BU_:  Airbag BAP_Tester ICAS1_Gateway ICAS1_KommunikationsServer LE1 LE2 Motor_BEV Schaltbetaetigung

BU_:  Airbag BAP_Tester ICAS1_Gateway ICAS1_KommunikationsServer LE1 LE2 Motor_BEV Schaltbetaetigung

BO_ 333 ACC_18: 32 ICAS1_Gateway
 SG_ ACC_18_CRC  : 0|8@1+ (1.000000,0.000000) [0.000000|255.000000] "" Motor_BEV
 SG_ ACC_18_BZ  : 8|4@1+ (1.000000,0.000000) [0.000000|15.000000] "" Motor_BEV
 SG_ ACC_limitierte_Anfahrdyn  : 12|1@0- (1.000000,0.000000) [0.000000|1.000000] "" Motor_BEV
 SG_ ACC_nachtr_Stopp_Anf  : 13|1@1+ (1.000000,0.000000) [0.000000|1.000000] "" Vector__XXX
 SG_ ACC_DynErhoehung  : 14|1@1+ (1.000000,0.000000) [0.000000|1.000000] "" Motor_BEV
 SG_ ACC_Freilaufstrategie_TSK  : 15|1@1+ (1.000000,0.000000) [0.000000|1.000000] "" Motor_BEV
 SG_ ACC_zul_Regelabw_unten  : 16|6@1+ (0.024000,0.000000) [0.000000|1.512000] "Unit_MeterPerSeconSquar" Motor_BEV
 SG_ ACC_StartStopp_Info  : 22|2@1+ (1.000000,0.000000) [0.000000|3.000000] "" Vector__XXX
 SG_ ACC_Sollbeschleunigung_02  : 24|11@1+ (0.005000,-7.220000) [-7.220000|3.005000] "Unit_MeterPerSeconSquar" Motor_BEV
 SG_ ACC_zul_Regelabw_oben  : 35|5@1+ (0.062500,0.000000) [0.000000|1.937500] "Unit_MeterPerSeconSquar" Motor_BEV
 SG_ ACC_neg_Sollbeschl_Grad_02  : 40|8@1+ (0.050000,0.000000) [0.000000|12.750000] "Unit_MeterPerCubicSecon" Motor_BEV
 SG_ ACC_pos_Sollbeschl_Grad_02  : 48|8@1+ (0.050000,0.000000) [0.000000|12.750000] "Unit_MeterPerCubicSecon" Motor_BEV
 SG_ ACC_Anfahren  : 56|1@1+ (1.000000,0.000000) [0.000000|1.000000] "" Motor_BEV
 SG_ ACC_Anhalten  : 57|1@1+ (1.000000,0.000000) [0.000000|1.000000] "" Motor_BEV
 SG_ ACC_Typ  : 58|2@1+ (1.000000,0.000000) [0.000000|3.000000] "" Motor_BEV
 SG_ ACC_Status_ACC  : 60|3@1+ (1.000000,0.000000) [0.000000|7.000000] "" Motor_BEV
 SG_ ACC_Minimale_Bremsung  : 63|1@1+ (1.000000,0.000000) [0.000000|1.000000] "" Motor_BEV
 SG_ ACC_Anhalteweg  : 64|11@1+ (0.010000,0.000000) [0.000000|20.450000] "Unit_Meter" Vector__XXX
 SG_ ACC_Boost  : 75|1@1+ (1.000000,0.000000) [0.000000|1.000000] "" Vector__XXX
 SG_ ACC_Freilauf_Anf  : 76|1@1+ (1.000000,0.000000) [0.000000|1.000000] "" Vector__XXX
 SG_ ACC_Anforderung_HMS  : 77|3@1+ (1.000000,0.000000) [0.000000|7.000000] "" Vector__XXX
 SG_ ACC_Folgebeschl  : 80|8@1+ (0.030000,-4.600000) [-4.600000|2.990000] "Unit_MeterPerSeconSquar" Motor_BEV
 SG_ ACC_Freilauf_Info  : 88|2@1+ (1.000000,0.000000) [0.000000|3.000000] "" Motor_BEV
 SG_ ACC_Tempolimitassistent_Ein  : 90|1@1+ (1.000000,0.000000) [0.000000|1.000000] "" Vector__XXX
 SG_ ACC_FoD_Status  : 91|2@1+ (1.000000,0.000000) [0.000000|3.000000] "" Motor_BEV
 SG_ vESC_Verz_Anf  : 232|4@1+ (0.500000,0.000000) [0.000000|3.500000] "Unit_MeterPerSeconSquar" Vector__XXX
 SG_ RDR_v_ueber_Grund  : 236|12@1+ (0.100000,0.000000) [0.000000|409.000000] "Unit_KiloMeterPerHour" Vector__XXX
 SG_ RDR_v_ueber_Grund_Genauigkeit  : 248|6@1+ (0.100000,0.000000) [0.000000|6.000000] "Unit_KiloMeterPerHour" Vector__XXX
 SG_ RDR_v_ueber_Grund_Fahrtrichtung  : 254|2@1+ (1.000000,0.000000) [0.000000|3.000000] "" Vector__XXX

BO_ 2527679682 ACC_ASM_01: 8 ICAS1_Gateway
 SG_ ACC_ASM_Ereignis  : 0|8@1+ (1.000000,0.000000) [1.000000|254.000000] "" Airbag
 SG_ ACC_ASM_Zeitstempel  : 8|8@1+ (0.080000,0.000000) [0.000000|20.320000] "Unit_Secon" Airbag
 SG_ ACC_ASM_Data_1  : 16|8@1+ (1.000000,0.000000) [0.000000|255.000000] "" Airbag
 SG_ ACC_ASM_Data_2  : 24|8@1+ (1.000000,0.000000) [0.000000|255.000000] "" Airbag
 SG_ ACC_ASM_Data_3  : 32|8@1+ (1.000000,0.000000) [0.000000|255.000000] "" Airbag
 SG_ ACC_ASM_Data_4  : 40|8@1+ (1.000000,0.000000) [0.000000|255.000000] "" Airbag
 SG_ ACC_ASM_Data_5  : 48|8@1+ (1.000000,0.000000) [0.000000|255.000000] "" Airbag
 SG_ ACC_ASM_Data_6  : 56|8@1+ (1.000000,0.000000) [0.000000|255.000000] "" Airbag

BO_ 64 Airbag_01: 8 Airbag
 SG_ Airbag_01_CRC  : 0|8@1+ (1.000000,0.000000) [0.000000|255.000000] "" ICAS1_Gateway LE1 LE2 Motor_BEV
 SG_ Airbag_01_BZ  : 8|4@1+ (1.000000,0.000000) [0.000000|15.000000] "" ICAS1_Gateway LE1 LE2 Motor_BEV
 SG_ AB_RGS_Anst  : 12|4@1+ (1.000000,0.000000) [0.000000|15.000000] "" ICAS1_Gateway ICAS1_KommunikationsServer
 SG_ AB_Front_Crash  : 16|1@1+ (1.000000,0.000000) [0.000000|1.000000] "" ICAS1_Gateway
 SG_ AB_Heck_Crash  : 17|1@1+ (1.000000,0.000000) [0.000000|1.000000] "" ICAS1_Gateway
 SG_ AB_SF_Crash  : 18|1@1+ (1.000000,0.000000) [0.000000|1.000000] "" ICAS1_Gateway
 SG_ AB_SB_Crash  : 19|1@1+ (1.000000,0.000000) [0.000000|1.000000] "" ICAS1_Gateway
 SG_ AB_Rollover_Crash  : 20|1@1+ (1.000000,0.000000) [0.000000|1.000000] "" ICAS1_Gateway
 SG_ AB_Crash_Int  : 21|3@1+ (1.000000,0.000000) [0.000000|7.000000] "" ICAS1_Gateway ICAS1_KommunikationsServer Motor_BEV
 SG_ AB_Lampe  : 24|1@1+ (1.000000,0.000000) [0.000000|1.000000] "" ICAS1_Gateway ICAS1_KommunikationsServer
 SG_ AB_Deaktiviert  : 25|1@1+ (1.000000,0.000000) [0.000000|1.000000] "" ICAS1_Gateway
 SG_ AB_VB_deaktiviert  : 26|1@1+ (1.000000,0.000000) [0.000000|1.000000] "" ICAS1_Gateway
 SG_ AB_Systemfehler  : 27|1@1+ (1.000000,0.000000) [0.000000|1.000000] "" ICAS1_Gateway ICAS1_KommunikationsServer
 SG_ AB_Diagnose  : 28|1@1+ (1.000000,0.000000) [0.000000|1.000000] "" ICAS1_Gateway
 SG_ AB_Stellgliedtest  : 29|1@1+ (1.000000,0.000000) [0.000000|1.000000] "" ICAS1_Gateway
 SG_ AB_Erh_Auf_VB  : 30|2@1+ (1.000000,0.000000) [0.000000|3.000000] "" ICAS1_Gateway
 SG_ AB_Gurtwarn_VF  : 32|1@1+ (1.000000,0.000000) [0.000000|1.000000] "" ICAS1_Gateway ICAS1_KommunikationsServer
 SG_ AB_Gurtwarn_VB  : 33|1@1+ (1.000000,0.000000) [0.000000|1.000000] "" ICAS1_Gateway ICAS1_KommunikationsServer
 SG_ AB_Anzeige_Fussg  : 34|2@1+ (1.000000,0.000000) [0.000000|3.000000] "" ICAS1_Gateway
 SG_ AB_Texte_AKS  : 36|2@1+ (1.000000,0.000000) [0.000000|3.000000] "" ICAS1_Gateway
 SG_ AB_PAO_Leuchte_Anf  : 38|1@1+ (1.000000,0.000000) [0.000000|1.000000] "" ICAS1_Gateway
 SG_ AB_MKB_gueltig  : 39|1@1+ (1.000000,0.000000) [0.000000|1.000000] "" ICAS1_Gateway
 SG_ AB_MKB_Anforderung  : 40|1@1+ (1.000000,0.000000) [0.000000|1.000000] "" ICAS1_Gateway
 SG_ AB_Versorgungsspannung  : 41|1@1+ (1.000000,0.000000) [0.000000|1.000000] "" ICAS1_Gateway
 SG_ AB_Deaktivierung_HV  : 42|3@1+ (1.000000,0.000000) [0.000000|7.000000] "" ICAS1_Gateway ICAS1_KommunikationsServer LE1 LE2 Motor_BEV
 SG_ AB_EDR_Trigger  : 45|2@1+ (1.000000,0.000000) [0.000000|3.000000] "" ICAS1_Gateway
 SG_ AB_Belegung_VF  : 47|2@1+ (1.000000,0.000000) [0.000000|3.000000] "" ICAS1_Gateway
 SG_ AB_Gurtschloss_FA_ext  : 49|3@1+ (1.000000,0.000000) [0.000000|7.000000] "" ICAS1_Gateway
 SG_ AB_Belegung_VF_ext  : 52|3@1+ (1.000000,0.000000) [0.000000|7.000000] "" ICAS1_Gateway
 SG_ ASM_Masterzeit  : 56|8@1+ (0.080000,0.000000) [0.000000|20.320000] "Unit_Secon" ICAS1_Gateway

BO_ 1312 Airbag_02: 8 Airbag
 SG_ Airbag_02_CRC  : 0|8@1+ (1.000000,0.000000) [0.000000|255.000000] "" ICAS1_Gateway Motor_BEV
 SG_ Airbag_02_BZ  : 8|4@1+ (1.000000,0.000000) [0.000000|15.000000] "" ICAS1_Gateway Motor_BEV
 SG_ LoGeWa_Event_Kombiwarnung  : 12|4@1+ (1.000000,0.000000) [0.000000|15.000000] "" ICAS1_Gateway
 SG_ AB_Anforderung_eCall  : 16|1@1+ (1.000000,0.000000) [0.000000|1.000000] "" ICAS1_Gateway
 SG_ AB_Anprall_Seite_Beifahrer  : 17|1@1+ (1.000000,0.000000) [0.000000|1.000000] "" ICAS1_Gateway ICAS1_KommunikationsServer
 SG_ AB_Anprall_Rollover  : 18|1@1+ (1.000000,0.000000) [0.000000|1.000000] "" ICAS1_Gateway ICAS1_KommunikationsServer
 SG_ AB_Anprall_FGS  : 19|1@1+ (1.000000,0.000000) [0.000000|1.000000] "" ICAS1_Gateway ICAS1_KommunikationsServer
 SG_ AB_Anprall_Front_Beifahrer  : 20|1@1+ (1.000000,0.000000) [0.000000|1.000000] "" ICAS1_Gateway ICAS1_KommunikationsServer
 SG_ AB_Anprall_Front_Fahrer  : 21|1@1+ (1.000000,0.000000) [0.000000|1.000000] "" ICAS1_Gateway ICAS1_KommunikationsServer
 SG_ AB_Anprall_Heck_Beifahrer  : 22|1@1+ (1.000000,0.000000) [0.000000|1.000000] "" ICAS1_Gateway ICAS1_KommunikationsServer
 SG_ AB_Anprall_Heck_Fahrer  : 23|1@1+ (1.000000,0.000000) [0.000000|1.000000] "" ICAS1_Gateway ICAS1_KommunikationsServer
 SG_ AB_Wickelklappung_Reihe2_MI  : 24|2@1+ (1.000000,0.000000) [0.000000|3.000000] "" ICAS1_Gateway
 SG_ AB_Belegung_VB  : 26|2@1+ (1.000000,0.000000) [0.000000|3.000000] "" ICAS1_Gateway
 SG_ AB_Abschaltanf_SIH_BF  : 28|1@1+ (1.000000,0.000000) [0.000000|1.000000] "" ICAS1_Gateway
 SG_ AB_Anprall_Seite_Fahrer  : 29|1@1+ (1.000000,0.000000) [0.000000|1.000000] "" ICAS1_Gateway ICAS1_KommunikationsServer
 SG_ SC_PAO_Schriftzug_Anf  : 30|2@1+ (1.000000,0.000000) [0.000000|3.000000] "" ICAS1_Gateway
 SG_ SC_PAO_ON_Anf  : 32|2@1+ (1.000000,0.000000) [0.000000|3.000000] "" ICAS1_Gateway
 SG_ SC_PAO_OFF_Anf  : 34|2@1+ (1.000000,0.000000) [0.000000|3.000000] "" ICAS1_Gateway
 SG_ AB_Crashschwere  : 36|3@1+ (1.000000,0.000000) [0.000000|7.000000] "" ICAS1_Gateway ICAS1_KommunikationsServer
 SG_ AB_Anforderung_USM  : 39|1@1+ (1.000000,0.000000) [0.000000|1.000000] "" ICAS1_Gateway
 SG_ AB_Gurtschloss_FA  : 40|2@1+ (1.000000,0.000000) [0.000000|3.000000] "" ICAS1_Gateway ICAS1_KommunikationsServer Motor_BEV
 SG_ AB_Gurtschloss_BF  : 42|2@1+ (1.000000,0.000000) [0.000000|3.000000] "" ICAS1_Gateway ICAS1_KommunikationsServer
 SG_ AB_Gurtschloss_Reihe2_FA  : 44|2@1+ (1.000000,0.000000) [0.000000|3.000000] "" ICAS1_Gateway ICAS1_KommunikationsServer
 SG_ AB_Gurtschloss_Reihe2_MI  : 46|2@1+ (1.000000,0.000000) [0.000000|3.000000] "" ICAS1_Gateway ICAS1_KommunikationsServer
 SG_ AB_Gurtschloss_Reihe2_BF  : 48|2@1+ (1.000000,0.000000) [0.000000|3.000000] "" ICAS1_Gateway ICAS1_KommunikationsServer
 SG_ AB_Gurtschloss_Reihe3_FA  : 50|2@1+ (1.000000,0.000000) [0.000000|3.000000] "" ICAS1_Gateway ICAS1_KommunikationsServer
 SG_ AB_Gurtschloss_Reihe3_MI  : 52|2@1+ (1.000000,0.000000) [0.000000|3.000000] "" ICAS1_Gateway ICAS1_KommunikationsServer
 SG_ AB_Gurtschloss_Reihe3_BF  : 54|2@1+ (1.000000,0.000000) [0.000000|3.000000] "" ICAS1_Gateway ICAS1_KommunikationsServer
 SG_ AB_Sitzpos_Sens_FA  : 56|2@1+ (1.000000,0.000000) [0.000000|3.000000] "" ICAS1_Gateway
 SG_ AB_Sitzpos_Sens_BF  : 58|2@1+ (1.000000,0.000000) [0.000000|3.000000] "" ICAS1_Gateway
 SG_ AB_Wickelklappung_Reihe2_BF  : 60|2@1+ (1.000000,0.000000) [0.000000|3.000000] "" ICAS1_Gateway
 SG_ AB_Wickelklappung_Reihe2_FA  : 62|2@1+ (1.000000,0.000000) [0.000000|3.000000] "" ICAS1_Gateway

BO_ 65 Airbag_03: 8 Airbag
 SG_ Airbag_03_CRC  : 0|8@1+ (1.000000,0.000000) [0.000000|255.000000] "" ICAS1_Gateway
 SG_ Airbag_03_BZ  : 8|4@1+ (1.000000,0.000000) [0.000000|15.000000] "" ICAS1_Gateway
 SG_ AB_MKB_Safing  : 63|1@1+ (1.000000,0.000000) [0.000000|1.000000] "" ICAS1_Gateway

BO_ 1349 Airbag_04: 8 Airbag
 SG_ AB_Gurtwarn_Reihe4_FA  : 14|2@1+ (1.000000,0.000000) [0.000000|3.000000] "" ICAS1_Gateway ICAS1_KommunikationsServer
 SG_ AB_Gurtwarn_Reihe4_BF  : 16|2@1+ (1.000000,0.000000) [0.000000|3.000000] "" ICAS1_Gateway ICAS1_KommunikationsServer
 SG_ AB_Gurtwarn_Reihe4_MI  : 18|2@1+ (1.000000,0.000000) [0.000000|3.000000] "" ICAS1_Gateway ICAS1_KommunikationsServer
 SG_ AB_Gurtwarn_Reihe2_FA  : 20|2@1+ (1.000000,0.000000) [0.000000|3.000000] "" ICAS1_Gateway ICAS1_KommunikationsServer
 SG_ AB_Gurtwarn_Reihe2_BF  : 22|2@1+ (1.000000,0.000000) [0.000000|3.000000] "" ICAS1_Gateway ICAS1_KommunikationsServer
 SG_ AbstWarn_MV_FAS_Fkt_Status  : 24|2@1+ (1.000000,0.000000) [0.000000|3.000000] "" ICAS1_Gateway
 SG_ WarnBrems_Charisma_Status  : 26|2@1+ (1.000000,0.000000) [0.000000|3.000000] "" ICAS1_Gateway
 SG_ WarnBrems_Charisma_FahrPr  : 28|4@1+ (1.000000,0.000000) [0.000000|15.000000] "" ICAS1_Gateway
 SG_ AB_Gurtwarn_Reihe2_MI  : 32|2@1+ (1.000000,0.000000) [0.000000|3.000000] "" ICAS1_Gateway ICAS1_KommunikationsServer
 SG_ AB_Gurtwarn_Reihe3_FA  : 34|2@1+ (1.000000,0.000000) [0.000000|3.000000] "" ICAS1_Gateway ICAS1_KommunikationsServer
 SG_ AB_Gurtwarn_Reihe3_MI  : 36|2@1+ (1.000000,0.000000) [0.000000|3.000000] "" ICAS1_Gateway ICAS1_KommunikationsServer
 SG_ AB_Gurtwarn_Reihe3_BF  : 38|2@1+ (1.000000,0.000000) [0.000000|3.000000] "" ICAS1_Gateway ICAS1_KommunikationsServer
 SG_ LGI_FAS_Fkt_Status  : 40|2@1+ (1.000000,0.000000) [0.000000|3.000000] "" ICAS1_Gateway
 SG_ PreCrash_FAS_Fkt_Status  : 42|3@1+ (1.000000,0.000000) [0.000000|7.000000] "" ICAS1_Gateway
 SG_ AB_SBR_hinten_verbau  : 48|2@1+ (1.000000,0.000000) [0.000000|3.000000] "" ICAS1_Gateway ICAS1_KommunikationsServer
 SG_ AWV_Einstellung_System_ASG  : 51|1@1+ (1.000000,0.000000) [0.000000|1.000000] "" ICAS1_Gateway
 SG_ AWV_Einstellung_Warnung_ASG  : 52|3@1+ (1.000000,0.000000) [0.000000|7.000000] "" ICAS1_Gateway
 SG_ SC_PreSense_Modus_Warnung_NV  : 55|3@1+ (1.000000,0.000000) [0.000000|7.000000] "" ICAS1_Gateway
 SG_ SC_PreSense_Modus_Warnung_MV  : 58|3@1+ (1.000000,0.000000) [0.000000|7.000000] "" ICAS1_Gateway
 SG_ SC_PreSense_Modus_System_MV  : 61|1@1+ (1.000000,0.000000) [0.000000|1.000000] "" ICAS1_Gateway
 SG_ SC_PreSense_Modus_System_NV  : 62|1@1+ (1.000000,0.000000) [0.000000|1.000000] "" ICAS1_Gateway
 SG_ SC_PreSense_Modus_System_KAS  : 63|1@1+ (1.000000,0.000000) [0.000000|1.000000] "" ICAS1_Gateway

BO_ 2527679722 Airbag_06: 8 Airbag
 SG_ AB_Gurtschloss_Reihe4_FA  : 12|2@1+ (1.000000,0.000000) [0.000000|3.000000] "" ICAS1_Gateway ICAS1_KommunikationsServer
 SG_ AB_Gurtschloss_Reihe4_BF  : 14|2@1+ (1.000000,0.000000) [0.000000|3.000000] "" ICAS1_Gateway ICAS1_KommunikationsServer
 SG_ AB_Gurtschloss_Reihe4_MI  : 16|2@1+ (1.000000,0.000000) [0.000000|3.000000] "" ICAS1_Gateway ICAS1_KommunikationsServer

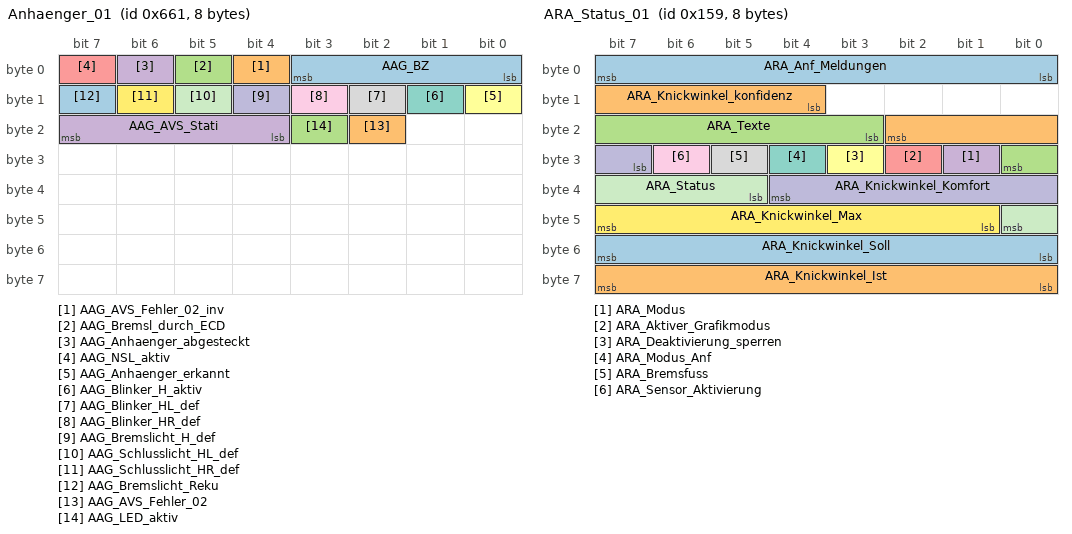
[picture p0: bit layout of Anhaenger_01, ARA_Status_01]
BO_ 1633 Anhaenger_01: 8 ICAS1_Gateway
 SG_ AAG_BZ  : 0|4@1+ (1.000000,0.000000) [0.000000|15.000000] "" Vector__XXX
 SG_ AAG_AVS_Fehler_02_inv  : 4|1@1+ (1.000000,0.000000) [0.000000|1.000000] "" Vector__XXX
 SG_ AAG_Bremsl_durch_ECD  : 5|1@1+ (1.000000,0.000000) [0.000000|1.000000] "" Motor_BEV
 SG_ AAG_Anhaenger_abgesteckt  : 6|1@1+ (1.000000,0.000000) [0.000000|1.000000] "" Motor_BEV
 SG_ AAG_NSL_aktiv  : 7|1@1+ (1.000000,0.000000) [0.000000|1.000000] "" Vector__XXX
 SG_ AAG_Anhaenger_erkannt  : 8|1@1+ (1.000000,0.000000) [0.000000|1.000000] "" Motor_BEV
 SG_ AAG_Blinker_H_aktiv  : 9|1@1+ (1.000000,0.000000) [0.000000|1.000000] "" Vector__XXX
 SG_ AAG_Blinker_HL_def  : 10|1@1+ (1.000000,0.000000) [0.000000|1.000000] "" Vector__XXX
 SG_ AAG_Blinker_HR_def  : 11|1@1+ (1.000000,0.000000) [0.000000|1.000000] "" Vector__XXX
 SG_ AAG_Bremslicht_H_def  : 12|1@1+ (1.000000,0.000000) [0.000000|1.000000] "" Motor_BEV
 SG_ AAG_Schlusslicht_HL_def  : 13|1@1+ (1.000000,0.000000) [0.000000|1.000000] "" Vector__XXX
 SG_ AAG_Schlusslicht_HR_def  : 14|1@1+ (1.000000,0.000000) [0.000000|1.000000] "" Vector__XXX
 SG_ AAG_Bremslicht_Reku  : 15|1@1+ (1.000000,0.000000) [0.000000|1.000000] "" Vector__XXX
 SG_ AAG_AVS_Fehler_02  : 18|1@1+ (1.000000,0.000000) [0.000000|1.000000] "" Vector__XXX
 SG_ AAG_LED_aktiv  : 19|1@1+ (1.000000,0.000000) [0.000000|1.000000] "" Vector__XXX
 SG_ AAG_AVS_Stati  : 20|4@1+ (1.000000,0.000000) [0.000000|15.000000] "" Vector__XXX

BO_ 345 ARA_Status_01: 8 ICAS1_Gateway
 SG_ ARA_Anf_Meldungen  : 0|8@1+ (1.000000,0.000000) [0.000000|255.000000] "" Vector__XXX
 SG_ ARA_Knickwinkel_konfidenz  : 12|7@1+ (1.000000,0.000000) [0.000000|120.000000] "Unit_DegreOfArc" Vector__XXX
 SG_ ARA_Texte  : 19|6@1+ (1.000000,0.000000) [0.000000|63.000000] "" Vector__XXX
 SG_ ARA_Modus  : 25|1@1+ (1.000000,0.000000) [0.000000|1.000000] "" Vector__XXX
 SG_ ARA_Aktiver_Grafikmodus  : 26|1@1+ (1.000000,0.000000) [0.000000|1.000000] "" Vector__XXX
 SG_ ARA_Deaktivierung_sperren  : 27|1@1+ (1.000000,0.000000) [0.000000|1.000000] "" Vector__XXX
 SG_ ARA_Modus_Anf  : 28|1@1+ (1.000000,0.000000) [0.000000|1.000000] "" Vector__XXX
 SG_ ARA_Bremsfuss  : 29|1@1+ (1.000000,0.000000) [0.000000|1.000000] "" Vector__XXX
 SG_ ARA_Sensor_Aktivierung  : 30|1@1+ (1.000000,0.000000) [0.000000|1.000000] "" Vector__XXX
 SG_ ARA_Knickwinkel_Komfort  : 31|6@1+ (1.000000,0.000000) [0.000000|60.000000] "Unit_DegreOfArc" Vector__XXX
 SG_ ARA_Status  : 37|4@1+ (1.000000,0.000000) [0.000000|15.000000] "" Motor_BEV
 SG_ ARA_Knickwinkel_Max  : 41|7@1+ (1.000000,0.000000) [0.000000|120.000000] "Unit_DegreOfArc" Vector__XXX
 SG_ ARA_Knickwinkel_Soll  : 48|8@1+ (1.000000,-125.000000) [-125.000000|126.000000] "Unit_DegreOfArc" Vector__XXX
 SG_ ARA_Knickwinkel_Ist  : 56|8@1+ (1.000000,-125.000000) [-125.000000|126.000000] "Unit_DegreOfArc" Vector__XXX

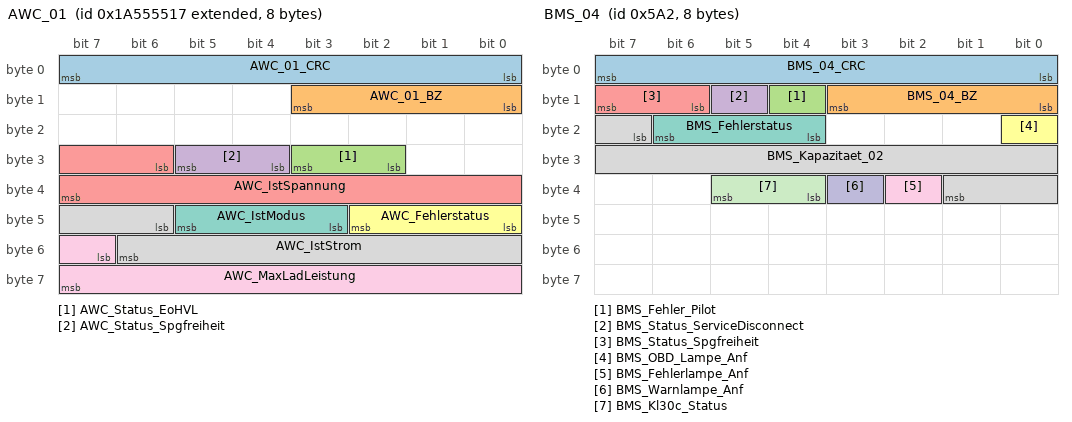
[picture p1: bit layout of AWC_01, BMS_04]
BO_ 2589283607 AWC_01: 8 ICAS1_Gateway
 SG_ AWC_01_CRC  : 0|8@1+ (1.000000,0.000000) [0.000000|255.000000] "" Vector__XXX
 SG_ AWC_01_BZ  : 8|4@1+ (1.000000,0.000000) [0.000000|15.000000] "" Vector__XXX
 SG_ AWC_Status_EoHVL  : 26|2@1+ (1.000000,0.000000) [0.000000|3.000000] "" Motor_BEV
 SG_ AWC_Status_Spgfreiheit  : 28|2@1+ (1.000000,0.000000) [0.000000|3.000000] "" Vector__XXX
 SG_ AWC_IstSpannung  : 30|10@1+ (1.000000,0.000000) [0.000000|1021.000000] "Unit_Volt" Vector__XXX
 SG_ AWC_Fehlerstatus  : 40|3@1+ (1.000000,0.000000) [0.000000|7.000000] "" Vector__XXX
 SG_ AWC_IstModus  : 43|3@1+ (1.000000,0.000000) [0.000000|7.000000] "" Vector__XXX
 SG_ AWC_IstStrom  : 46|9@1+ (0.100000,0.000000) [0.000000|50.900000] "Unit_Amper" Vector__XXX
 SG_ AWC_MaxLadLeistung  : 55|9@1+ (25.000000,0.000000) [0.000000|12725.000000] "Unit_Watt" Vector__XXX

BO_ 219 AWV_03: 48 ICAS1_Gateway
 SG_ AWV_03_CRC  : 0|8@1+ (1.000000,0.000000) [0.000000|255.000000] "" Airbag
 SG_ AWV_03_BZ  : 8|4@1+ (1.000000,0.000000) [0.000000|15.000000] "" Airbag
 SG_ PCF_Freigabe  : 12|1@1+ (1.000000,0.000000) [0.000000|1.000000] "" Airbag
 SG_ SDF_PSF_Objektstatus  : 13|3@1+ (1.000000,0.000000) [0.000000|7.000000] "" Airbag
 SG_ SDF_PSF_CU_Status  : 16|1@1+ (1.000000,0.000000) [0.000000|1.000000] "" Airbag
 SG_ SDF_PSF_CW  : 17|7@1+ (1.000000,0.000000) [0.000000|100.000000] "" Airbag
 SG_ SDF_PSF_Fahrer_aktiv  : 24|1@1+ (1.000000,0.000000) [0.000000|1.000000] "" Airbag
 SG_ SDF_PSF_Guete  : 25|2@1+ (1.000000,0.000000) [0.000000|3.000000] "" Airbag
 SG_ SDF_PSF_Kollisionsueberdeckung  : 27|5@1+ (0.100000,0.000000) [0.100000|2.800000] "Unit_Meter" Airbag
 SG_ SDF_PSF_Time_To_Collision  : 32|8@1+ (0.010000,0.000000) [0.000000|2.500000] "Unit_Secon" Vector__XXX
 SG_ SDF_PSF_v_rel  : 40|8@1+ (0.400000,0.000000) [0.400000|101.200000] "Unit_MeterPerSecon" Airbag
 SG_ AWV_Eingriff_Sendeart  : 64|1@1+ (1.000000,0.000000) [0.000000|1.000000] "" Airbag
 SG_ AWV_Verz_Freigabe  : 65|1@1+ (1.000000,0.000000) [0.000000|1.000000] "" Airbag
 SG_ AWV_Verz_Anf  : 66|10@1+ (0.024000,-20.016000) [-20.016000|4.512000] "Unit_MeterPerSeconSquar" Airbag
 SG_ AWV_Anf_Prefill  : 76|1@1+ (1.000000,0.000000) [0.000000|1.000000] "" Airbag
 SG_ AWV_Ruckprofil  : 77|3@1+ (1.000000,0.000000) [0.000000|7.000000] "" Vector__XXX
 SG_ AWV_Time_to_collision  : 80|8@1+ (0.010000,0.000000) [0.000000|2.500000] "Unit_Secon" Airbag
 SG_ AWV_HBA_Param  : 88|2@1+ (1.000000,0.000000) [0.000000|3.000000] "" Vector__XXX
 SG_ AWV_Verz_Anf_ASIL  : 90|3@1+ (1.000000,0.000000) [0.000000|7.000000] "" Vector__XXX
 SG_ AWV_Time_to_brake  : 93|7@1+ (10.000000,0.000000) [0.000000|1240.000000] "Unit_MilliSecon" Vector__XXX
 SG_ AWV_Zielobjekttyp  : 100|4@1+ (1.000000,0.000000) [0.000000|15.000000] "" Airbag
 SG_ AWV_QFK_KruemmSoll  : 104|15@1+ (0.000007,0.000000) [0.000000|0.219539] "Unit_MeterInver" Vector__XXX
 SG_ AWV_QFK_KruemmSoll_VZ  : 119|1@1+ (1.000000,0.000000) [0.000000|1.000000] "" Vector__XXX
 SG_ AWV_QFK_Spuerb  : 120|8@1+ (0.400000,0.000000) [0.000000|100.000000] "Unit_PerCent" Vector__XXX
 SG_ AWV_QFK_AnfStat  : 128|4@1+ (1.000000,0.000000) [0.000000|15.000000] "" Airbag
 SG_ AWV_QFK_Signal1  : 132|10@1+ (1.000000,0.000000) [0.000000|1023.000000] "" Vector__XXX
 SG_ AWV_QFK_Art1  : 142|3@1+ (1.000000,0.000000) [0.000000|7.000000] "" Vector__XXX
 SG_ AWV_QFK_Art2  : 145|3@1+ (1.000000,0.000000) [0.000000|7.000000] "" Vector__XXX
 SG_ AWV_QFK_Signal2  : 148|10@1+ (1.000000,0.000000) [0.000000|1023.000000] "" Vector__XXX

BO_ 2536767264 BAP_Debug_Cmd: 8 BAP_Tester
 SG_ BAP_Debug_Cmd  : 0|16@1+ (1.000000,0.000000) [0.000000|65535.000000] "" Motor_BEV

BO_ 2536767280 BAP_Debug_Data: 8 Motor_BEV
 SG_ BAP_Debug_Data  : 0|64@1+ (1.000000,0.000000) [0.000000|18446744073709551616.000000] "" BAP_Tester

BO_ 2536717313 BAP_EfficiencyAssist_ASG_02: 8 ICAS1_Gateway
 SG_ BAP_EfficAssist_ASG_02_Header  : 0|64@1+ (1.000000,0.000000) [0.000000|18446744073709551616.000000] "" Motor_BEV

BO_ 2536717314 BAP_EfficiencyAssist_ASG_03: 8 ICAS1_Gateway
 SG_ BAP_EfficAssist_ASG_03_Header  : 0|8@1+ (1.000000,0.000000) [0.000000|255.000000] "" Motor_BEV

BO_ 2536717328 BAP_EfficiencyAssist_FSG_01: 8 Motor_BEV
 SG_ BAP_EfficAssist_FSG_01_Header  : 0|8@1+ (1.000000,0.000000) [0.000000|255.000000] "" ICAS1_Gateway

BO_ 2536709120 BAP_Hybrid_ASG_01: 8 ICAS1_Gateway
 SG_ BAP_Hybrid_ASG_01_Header  : 0|8@1+ (1.000000,0.000000) [0.000000|255.000000] "" Motor_BEV

BO_ 2536709136 BAP_Hybrid_FSG_01: 8 Motor_BEV
 SG_ BAP_Hybrid_FSG_01_Header  : 0|8@1+ (1.000000,0.000000) [0.000000|255.000000] "" ICAS1_Gateway

BO_ 869 BEM_05: 8 ICAS1_Gateway
 SG_ BEM_UBDM  : 0|8@1+ (0.050000,5.000000) [5.050000|17.700000] "Unit_Volt" Vector__XXX
 SG_ NVEM_Ladefreigabe  : 8|2@1+ (1.000000,0.000000) [0.000000|3.000000] "" Vector__XXX
 SG_ NVEM_FMAus_Info  : 10|2@1+ (1.000000,0.000000) [0.000000|3.000000] "" Vector__XXX
 SG_ NVEM_PTC_Sollstufe  : 12|2@1+ (1.000000,0.000000) [0.000000|3.000000] "" Vector__XXX
 SG_ NVEM_P_Generator_Status  : 15|1@1+ (1.000000,0.000000) [0.000000|1.000000] "" Vector__XXX
 SG_ BEM_P_Generator  : 16|8@1+ (50.000000,0.000000) [0.000000|12700.000000] "Unit_Watt" Vector__XXX
 SG_ BEM_n_LLA  : 24|2@1+ (1.000000,0.000000) [0.000000|3.000000] "" Vector__XXX
 SG_ BEM_01_Abschaltstufen  : 26|3@1+ (1.000000,0.000000) [0.000000|7.000000] "" Vector__XXX
 SG_ BEM_Anf_KL  : 29|1@1+ (1.000000,0.000000) [0.000000|1.000000] "" Vector__XXX
 SG_ BEM_StartStopp_Info  : 30|2@1+ (1.000000,0.000000) [0.000000|3.000000] "" Vector__XXX
 SG_ BEM_DFM  : 32|5@1+ (3.225000,0.025000) [0.025000|100.000000] "" Vector__XXX
 SG_ BEM_EMLIN_ungueltig  : 37|1@1+ (1.000000,0.000000) [0.000000|1.000000] "" Vector__XXX
 SG_ BEM_Batt_Ab  : 38|1@1+ (1.000000,0.000000) [0.000000|1.000000] "" Motor_BEV
 SG_ NVEM_FMAus_I_Verbrauch  : 39|5@1+ (5.000000,0.000000) [0.000000|145.000000] "Unit_Amper" Vector__XXX
 SG_ NVEM_Freilauf_Info  : 44|2@1+ (1.000000,0.000000) [0.000000|3.000000] "" Vector__XXX
 SG_ BEM_NV_NachladAnf  : 46|2@1+ (1.000000,0.000000) [0.000000|3.000000] "" Vector__XXX
 SG_ BEM_Segel_Info  : 48|2@1+ (1.000000,0.000000) [0.000000|3.000000] "" Vector__XXX
 SG_ BEM_HYB_DC_uSollLV  : 50|6@1+ (0.100000,10.600000) [10.600000|16.000000] "Unit_Volt" Vector__XXX
 SG_ BEM_HYB_DC_uMinLV  : 56|8@1+ (0.100000,0.000000) [0.000000|25.300000] "Unit_Volt" Vector__XXX

BO_ 1442 BMS_04: 8 ICAS1_Gateway
 SG_ BMS_04_CRC  : 0|8@1+ (1.000000,0.000000) [0.000000|255.000000] "" Vector__XXX
 SG_ BMS_04_BZ  : 8|4@1+ (1.000000,0.000000) [0.000000|15.000000] "" Vector__XXX
 SG_ BMS_Fehler_Pilot  : 12|1@1+ (1.000000,0.000000) [0.000000|1.000000] "" Vector__XXX
 SG_ BMS_Status_ServiceDisconnect  : 13|1@1+ (1.000000,0.000000) [0.000000|1.000000] "" Vector__XXX
 SG_ BMS_Status_Spgfreiheit  : 14|2@1+ (1.000000,0.000000) [0.000000|3.000000] "" Motor_BEV
 SG_ BMS_OBD_Lampe_Anf  : 16|1@1+ (1.000000,0.000000) [0.000000|1.000000] "" Motor_BEV
 SG_ BMS_Fehlerstatus  : 20|3@1+ (1.000000,0.000000) [0.000000|7.000000] "" Vector__XXX
 SG_ BMS_Kapazitaet_02  : 23|11@1+ (0.200000,0.000000) [0.000000|409.200000] "Unit_AmperHour" Vector__XXX
 SG_ BMS_Fehlerlampe_Anf  : 34|1@1+ (1.000000,0.000000) [0.000000|1.000000] "" Motor_BEV
 SG_ BMS_Warnlampe_Anf  : 35|1@1+ (1.000000,0.000000) [0.000000|1.000000] "" Motor_BEV
 SG_ BMS_Kl30c_Status  : 36|2@1+ (1.000000,0.000000) [0.000000|3.000000] "" Motor_BEV

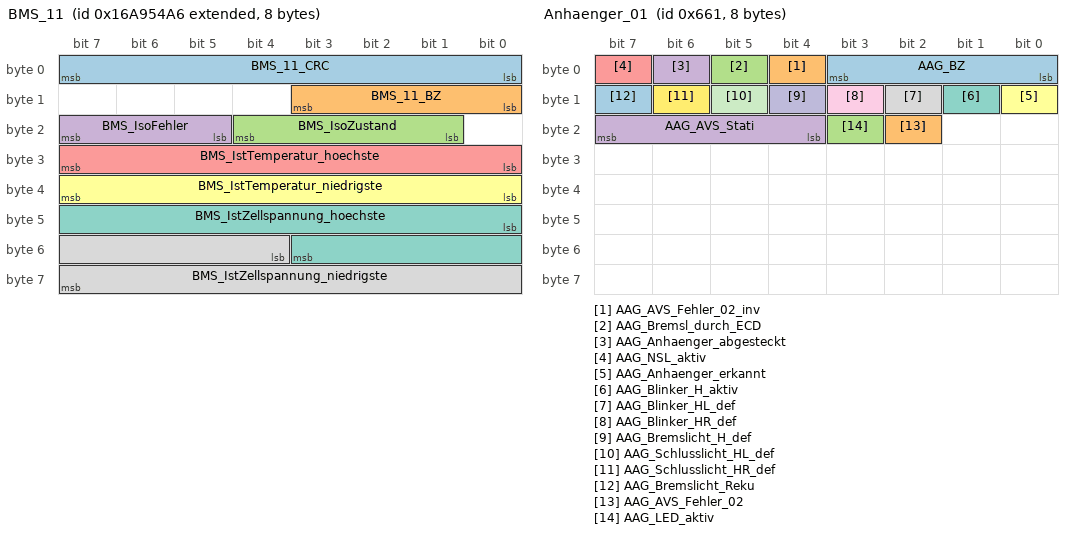
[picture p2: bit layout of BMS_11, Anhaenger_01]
BO_ 2527679654 BMS_11: 8 ICAS1_Gateway
 SG_ BMS_11_CRC  : 0|8@1+ (1.000000,0.000000) [0.000000|255.000000] "" Motor_BEV
 SG_ BMS_11_BZ  : 8|4@1+ (1.000000,0.000000) [0.000000|15.000000] "" Motor_BEV
 SG_ BMS_IsoZustand  : 17|4@1+ (1.000000,0.000000) [0.000000|15.000000] "" Motor_BEV
 SG_ BMS_IsoFehler  : 21|3@1+ (1.000000,0.000000) [0.000000|7.000000] "" Motor_BEV
 SG_ BMS_IstTemperatur_hoechste  : 24|8@1+ (0.500000,-40.000000) [-40.000000|86.000000] "Unit_DegreCelsi" Vector__XXX
 SG_ BMS_IstTemperatur_niedrigste  : 32|8@1+ (0.500000,-40.000000) [-40.000000|86.000000] "Unit_DegreCelsi" Vector__XXX
 SG_ BMS_IstZellspannung_hoechste  : 40|12@1+ (1.000000,1000.000000) [1000.000000|5091.000000] "Unit_MilliVolt" Vector__XXX
 SG_ BMS_IstZellspannung_niedrigste  : 52|12@1+ (1.000000,1000.000000) [1000.000000|5091.000000] "Unit_MilliVolt" Vector__XXX

BU_:  Airbag BAP_Tester ICAS1_Gateway ICAS1_KommunikationsServer LE1 LE2 Motor_BEV Schaltbetaetigung

BO_ 333 ACC_18: 32 ICAS1_Gateway
 SG_ ACC_18_CRC  : 0|8@1+ (1.000000,0.000000) [0.000000|255.000000] "" Motor_BEV
 SG_ ACC_18_BZ  : 8|4@1+ (1.000000,0.000000) [0.000000|15.000000] "" Motor_BEV
 SG_ ACC_limitierte_Anfahrdyn  : 12|1@0- (1.000000,0.000000) [0.000000|1.000000] "" Motor_BEV
 SG_ ACC_nachtr_Stopp_Anf  : 13|1@1+ (1.000000,0.000000) [0.000000|1.000000] "" Vector__XXX
 SG_ ACC_DynErhoehung  : 14|1@1+ (1.000000,0.000000) [0.000000|1.000000] "" Motor_BEV
 SG_ ACC_Freilaufstrategie_TSK  : 15|1@1+ (1.000000,0.000000) [0.000000|1.000000] "" Motor_BEV
 SG_ ACC_zul_Regelabw_unten  : 16|6@1+ (0.024000,0.000000) [0.000000|1.512000] "Unit_MeterPerSeconSquar" Motor_BEV
 SG_ ACC_StartStopp_Info  : 22|2@1+ (1.000000,0.000000) [0.000000|3.000000] "" Vector__XXX
 SG_ ACC_Sollbeschleunigung_02  : 24|11@1+ (0.005000,-7.220000) [-7.220000|3.005000] "Unit_MeterPerSeconSquar" Motor_BEV
 SG_ ACC_zul_Regelabw_oben  : 35|5@1+ (0.062500,0.000000) [0.000000|1.937500] "Unit_MeterPerSeconSquar" Motor_BEV
 SG_ ACC_neg_Sollbeschl_Grad_02  : 40|8@1+ (0.050000,0.000000) [0.000000|12.750000] "Unit_MeterPerCubicSecon" Motor_BEV
 SG_ ACC_pos_Sollbeschl_Grad_02  : 48|8@1+ (0.050000,0.000000) [0.000000|12.750000] "Unit_MeterPerCubicSecon" Motor_BEV
 SG_ ACC_Anfahren  : 56|1@1+ (1.000000,0.000000) [0.000000|1.000000] "" Motor_BEV
 SG_ ACC_Anhalten  : 57|1@1+ (1.000000,0.000000) [0.000000|1.000000] "" Motor_BEV
 SG_ ACC_Typ  : 58|2@1+ (1.000000,0.000000) [0.000000|3.000000] "" Motor_BEV
 SG_ ACC_Status_ACC  : 60|3@1+ (1.000000,0.000000) [0.000000|7.000000] "" Motor_BEV
 SG_ ACC_Minimale_Bremsung  : 63|1@1+ (1.000000,0.000000) [0.000000|1.000000] "" Motor_BEV
 SG_ ACC_Anhalteweg  : 64|11@1+ (0.010000,0.000000) [0.000000|20.450000] "Unit_Meter" Vector__XXX
 SG_ ACC_Boost  : 75|1@1+ (1.000000,0.000000) [0.000000|1.000000] "" Vector__XXX
 SG_ ACC_Freilauf_Anf  : 76|1@1+ (1.000000,0.000000) [0.000000|1.000000] "" Vector__XXX
 SG_ ACC_Anforderung_HMS  : 77|3@1+ (1.000000,0.000000) [0.000000|7.000000] "" Vector__XXX
 SG_ ACC_Folgebeschl  : 80|8@1+ (0.030000,-4.600000) [-4.600000|2.990000] "Unit_MeterPerSeconSquar" Motor_BEV
 SG_ ACC_Freilauf_Info  : 88|2@1+ (1.000000,0.000000) [0.000000|3.000000] "" Motor_BEV
 SG_ ACC_Tempolimitassistent_Ein  : 90|1@1+ (1.000000,0.000000) [0.000000|1.000000] "" Vector__XXX
 SG_ ACC_FoD_Status  : 91|2@1+ (1.000000,0.000000) [0.000000|3.000000] "" Motor_BEV
 SG_ vESC_Verz_Anf  : 232|4@1+ (0.500000,0.000000) [0.000000|3.500000] "Unit_MeterPerSeconSquar" Vector__XXX
 SG_ RDR_v_ueber_Grund  : 236|12@1+ (0.100000,0.000000) [0.000000|409.000000] "Unit_KiloMeterPerHour" Vector__XXX
 SG_ RDR_v_ueber_Grund_Genauigkeit  : 248|6@1+ (0.100000,0.000000) [0.000000|6.000000] "Unit_KiloMeterPerHour" Vector__XXX
 SG_ RDR_v_ueber_Grund_Fahrtrichtung  : 254|2@1+ (1.000000,0.000000) [0.000000|3.000000] "" Vector__XXX

BO_ 2527679682 ACC_ASM_01: 8 ICAS1_Gateway
 SG_ ACC_ASM_Ereignis  : 0|8@1+ (1.000000,0.000000) [1.000000|254.000000] "" Airbag
 SG_ ACC_ASM_Zeitstempel  : 8|8@1+ (0.080000,0.000000) [0.000000|20.320000] "Unit_Secon" Airbag
 SG_ ACC_ASM_Data_1  : 16|8@1+ (1.000000,0.000000) [0.000000|255.000000] "" Airbag
 SG_ ACC_ASM_Data_2  : 24|8@1+ (1.000000,0.000000) [0.000000|255.000000] "" Airbag
 SG_ ACC_ASM_Data_3  : 32|8@1+ (1.000000,0.000000) [0.000000|255.000000] "" Airbag
 SG_ ACC_ASM_Data_4  : 40|8@1+ (1.000000,0.000000) [0.000000|255.000000] "" Airbag
 SG_ ACC_ASM_Data_5  : 48|8@1+ (1.000000,0.000000) [0.000000|255.000000] "" Airbag
 SG_ ACC_ASM_Data_6  : 56|8@1+ (1.000000,0.000000) [0.000000|255.000000] "" Airbag

BO_ 64 Airbag_01: 8 Airbag
 SG_ Airbag_01_CRC  : 0|8@1+ (1.000000,0.000000) [0.000000|255.000000] "" ICAS1_Gateway LE1 LE2 Motor_BEV
 SG_ Airbag_01_BZ  : 8|4@1+ (1.000000,0.000000) [0.000000|15.000000] "" ICAS1_Gateway LE1 LE2 Motor_BEV
 SG_ AB_RGS_Anst  : 12|4@1+ (1.000000,0.000000) [0.000000|15.000000] "" ICAS1_Gateway ICAS1_KommunikationsServer
 SG_ AB_Front_Crash  : 16|1@1+ (1.000000,0.000000) [0.000000|1.000000] "" ICAS1_Gateway
 SG_ AB_Heck_Crash  : 17|1@1+ (1.000000,0.000000) [0.000000|1.000000] "" ICAS1_Gateway
 SG_ AB_SF_Crash  : 18|1@1+ (1.000000,0.000000) [0.000000|1.000000] "" ICAS1_Gateway
 SG_ AB_SB_Crash  : 19|1@1+ (1.000000,0.000000) [0.000000|1.000000] "" ICAS1_Gateway
 SG_ AB_Rollover_Crash  : 20|1@1+ (1.000000,0.000000) [0.000000|1.000000] "" ICAS1_Gateway
 SG_ AB_Crash_Int  : 21|3@1+ (1.000000,0.000000) [0.000000|7.000000] "" ICAS1_Gateway ICAS1_KommunikationsServer Motor_BEV
 SG_ AB_Lampe  : 24|1@1+ (1.000000,0.000000) [0.000000|1.000000] "" ICAS1_Gateway ICAS1_KommunikationsServer
 SG_ AB_Deaktiviert  : 25|1@1+ (1.000000,0.000000) [0.000000|1.000000] "" ICAS1_Gateway
 SG_ AB_VB_deaktiviert  : 26|1@1+ (1.000000,0.000000) [0.000000|1.000000] "" ICAS1_Gateway
 SG_ AB_Systemfehler  : 27|1@1+ (1.000000,0.000000) [0.000000|1.000000] "" ICAS1_Gateway ICAS1_KommunikationsServer
 SG_ AB_Diagnose  : 28|1@1+ (1.000000,0.000000) [0.000000|1.000000] "" ICAS1_Gateway
 SG_ AB_Stellgliedtest  : 29|1@1+ (1.000000,0.000000) [0.000000|1.000000] "" ICAS1_Gateway
 SG_ AB_Erh_Auf_VB  : 30|2@1+ (1.000000,0.000000) [0.000000|3.000000] "" ICAS1_Gateway
 SG_ AB_Gurtwarn_VF  : 32|1@1+ (1.000000,0.000000) [0.000000|1.000000] "" ICAS1_Gateway ICAS1_KommunikationsServer
 SG_ AB_Gurtwarn_VB  : 33|1@1+ (1.000000,0.000000) [0.000000|1.000000] "" ICAS1_Gateway ICAS1_KommunikationsServer
 SG_ AB_Anzeige_Fussg  : 34|2@1+ (1.000000,0.000000) [0.000000|3.000000] "" ICAS1_Gateway
 SG_ AB_Texte_AKS  : 36|2@1+ (1.000000,0.000000) [0.000000|3.000000] "" ICAS1_Gateway
 SG_ AB_PAO_Leuchte_Anf  : 38|1@1+ (1.000000,0.000000) [0.000000|1.000000] "" ICAS1_Gateway
 SG_ AB_MKB_gueltig  : 39|1@1+ (1.000000,0.000000) [0.000000|1.000000] "" ICAS1_Gateway
 SG_ AB_MKB_Anforderung  : 40|1@1+ (1.000000,0.000000) [0.000000|1.000000] "" ICAS1_Gateway
 SG_ AB_Versorgungsspannung  : 41|1@1+ (1.000000,0.000000) [0.000000|1.000000] "" ICAS1_Gateway
 SG_ AB_Deaktivierung_HV  : 42|3@1+ (1.000000,0.000000) [0.000000|7.000000] "" ICAS1_Gateway ICAS1_KommunikationsServer LE1 LE2 Motor_BEV
 SG_ AB_EDR_Trigger  : 45|2@1+ (1.000000,0.000000) [0.000000|3.000000] "" ICAS1_Gateway
 SG_ AB_Belegung_VF  : 47|2@1+ (1.000000,0.000000) [0.000000|3.000000] "" ICAS1_Gateway
 SG_ AB_Gurtschloss_FA_ext  : 49|3@1+ (1.000000,0.000000) [0.000000|7.000000] "" ICAS1_Gateway
 SG_ AB_Belegung_VF_ext  : 52|3@1+ (1.000000,0.000000) [0.000000|7.000000] "" ICAS1_Gateway
 SG_ ASM_Masterzeit  : 56|8@1+ (0.080000,0.000000) [0.000000|20.320000] "Unit_Secon" ICAS1_Gateway

BO_ 1312 Airbag_02: 8 Airbag
 SG_ Airbag_02_CRC  : 0|8@1+ (1.000000,0.000000) [0.000000|255.000000] "" ICAS1_Gateway Motor_BEV
 SG_ Airbag_02_BZ  : 8|4@1+ (1.000000,0.000000) [0.000000|15.000000] "" ICAS1_Gateway Motor_BEV
 SG_ LoGeWa_Event_Kombiwarnung  : 12|4@1+ (1.000000,0.000000) [0.000000|15.000000] "" ICAS1_Gateway
 SG_ AB_Anforderung_eCall  : 16|1@1+ (1.000000,0.000000) [0.000000|1.000000] "" ICAS1_Gateway
 SG_ AB_Anprall_Seite_Beifahrer  : 17|1@1+ (1.000000,0.000000) [0.000000|1.000000] "" ICAS1_Gateway ICAS1_KommunikationsServer
 SG_ AB_Anprall_Rollover  : 18|1@1+ (1.000000,0.000000) [0.000000|1.000000] "" ICAS1_Gateway ICAS1_KommunikationsServer
 SG_ AB_Anprall_FGS  : 19|1@1+ (1.000000,0.000000) [0.000000|1.000000] "" ICAS1_Gateway ICAS1_KommunikationsServer
 SG_ AB_Anprall_Front_Beifahrer  : 20|1@1+ (1.000000,0.000000) [0.000000|1.000000] "" ICAS1_Gateway ICAS1_KommunikationsServer
 SG_ AB_Anprall_Front_Fahrer  : 21|1@1+ (1.000000,0.000000) [0.000000|1.000000] "" ICAS1_Gateway ICAS1_KommunikationsServer
 SG_ AB_Anprall_Heck_Beifahrer  : 22|1@1+ (1.000000,0.000000) [0.000000|1.000000] "" ICAS1_Gateway ICAS1_KommunikationsServer
 SG_ AB_Anprall_Heck_Fahrer  : 23|1@1+ (1.000000,0.000000) [0.000000|1.000000] "" ICAS1_Gateway ICAS1_KommunikationsServer
 SG_ AB_Wickelklappung_Reihe2_MI  : 24|2@1+ (1.000000,0.000000) [0.000000|3.000000] "" ICAS1_Gateway
 SG_ AB_Belegung_VB  : 26|2@1+ (1.000000,0.000000) [0.000000|3.000000] "" ICAS1_Gateway
 SG_ AB_Abschaltanf_SIH_BF  : 28|1@1+ (1.000000,0.000000) [0.000000|1.000000] "" ICAS1_Gateway
 SG_ AB_Anprall_Seite_Fahrer  : 29|1@1+ (1.000000,0.000000) [0.000000|1.000000] "" ICAS1_Gateway ICAS1_KommunikationsServer
 SG_ SC_PAO_Schriftzug_Anf  : 30|2@1+ (1.000000,0.000000) [0.000000|3.000000] "" ICAS1_Gateway
 SG_ SC_PAO_ON_Anf  : 32|2@1+ (1.000000,0.000000) [0.000000|3.000000] "" ICAS1_Gateway
 SG_ SC_PAO_OFF_Anf  : 34|2@1+ (1.000000,0.000000) [0.000000|3.000000] "" ICAS1_Gateway
 SG_ AB_Crashschwere  : 36|3@1+ (1.000000,0.000000) [0.000000|7.000000] "" ICAS1_Gateway ICAS1_KommunikationsServer
 SG_ AB_Anforderung_USM  : 39|1@1+ (1.000000,0.000000) [0.000000|1.000000] "" ICAS1_Gateway
 SG_ AB_Gurtschloss_FA  : 40|2@1+ (1.000000,0.000000) [0.000000|3.000000] "" ICAS1_Gateway ICAS1_KommunikationsServer Motor_BEV
 SG_ AB_Gurtschloss_BF  : 42|2@1+ (1.000000,0.000000) [0.000000|3.000000] "" ICAS1_Gateway ICAS1_KommunikationsServer
 SG_ AB_Gurtschloss_Reihe2_FA  : 44|2@1+ (1.000000,0.000000) [0.000000|3.000000] "" ICAS1_Gateway ICAS1_KommunikationsServer
 SG_ AB_Gurtschloss_Reihe2_MI  : 46|2@1+ (1.000000,0.000000) [0.000000|3.000000] "" ICAS1_Gateway ICAS1_KommunikationsServer
 SG_ AB_Gurtschloss_Reihe2_BF  : 48|2@1+ (1.000000,0.000000) [0.000000|3.000000] "" ICAS1_Gateway ICAS1_KommunikationsServer
 SG_ AB_Gurtschloss_Reihe3_FA  : 50|2@1+ (1.000000,0.000000) [0.000000|3.000000] "" ICAS1_Gateway ICAS1_KommunikationsServer
 SG_ AB_Gurtschloss_Reihe3_MI  : 52|2@1+ (1.000000,0.000000) [0.000000|3.000000] "" ICAS1_Gateway ICAS1_KommunikationsServer
 SG_ AB_Gurtschloss_Reihe3_BF  : 54|2@1+ (1.000000,0.000000) [0.000000|3.000000] "" ICAS1_Gateway ICAS1_KommunikationsServer
 SG_ AB_Sitzpos_Sens_FA  : 56|2@1+ (1.000000,0.000000) [0.000000|3.000000] "" ICAS1_Gateway
 SG_ AB_Sitzpos_Sens_BF  : 58|2@1+ (1.000000,0.000000) [0.000000|3.000000] "" ICAS1_Gateway
 SG_ AB_Wickelklappung_Reihe2_BF  : 60|2@1+ (1.000000,0.000000) [0.000000|3.000000] "" ICAS1_Gateway
 SG_ AB_Wickelklappung_Reihe2_FA  : 62|2@1+ (1.000000,0.000000) [0.000000|3.000000] "" ICAS1_Gateway

BO_ 65 Airbag_03: 8 Airbag
 SG_ Airbag_03_CRC  : 0|8@1+ (1.000000,0.000000) [0.000000|255.000000] "" ICAS1_Gateway
 SG_ Airbag_03_BZ  : 8|4@1+ (1.000000,0.000000) [0.000000|15.000000] "" ICAS1_Gateway
 SG_ AB_MKB_Safing  : 63|1@1+ (1.000000,0.000000) [0.000000|1.000000] "" ICAS1_Gateway

BO_ 1349 Airbag_04: 8 Airbag
 SG_ AB_Gurtwarn_Reihe4_FA  : 14|2@1+ (1.000000,0.000000) [0.000000|3.000000] "" ICAS1_Gateway ICAS1_KommunikationsServer
 SG_ AB_Gurtwarn_Reihe4_BF  : 16|2@1+ (1.000000,0.000000) [0.000000|3.000000] "" ICAS1_Gateway ICAS1_KommunikationsServer
 SG_ AB_Gurtwarn_Reihe4_MI  : 18|2@1+ (1.000000,0.000000) [0.000000|3.000000] "" ICAS1_Gateway ICAS1_KommunikationsServer
 SG_ AB_Gurtwarn_Reihe2_FA  : 20|2@1+ (1.000000,0.000000) [0.000000|3.000000] "" ICAS1_Gateway ICAS1_KommunikationsServer
 SG_ AB_Gurtwarn_Reihe2_BF  : 22|2@1+ (1.000000,0.000000) [0.000000|3.000000] "" ICAS1_Gateway ICAS1_KommunikationsServer
 SG_ AbstWarn_MV_FAS_Fkt_Status  : 24|2@1+ (1.000000,0.000000) [0.000000|3.000000] "" ICAS1_Gateway
 SG_ WarnBrems_Charisma_Status  : 26|2@1+ (1.000000,0.000000) [0.000000|3.000000] "" ICAS1_Gateway
 SG_ WarnBrems_Charisma_FahrPr  : 28|4@1+ (1.000000,0.000000) [0.000000|15.000000] "" ICAS1_Gateway
 SG_ AB_Gurtwarn_Reihe2_MI  : 32|2@1+ (1.000000,0.000000) [0.000000|3.000000] "" ICAS1_Gateway ICAS1_KommunikationsServer
 SG_ AB_Gurtwarn_Reihe3_FA  : 34|2@1+ (1.000000,0.000000) [0.000000|3.000000] "" ICAS1_Gateway ICAS1_KommunikationsServer
 SG_ AB_Gurtwarn_Reihe3_MI  : 36|2@1+ (1.000000,0.000000) [0.000000|3.000000] "" ICAS1_Gateway ICAS1_KommunikationsServer
 SG_ AB_Gurtwarn_Reihe3_BF  : 38|2@1+ (1.000000,0.000000) [0.000000|3.000000] "" ICAS1_Gateway ICAS1_KommunikationsServer
 SG_ LGI_FAS_Fkt_Status  : 40|2@1+ (1.000000,0.000000) [0.000000|3.000000] "" ICAS1_Gateway
 SG_ PreCrash_FAS_Fkt_Status  : 42|3@1+ (1.000000,0.000000) [0.000000|7.000000] "" ICAS1_Gateway
 SG_ AB_SBR_hinten_verbau  : 48|2@1+ (1.000000,0.000000) [0.000000|3.000000] "" ICAS1_Gateway ICAS1_KommunikationsServer
 SG_ AWV_Einstellung_System_ASG  : 51|1@1+ (1.000000,0.000000) [0.000000|1.000000] "" ICAS1_Gateway
 SG_ AWV_Einstellung_Warnung_ASG  : 52|3@1+ (1.000000,0.000000) [0.000000|7.000000] "" ICAS1_Gateway
 SG_ SC_PreSense_Modus_Warnung_NV  : 55|3@1+ (1.000000,0.000000) [0.000000|7.000000] "" ICAS1_Gateway
 SG_ SC_PreSense_Modus_Warnung_MV  : 58|3@1+ (1.000000,0.000000) [0.000000|7.000000] "" ICAS1_Gateway
 SG_ SC_PreSense_Modus_System_MV  : 61|1@1+ (1.000000,0.000000) [0.000000|1.000000] "" ICAS1_Gateway
 SG_ SC_PreSense_Modus_System_NV  : 62|1@1+ (1.000000,0.000000) [0.000000|1.000000] "" ICAS1_Gateway
 SG_ SC_PreSense_Modus_System_KAS  : 63|1@1+ (1.000000,0.000000) [0.000000|1.000000] "" ICAS1_Gateway

BO_ 2527679722 Airbag_06: 8 Airbag
 SG_ AB_Gurtschloss_Reihe4_FA  : 12|2@1+ (1.000000,0.000000) [0.000000|3.000000] "" ICAS1_Gateway ICAS1_KommunikationsServer
 SG_ AB_Gurtschloss_Reihe4_BF  : 14|2@1+ (1.000000,0.000000) [0.000000|3.000000] "" ICAS1_Gateway ICAS1_KommunikationsServer
 SG_ AB_Gurtschloss_Reihe4_MI  : 16|2@1+ (1.000000,0.000000) [0.000000|3.000000] "" ICAS1_Gateway ICAS1_KommunikationsServer

BO_ 1633 Anhaenger_01: 8 ICAS1_Gateway
 SG_ AAG_BZ  : 0|4@1+ (1.000000,0.000000) [0.000000|15.000000] "" Vector__XXX
 SG_ AAG_AVS_Fehler_02_inv  : 4|1@1+ (1.000000,0.000000) [0.000000|1.000000] "" Vector__XXX
 SG_ AAG_Bremsl_durch_ECD  : 5|1@1+ (1.000000,0.000000) [0.000000|1.000000] "" Motor_BEV
 SG_ AAG_Anhaenger_abgesteckt  : 6|1@1+ (1.000000,0.000000) [0.000000|1.000000] "" Motor_BEV
 SG_ AAG_NSL_aktiv  : 7|1@1+ (1.000000,0.000000) [0.000000|1.000000] "" Vector__XXX
 SG_ AAG_Anhaenger_erkannt  : 8|1@1+ (1.000000,0.000000) [0.000000|1.000000] "" Motor_BEV
 SG_ AAG_Blinker_H_aktiv  : 9|1@1+ (1.000000,0.000000) [0.000000|1.000000] "" Vector__XXX
 SG_ AAG_Blinker_HL_def  : 10|1@1+ (1.000000,0.000000) [0.000000|1.000000] "" Vector__XXX
 SG_ AAG_Blinker_HR_def  : 11|1@1+ (1.000000,0.000000) [0.000000|1.000000] "" Vector__XXX
 SG_ AAG_Bremslicht_H_def  : 12|1@1+ (1.000000,0.000000) [0.000000|1.000000] "" Motor_BEV
 SG_ AAG_Schlusslicht_HL_def  : 13|1@1+ (1.000000,0.000000) [0.000000|1.000000] "" Vector__XXX
 SG_ AAG_Schlusslicht_HR_def  : 14|1@1+ (1.000000,0.000000) [0.000000|1.000000] "" Vector__XXX
 SG_ AAG_Bremslicht_Reku  : 15|1@1+ (1.000000,0.000000) [0.000000|1.000000] "" Vector__XXX
 SG_ AAG_AVS_Fehler_02  : 18|1@1+ (1.000000,0.000000) [0.000000|1.000000] "" Vector__XXX
 SG_ AAG_LED_aktiv  : 19|1@1+ (1.000000,0.000000) [0.000000|1.000000] "" Vector__XXX
 SG_ AAG_AVS_Stati  : 20|4@1+ (1.000000,0.000000) [0.000000|15.000000] "" Vector__XXX

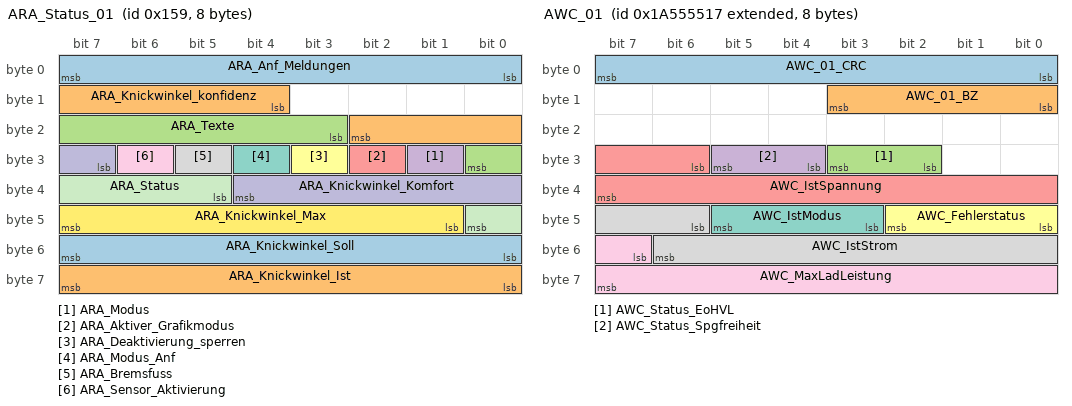
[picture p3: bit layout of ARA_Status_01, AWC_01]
BO_ 345 ARA_Status_01: 8 ICAS1_Gateway
 SG_ ARA_Anf_Meldungen  : 0|8@1+ (1.000000,0.000000) [0.000000|255.000000] "" Vector__XXX
 SG_ ARA_Knickwinkel_konfidenz  : 12|7@1+ (1.000000,0.000000) [0.000000|120.000000] "Unit_DegreOfArc" Vector__XXX
 SG_ ARA_Texte  : 19|6@1+ (1.000000,0.000000) [0.000000|63.000000] "" Vector__XXX
 SG_ ARA_Modus  : 25|1@1+ (1.000000,0.000000) [0.000000|1.000000] "" Vector__XXX
 SG_ ARA_Aktiver_Grafikmodus  : 26|1@1+ (1.000000,0.000000) [0.000000|1.000000] "" Vector__XXX
 SG_ ARA_Deaktivierung_sperren  : 27|1@1+ (1.000000,0.000000) [0.000000|1.000000] "" Vector__XXX
 SG_ ARA_Modus_Anf  : 28|1@1+ (1.000000,0.000000) [0.000000|1.000000] "" Vector__XXX
 SG_ ARA_Bremsfuss  : 29|1@1+ (1.000000,0.000000) [0.000000|1.000000] "" Vector__XXX
 SG_ ARA_Sensor_Aktivierung  : 30|1@1+ (1.000000,0.000000) [0.000000|1.000000] "" Vector__XXX
 SG_ ARA_Knickwinkel_Komfort  : 31|6@1+ (1.000000,0.000000) [0.000000|60.000000] "Unit_DegreOfArc" Vector__XXX
 SG_ ARA_Status  : 37|4@1+ (1.000000,0.000000) [0.000000|15.000000] "" Motor_BEV
 SG_ ARA_Knickwinkel_Max  : 41|7@1+ (1.000000,0.000000) [0.000000|120.000000] "Unit_DegreOfArc" Vector__XXX
 SG_ ARA_Knickwinkel_Soll  : 48|8@1+ (1.000000,-125.000000) [-125.000000|126.000000] "Unit_DegreOfArc" Vector__XXX
 SG_ ARA_Knickwinkel_Ist  : 56|8@1+ (1.000000,-125.000000) [-125.000000|126.000000] "Unit_DegreOfArc" Vector__XXX

BO_ 2589283607 AWC_01: 8 ICAS1_Gateway
 SG_ AWC_01_CRC  : 0|8@1+ (1.000000,0.000000) [0.000000|255.000000] "" Vector__XXX
 SG_ AWC_01_BZ  : 8|4@1+ (1.000000,0.000000) [0.000000|15.000000] "" Vector__XXX
 SG_ AWC_Status_EoHVL  : 26|2@1+ (1.000000,0.000000) [0.000000|3.000000] "" Motor_BEV
 SG_ AWC_Status_Spgfreiheit  : 28|2@1+ (1.000000,0.000000) [0.000000|3.000000] "" Vector__XXX
 SG_ AWC_IstSpannung  : 30|10@1+ (1.000000,0.000000) [0.000000|1021.000000] "Unit_Volt" Vector__XXX
 SG_ AWC_Fehlerstatus  : 40|3@1+ (1.000000,0.000000) [0.000000|7.000000] "" Vector__XXX
 SG_ AWC_IstModus  : 43|3@1+ (1.000000,0.000000) [0.000000|7.000000] "" Vector__XXX
 SG_ AWC_IstStrom  : 46|9@1+ (0.100000,0.000000) [0.000000|50.900000] "Unit_Amper" Vector__XXX
 SG_ AWC_MaxLadLeistung  : 55|9@1+ (25.000000,0.000000) [0.000000|12725.000000] "Unit_Watt" Vector__XXX

BO_ 219 AWV_03: 48 ICAS1_Gateway
 SG_ AWV_03_CRC  : 0|8@1+ (1.000000,0.000000) [0.000000|255.000000] "" Airbag
 SG_ AWV_03_BZ  : 8|4@1+ (1.000000,0.000000) [0.000000|15.000000] "" Airbag
 SG_ PCF_Freigabe  : 12|1@1+ (1.000000,0.000000) [0.000000|1.000000] "" Airbag
 SG_ SDF_PSF_Objektstatus  : 13|3@1+ (1.000000,0.000000) [0.000000|7.000000] "" Airbag
 SG_ SDF_PSF_CU_Status  : 16|1@1+ (1.000000,0.000000) [0.000000|1.000000] "" Airbag
 SG_ SDF_PSF_CW  : 17|7@1+ (1.000000,0.000000) [0.000000|100.000000] "" Airbag
 SG_ SDF_PSF_Fahrer_aktiv  : 24|1@1+ (1.000000,0.000000) [0.000000|1.000000] "" Airbag
 SG_ SDF_PSF_Guete  : 25|2@1+ (1.000000,0.000000) [0.000000|3.000000] "" Airbag
 SG_ SDF_PSF_Kollisionsueberdeckung  : 27|5@1+ (0.100000,0.000000) [0.100000|2.800000] "Unit_Meter" Airbag
 SG_ SDF_PSF_Time_To_Collision  : 32|8@1+ (0.010000,0.000000) [0.000000|2.500000] "Unit_Secon" Vector__XXX
 SG_ SDF_PSF_v_rel  : 40|8@1+ (0.400000,0.000000) [0.400000|101.200000] "Unit_MeterPerSecon" Airbag
 SG_ AWV_Eingriff_Sendeart  : 64|1@1+ (1.000000,0.000000) [0.000000|1.000000] "" Airbag
 SG_ AWV_Verz_Freigabe  : 65|1@1+ (1.000000,0.000000) [0.000000|1.000000] "" Airbag
 SG_ AWV_Verz_Anf  : 66|10@1+ (0.024000,-20.016000) [-20.016000|4.512000] "Unit_MeterPerSeconSquar" Airbag
 SG_ AWV_Anf_Prefill  : 76|1@1+ (1.000000,0.000000) [0.000000|1.000000] "" Airbag
 SG_ AWV_Ruckprofil  : 77|3@1+ (1.000000,0.000000) [0.000000|7.000000] "" Vector__XXX
 SG_ AWV_Time_to_collision  : 80|8@1+ (0.010000,0.000000) [0.000000|2.500000] "Unit_Secon" Airbag
 SG_ AWV_HBA_Param  : 88|2@1+ (1.000000,0.000000) [0.000000|3.000000] "" Vector__XXX
 SG_ AWV_Verz_Anf_ASIL  : 90|3@1+ (1.000000,0.000000) [0.000000|7.000000] "" Vector__XXX
 SG_ AWV_Time_to_brake  : 93|7@1+ (10.000000,0.000000) [0.000000|1240.000000] "Unit_MilliSecon" Vector__XXX
 SG_ AWV_Zielobjekttyp  : 100|4@1+ (1.000000,0.000000) [0.000000|15.000000] "" Airbag
 SG_ AWV_QFK_KruemmSoll  : 104|15@1+ (0.000007,0.000000) [0.000000|0.219539] "Unit_MeterInver" Vector__XXX
 SG_ AWV_QFK_KruemmSoll_VZ  : 119|1@1+ (1.000000,0.000000) [0.000000|1.000000] "" Vector__XXX
 SG_ AWV_QFK_Spuerb  : 120|8@1+ (0.400000,0.000000) [0.000000|100.000000] "Unit_PerCent" Vector__XXX
 SG_ AWV_QFK_AnfStat  : 128|4@1+ (1.000000,0.000000) [0.000000|15.000000] "" Airbag
 SG_ AWV_QFK_Signal1  : 132|10@1+ (1.000000,0.000000) [0.000000|1023.000000] "" Vector__XXX
 SG_ AWV_QFK_Art1  : 142|3@1+ (1.000000,0.000000) [0.000000|7.000000] "" Vector__XXX
 SG_ AWV_QFK_Art2  : 145|3@1+ (1.000000,0.000000) [0.000000|7.000000] "" Vector__XXX
 SG_ AWV_QFK_Signal2  : 148|10@1+ (1.000000,0.000000) [0.000000|1023.000000] "" Vector__XXX

BO_ 2536767264 BAP_Debug_Cmd: 8 BAP_Tester
 SG_ BAP_Debug_Cmd  : 0|16@1+ (1.000000,0.000000) [0.000000|65535.000000] "" Motor_BEV

BO_ 2536767280 BAP_Debug_Data: 8 Motor_BEV
 SG_ BAP_Debug_Data  : 0|64@1+ (1.000000,0.000000) [0.000000|18446744073709551616.000000] "" BAP_Tester

BO_ 2536717313 BAP_EfficiencyAssist_ASG_02: 8 ICAS1_Gateway
 SG_ BAP_EfficAssist_ASG_02_Header  : 0|64@1+ (1.000000,0.000000) [0.000000|18446744073709551616.000000] "" Motor_BEV

BO_ 2536717314 BAP_EfficiencyAssist_ASG_03: 8 ICAS1_Gateway
 SG_ BAP_EfficAssist_ASG_03_Header  : 0|8@1+ (1.000000,0.000000) [0.000000|255.000000] "" Motor_BEV

BO_ 2536717328 BAP_EfficiencyAssist_FSG_01: 8 Motor_BEV
 SG_ BAP_EfficAssist_FSG_01_Header  : 0|8@1+ (1.000000,0.000000) [0.000000|255.000000] "" ICAS1_Gateway

BO_ 2536709120 BAP_Hybrid_ASG_01: 8 ICAS1_Gateway
 SG_ BAP_Hybrid_ASG_01_Header  : 0|8@1+ (1.000000,0.000000) [0.000000|255.000000] "" Motor_BEV

BO_ 2536709136 BAP_Hybrid_FSG_01: 8 Motor_BEV
 SG_ BAP_Hybrid_FSG_01_Header  : 0|8@1+ (1.000000,0.000000) [0.000000|255.000000] "" ICAS1_Gateway

BO_ 869 BEM_05: 8 ICAS1_Gateway
 SG_ BEM_UBDM  : 0|8@1+ (0.050000,5.000000) [5.050000|17.700000] "Unit_Volt" Vector__XXX
 SG_ NVEM_Ladefreigabe  : 8|2@1+ (1.000000,0.000000) [0.000000|3.000000] "" Vector__XXX
 SG_ NVEM_FMAus_Info  : 10|2@1+ (1.000000,0.000000) [0.000000|3.000000] "" Vector__XXX
 SG_ NVEM_PTC_Sollstufe  : 12|2@1+ (1.000000,0.000000) [0.000000|3.000000] "" Vector__XXX
 SG_ NVEM_P_Generator_Status  : 15|1@1+ (1.000000,0.000000) [0.000000|1.000000] "" Vector__XXX
 SG_ BEM_P_Generator  : 16|8@1+ (50.000000,0.000000) [0.000000|12700.000000] "Unit_Watt" Vector__XXX
 SG_ BEM_n_LLA  : 24|2@1+ (1.000000,0.000000) [0.000000|3.000000] "" Vector__XXX
 SG_ BEM_01_Abschaltstufen  : 26|3@1+ (1.000000,0.000000) [0.000000|7.000000] "" Vector__XXX
 SG_ BEM_Anf_KL  : 29|1@1+ (1.000000,0.000000) [0.000000|1.000000] "" Vector__XXX
 SG_ BEM_StartStopp_Info  : 30|2@1+ (1.000000,0.000000) [0.000000|3.000000] "" Vector__XXX
 SG_ BEM_DFM  : 32|5@1+ (3.225000,0.025000) [0.025000|100.000000] "" Vector__XXX
 SG_ BEM_EMLIN_ungueltig  : 37|1@1+ (1.000000,0.000000) [0.000000|1.000000] "" Vector__XXX
 SG_ BEM_Batt_Ab  : 38|1@1+ (1.000000,0.000000) [0.000000|1.000000] "" Motor_BEV
 SG_ NVEM_FMAus_I_Verbrauch  : 39|5@1+ (5.000000,0.000000) [0.000000|145.000000] "Unit_Amper" Vector__XXX
 SG_ NVEM_Freilauf_Info  : 44|2@1+ (1.000000,0.000000) [0.000000|3.000000] "" Vector__XXX
 SG_ BEM_NV_NachladAnf  : 46|2@1+ (1.000000,0.000000) [0.000000|3.000000] "" Vector__XXX
 SG_ BEM_Segel_Info  : 48|2@1+ (1.000000,0.000000) [0.000000|3.000000] "" Vector__XXX
 SG_ BEM_HYB_DC_uSollLV  : 50|6@1+ (0.100000,10.600000) [10.600000|16.000000] "Unit_Volt" Vector__XXX
 SG_ BEM_HYB_DC_uMinLV  : 56|8@1+ (0.100000,0.000000) [0.000000|25.300000] "Unit_Volt" Vector__XXX

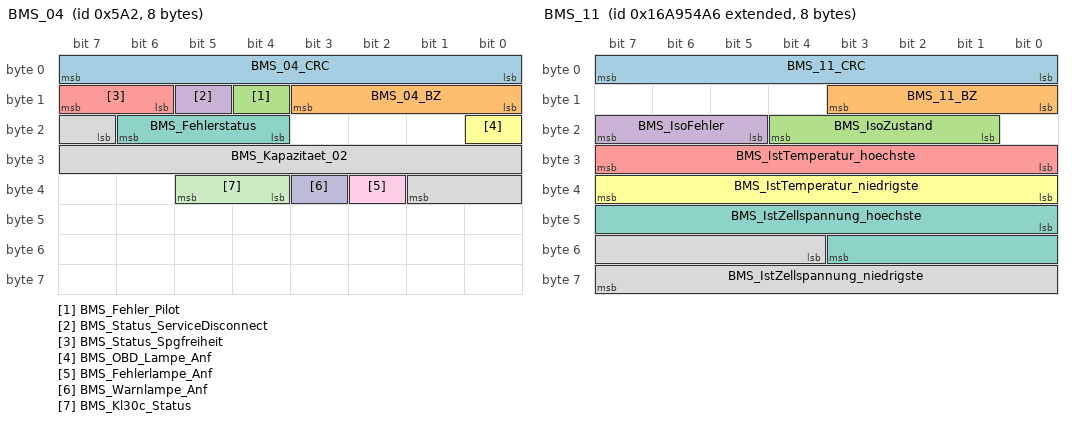
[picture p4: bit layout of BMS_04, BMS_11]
BO_ 1442 BMS_04: 8 ICAS1_Gateway
 SG_ BMS_04_CRC  : 0|8@1+ (1.000000,0.000000) [0.000000|255.000000] "" Vector__XXX
 SG_ BMS_04_BZ  : 8|4@1+ (1.000000,0.000000) [0.000000|15.000000] "" Vector__XXX
 SG_ BMS_Fehler_Pilot  : 12|1@1+ (1.000000,0.000000) [0.000000|1.000000] "" Vector__XXX
 SG_ BMS_Status_ServiceDisconnect  : 13|1@1+ (1.000000,0.000000) [0.000000|1.000000] "" Vector__XXX
 SG_ BMS_Status_Spgfreiheit  : 14|2@1+ (1.000000,0.000000) [0.000000|3.000000] "" Motor_BEV
 SG_ BMS_OBD_Lampe_Anf  : 16|1@1+ (1.000000,0.000000) [0.000000|1.000000] "" Motor_BEV
 SG_ BMS_Fehlerstatus  : 20|3@1+ (1.000000,0.000000) [0.000000|7.000000] "" Vector__XXX
 SG_ BMS_Kapazitaet_02  : 23|11@1+ (0.200000,0.000000) [0.000000|409.200000] "Unit_AmperHour" Vector__XXX
 SG_ BMS_Fehlerlampe_Anf  : 34|1@1+ (1.000000,0.000000) [0.000000|1.000000] "" Motor_BEV
 SG_ BMS_Warnlampe_Anf  : 35|1@1+ (1.000000,0.000000) [0.000000|1.000000] "" Motor_BEV
 SG_ BMS_Kl30c_Status  : 36|2@1+ (1.000000,0.000000) [0.000000|3.000000] "" Motor_BEV

BO_ 2527679654 BMS_11: 8 ICAS1_Gateway
 SG_ BMS_11_CRC  : 0|8@1+ (1.000000,0.000000) [0.000000|255.000000] "" Motor_BEV
 SG_ BMS_11_BZ  : 8|4@1+ (1.000000,0.000000) [0.000000|15.000000] "" Motor_BEV
 SG_ BMS_IsoZustand  : 17|4@1+ (1.000000,0.000000) [0.000000|15.000000] "" Motor_BEV
 SG_ BMS_IsoFehler  : 21|3@1+ (1.000000,0.000000) [0.000000|7.000000] "" Motor_BEV
 SG_ BMS_IstTemperatur_hoechste  : 24|8@1+ (0.500000,-40.000000) [-40.000000|86.000000] "Unit_DegreCelsi" Vector__XXX
 SG_ BMS_IstTemperatur_niedrigste  : 32|8@1+ (0.500000,-40.000000) [-40.000000|86.000000] "Unit_DegreCelsi" Vector__XXX
 SG_ BMS_IstZellspannung_hoechste  : 40|12@1+ (1.000000,1000.000000) [1000.000000|5091.000000] "Unit_MilliVolt" Vector__XXX
 SG_ BMS_IstZellspannung_niedrigste  : 52|12@1+ (1.000000,1000.000000) [1000.000000|5091.000000] "Unit_MilliVolt" Vector__XXX

BU_:  Airbag BAP_Tester ICAS1_Gateway ICAS1_KommunikationsServer LE1 LE2 Motor_BEV Schaltbetaetigung

BO_ 333 ACC_18: 32 ICAS1_Gateway
 SG_ ACC_18_CRC  : 0|8@1+ (1.000000,0.000000) [0.000000|255.000000] "" Motor_BEV
 SG_ ACC_18_BZ  : 8|4@1+ (1.000000,0.000000) [0.000000|15.000000] "" Motor_BEV
 SG_ ACC_limitierte_Anfahrdyn  : 12|1@0- (1.000000,0.000000) [0.000000|1.000000] "" Motor_BEV
 SG_ ACC_nachtr_Stopp_Anf  : 13|1@1+ (1.000000,0.000000) [0.000000|1.000000] "" Vector__XXX
 SG_ ACC_DynErhoehung  : 14|1@1+ (1.000000,0.000000) [0.000000|1.000000] "" Motor_BEV
 SG_ ACC_Freilaufstrategie_TSK  : 15|1@1+ (1.000000,0.000000) [0.000000|1.000000] "" Motor_BEV
 SG_ ACC_zul_Regelabw_unten  : 16|6@1+ (0.024000,0.000000) [0.000000|1.512000] "Unit_MeterPerSeconSquar" Motor_BEV
 SG_ ACC_StartStopp_Info  : 22|2@1+ (1.000000,0.000000) [0.000000|3.000000] "" Vector__XXX
 SG_ ACC_Sollbeschleunigung_02  : 24|11@1+ (0.005000,-7.220000) [-7.220000|3.005000] "Unit_MeterPerSeconSquar" Motor_BEV
 SG_ ACC_zul_Regelabw_oben  : 35|5@1+ (0.062500,0.000000) [0.000000|1.937500] "Unit_MeterPerSeconSquar" Motor_BEV
 SG_ ACC_neg_Sollbeschl_Grad_02  : 40|8@1+ (0.050000,0.000000) [0.000000|12.750000] "Unit_MeterPerCubicSecon" Motor_BEV
 SG_ ACC_pos_Sollbeschl_Grad_02  : 48|8@1+ (0.050000,0.000000) [0.000000|12.750000] "Unit_MeterPerCubicSecon" Motor_BEV
 SG_ ACC_Anfahren  : 56|1@1+ (1.000000,0.000000) [0.000000|1.000000] "" Motor_BEV
 SG_ ACC_Anhalten  : 57|1@1+ (1.000000,0.000000) [0.000000|1.000000] "" Motor_BEV
 SG_ ACC_Typ  : 58|2@1+ (1.000000,0.000000) [0.000000|3.000000] "" Motor_BEV
 SG_ ACC_Status_ACC  : 60|3@1+ (1.000000,0.000000) [0.000000|7.000000] "" Motor_BEV
 SG_ ACC_Minimale_Bremsung  : 63|1@1+ (1.000000,0.000000) [0.000000|1.000000] "" Motor_BEV
 SG_ ACC_Anhalteweg  : 64|11@1+ (0.010000,0.000000) [0.000000|20.450000] "Unit_Meter" Vector__XXX
 SG_ ACC_Boost  : 75|1@1+ (1.000000,0.000000) [0.000000|1.000000] "" Vector__XXX
 SG_ ACC_Freilauf_Anf  : 76|1@1+ (1.000000,0.000000) [0.000000|1.000000] "" Vector__XXX
 SG_ ACC_Anforderung_HMS  : 77|3@1+ (1.000000,0.000000) [0.000000|7.000000] "" Vector__XXX
 SG_ ACC_Folgebeschl  : 80|8@1+ (0.030000,-4.600000) [-4.600000|2.990000] "Unit_MeterPerSeconSquar" Motor_BEV
 SG_ ACC_Freilauf_Info  : 88|2@1+ (1.000000,0.000000) [0.000000|3.000000] "" Motor_BEV
 SG_ ACC_Tempolimitassistent_Ein  : 90|1@1+ (1.000000,0.000000) [0.000000|1.000000] "" Vector__XXX
 SG_ ACC_FoD_Status  : 91|2@1+ (1.000000,0.000000) [0.000000|3.000000] "" Motor_BEV
 SG_ vESC_Verz_Anf  : 232|4@1+ (0.500000,0.000000) [0.000000|3.500000] "Unit_MeterPerSeconSquar" Vector__XXX
 SG_ RDR_v_ueber_Grund  : 236|12@1+ (0.100000,0.000000) [0.000000|409.000000] "Unit_KiloMeterPerHour" Vector__XXX
 SG_ RDR_v_ueber_Grund_Genauigkeit  : 248|6@1+ (0.100000,0.000000) [0.000000|6.000000] "Unit_KiloMeterPerHour" Vector__XXX
 SG_ RDR_v_ueber_Grund_Fahrtrichtung  : 254|2@1+ (1.000000,0.000000) [0.000000|3.000000] "" Vector__XXX

BO_ 2527679682 ACC_ASM_01: 8 ICAS1_Gateway
 SG_ ACC_ASM_Ereignis  : 0|8@1+ (1.000000,0.000000) [1.000000|254.000000] "" Airbag
 SG_ ACC_ASM_Zeitstempel  : 8|8@1+ (0.080000,0.000000) [0.000000|20.320000] "Unit_Secon" Airbag
 SG_ ACC_ASM_Data_1  : 16|8@1+ (1.000000,0.000000) [0.000000|255.000000] "" Airbag
 SG_ ACC_ASM_Data_2  : 24|8@1+ (1.000000,0.000000) [0.000000|255.000000] "" Airbag
 SG_ ACC_ASM_Data_3  : 32|8@1+ (1.000000,0.000000) [0.000000|255.000000] "" Airbag
 SG_ ACC_ASM_Data_4  : 40|8@1+ (1.000000,0.000000) [0.000000|255.000000] "" Airbag
 SG_ ACC_ASM_Data_5  : 48|8@1+ (1.000000,0.000000) [0.000000|255.000000] "" Airbag
 SG_ ACC_ASM_Data_6  : 56|8@1+ (1.000000,0.000000) [0.000000|255.000000] "" Airbag

BO_ 64 Airbag_01: 8 Airbag
 SG_ Airbag_01_CRC  : 0|8@1+ (1.000000,0.000000) [0.000000|255.000000] "" ICAS1_Gateway LE1 LE2 Motor_BEV
 SG_ Airbag_01_BZ  : 8|4@1+ (1.000000,0.000000) [0.000000|15.000000] "" ICAS1_Gateway LE1 LE2 Motor_BEV
 SG_ AB_RGS_Anst  : 12|4@1+ (1.000000,0.000000) [0.000000|15.000000] "" ICAS1_Gateway ICAS1_KommunikationsServer
 SG_ AB_Front_Crash  : 16|1@1+ (1.000000,0.000000) [0.000000|1.000000] "" ICAS1_Gateway
 SG_ AB_Heck_Crash  : 17|1@1+ (1.000000,0.000000) [0.000000|1.000000] "" ICAS1_Gateway
 SG_ AB_SF_Crash  : 18|1@1+ (1.000000,0.000000) [0.000000|1.000000] "" ICAS1_Gateway
 SG_ AB_SB_Crash  : 19|1@1+ (1.000000,0.000000) [0.000000|1.000000] "" ICAS1_Gateway
 SG_ AB_Rollover_Crash  : 20|1@1+ (1.000000,0.000000) [0.000000|1.000000] "" ICAS1_Gateway
 SG_ AB_Crash_Int  : 21|3@1+ (1.000000,0.000000) [0.000000|7.000000] "" ICAS1_Gateway ICAS1_KommunikationsServer Motor_BEV
 SG_ AB_Lampe  : 24|1@1+ (1.000000,0.000000) [0.000000|1.000000] "" ICAS1_Gateway ICAS1_KommunikationsServer
 SG_ AB_Deaktiviert  : 25|1@1+ (1.000000,0.000000) [0.000000|1.000000] "" ICAS1_Gateway
 SG_ AB_VB_deaktiviert  : 26|1@1+ (1.000000,0.000000) [0.000000|1.000000] "" ICAS1_Gateway
 SG_ AB_Systemfehler  : 27|1@1+ (1.000000,0.000000) [0.000000|1.000000] "" ICAS1_Gateway ICAS1_KommunikationsServer
 SG_ AB_Diagnose  : 28|1@1+ (1.000000,0.000000) [0.000000|1.000000] "" ICAS1_Gateway
 SG_ AB_Stellgliedtest  : 29|1@1+ (1.000000,0.000000) [0.000000|1.000000] "" ICAS1_Gateway
 SG_ AB_Erh_Auf_VB  : 30|2@1+ (1.000000,0.000000) [0.000000|3.000000] "" ICAS1_Gateway
 SG_ AB_Gurtwarn_VF  : 32|1@1+ (1.000000,0.000000) [0.000000|1.000000] "" ICAS1_Gateway ICAS1_KommunikationsServer
 SG_ AB_Gurtwarn_VB  : 33|1@1+ (1.000000,0.000000) [0.000000|1.000000] "" ICAS1_Gateway ICAS1_KommunikationsServer
 SG_ AB_Anzeige_Fussg  : 34|2@1+ (1.000000,0.000000) [0.000000|3.000000] "" ICAS1_Gateway
 SG_ AB_Texte_AKS  : 36|2@1+ (1.000000,0.000000) [0.000000|3.000000] "" ICAS1_Gateway
 SG_ AB_PAO_Leuchte_Anf  : 38|1@1+ (1.000000,0.000000) [0.000000|1.000000] "" ICAS1_Gateway
 SG_ AB_MKB_gueltig  : 39|1@1+ (1.000000,0.000000) [0.000000|1.000000] "" ICAS1_Gateway
 SG_ AB_MKB_Anforderung  : 40|1@1+ (1.000000,0.000000) [0.000000|1.000000] "" ICAS1_Gateway
 SG_ AB_Versorgungsspannung  : 41|1@1+ (1.000000,0.000000) [0.000000|1.000000] "" ICAS1_Gateway
 SG_ AB_Deaktivierung_HV  : 42|3@1+ (1.000000,0.000000) [0.000000|7.000000] "" ICAS1_Gateway ICAS1_KommunikationsServer LE1 LE2 Motor_BEV
 SG_ AB_EDR_Trigger  : 45|2@1+ (1.000000,0.000000) [0.000000|3.000000] "" ICAS1_Gateway
 SG_ AB_Belegung_VF  : 47|2@1+ (1.000000,0.000000) [0.000000|3.000000] "" ICAS1_Gateway
 SG_ AB_Gurtschloss_FA_ext  : 49|3@1+ (1.000000,0.000000) [0.000000|7.000000] "" ICAS1_Gateway
 SG_ AB_Belegung_VF_ext  : 52|3@1+ (1.000000,0.000000) [0.000000|7.000000] "" ICAS1_Gateway
 SG_ ASM_Masterzeit  : 56|8@1+ (0.080000,0.000000) [0.000000|20.320000] "Unit_Secon" ICAS1_Gateway

BO_ 1312 Airbag_02: 8 Airbag
 SG_ Airbag_02_CRC  : 0|8@1+ (1.000000,0.000000) [0.000000|255.000000] "" ICAS1_Gateway Motor_BEV
 SG_ Airbag_02_BZ  : 8|4@1+ (1.000000,0.000000) [0.000000|15.000000] "" ICAS1_Gateway Motor_BEV
 SG_ LoGeWa_Event_Kombiwarnung  : 12|4@1+ (1.000000,0.000000) [0.000000|15.000000] "" ICAS1_Gateway
 SG_ AB_Anforderung_eCall  : 16|1@1+ (1.000000,0.000000) [0.000000|1.000000] "" ICAS1_Gateway
 SG_ AB_Anprall_Seite_Beifahrer  : 17|1@1+ (1.000000,0.000000) [0.000000|1.000000] "" ICAS1_Gateway ICAS1_KommunikationsServer
 SG_ AB_Anprall_Rollover  : 18|1@1+ (1.000000,0.000000) [0.000000|1.000000] "" ICAS1_Gateway ICAS1_KommunikationsServer
 SG_ AB_Anprall_FGS  : 19|1@1+ (1.000000,0.000000) [0.000000|1.000000] "" ICAS1_Gateway ICAS1_KommunikationsServer
 SG_ AB_Anprall_Front_Beifahrer  : 20|1@1+ (1.000000,0.000000) [0.000000|1.000000] "" ICAS1_Gateway ICAS1_KommunikationsServer
 SG_ AB_Anprall_Front_Fahrer  : 21|1@1+ (1.000000,0.000000) [0.000000|1.000000] "" ICAS1_Gateway ICAS1_KommunikationsServer
 SG_ AB_Anprall_Heck_Beifahrer  : 22|1@1+ (1.000000,0.000000) [0.000000|1.000000] "" ICAS1_Gateway ICAS1_KommunikationsServer
 SG_ AB_Anprall_Heck_Fahrer  : 23|1@1+ (1.000000,0.000000) [0.000000|1.000000] "" ICAS1_Gateway ICAS1_KommunikationsServer
 SG_ AB_Wickelklappung_Reihe2_MI  : 24|2@1+ (1.000000,0.000000) [0.000000|3.000000] "" ICAS1_Gateway
 SG_ AB_Belegung_VB  : 26|2@1+ (1.000000,0.000000) [0.000000|3.000000] "" ICAS1_Gateway
 SG_ AB_Abschaltanf_SIH_BF  : 28|1@1+ (1.000000,0.000000) [0.000000|1.000000] "" ICAS1_Gateway
 SG_ AB_Anprall_Seite_Fahrer  : 29|1@1+ (1.000000,0.000000) [0.000000|1.000000] "" ICAS1_Gateway ICAS1_KommunikationsServer
 SG_ SC_PAO_Schriftzug_Anf  : 30|2@1+ (1.000000,0.000000) [0.000000|3.000000] "" ICAS1_Gateway
 SG_ SC_PAO_ON_Anf  : 32|2@1+ (1.000000,0.000000) [0.000000|3.000000] "" ICAS1_Gateway
 SG_ SC_PAO_OFF_Anf  : 34|2@1+ (1.000000,0.000000) [0.000000|3.000000] "" ICAS1_Gateway
 SG_ AB_Crashschwere  : 36|3@1+ (1.000000,0.000000) [0.000000|7.000000] "" ICAS1_Gateway ICAS1_KommunikationsServer
 SG_ AB_Anforderung_USM  : 39|1@1+ (1.000000,0.000000) [0.000000|1.000000] "" ICAS1_Gateway
 SG_ AB_Gurtschloss_FA  : 40|2@1+ (1.000000,0.000000) [0.000000|3.000000] "" ICAS1_Gateway ICAS1_KommunikationsServer Motor_BEV
 SG_ AB_Gurtschloss_BF  : 42|2@1+ (1.000000,0.000000) [0.000000|3.000000] "" ICAS1_Gateway ICAS1_KommunikationsServer
 SG_ AB_Gurtschloss_Reihe2_FA  : 44|2@1+ (1.000000,0.000000) [0.000000|3.000000] "" ICAS1_Gateway ICAS1_KommunikationsServer
 SG_ AB_Gurtschloss_Reihe2_MI  : 46|2@1+ (1.000000,0.000000) [0.000000|3.000000] "" ICAS1_Gateway ICAS1_KommunikationsServer
 SG_ AB_Gurtschloss_Reihe2_BF  : 48|2@1+ (1.000000,0.000000) [0.000000|3.000000] "" ICAS1_Gateway ICAS1_KommunikationsServer
 SG_ AB_Gurtschloss_Reihe3_FA  : 50|2@1+ (1.000000,0.000000) [0.000000|3.000000] "" ICAS1_Gateway ICAS1_KommunikationsServer
 SG_ AB_Gurtschloss_Reihe3_MI  : 52|2@1+ (1.000000,0.000000) [0.000000|3.000000] "" ICAS1_Gateway ICAS1_KommunikationsServer
 SG_ AB_Gurtschloss_Reihe3_BF  : 54|2@1+ (1.000000,0.000000) [0.000000|3.000000] "" ICAS1_Gateway ICAS1_KommunikationsServer
 SG_ AB_Sitzpos_Sens_FA  : 56|2@1+ (1.000000,0.000000) [0.000000|3.000000] "" ICAS1_Gateway
 SG_ AB_Sitzpos_Sens_BF  : 58|2@1+ (1.000000,0.000000) [0.000000|3.000000] "" ICAS1_Gateway
 SG_ AB_Wickelklappung_Reihe2_BF  : 60|2@1+ (1.000000,0.000000) [0.000000|3.000000] "" ICAS1_Gateway
 SG_ AB_Wickelklappung_Reihe2_FA  : 62|2@1+ (1.000000,0.000000) [0.000000|3.000000] "" ICAS1_Gateway

BO_ 65 Airbag_03: 8 Airbag
 SG_ Airbag_03_CRC  : 0|8@1+ (1.000000,0.000000) [0.000000|255.000000] "" ICAS1_Gateway
 SG_ Airbag_03_BZ  : 8|4@1+ (1.000000,0.000000) [0.000000|15.000000] "" ICAS1_Gateway
 SG_ AB_MKB_Safing  : 63|1@1+ (1.000000,0.000000) [0.000000|1.000000] "" ICAS1_Gateway

BO_ 1349 Airbag_04: 8 Airbag
 SG_ AB_Gurtwarn_Reihe4_FA  : 14|2@1+ (1.000000,0.000000) [0.000000|3.000000] "" ICAS1_Gateway ICAS1_KommunikationsServer
 SG_ AB_Gurtwarn_Reihe4_BF  : 16|2@1+ (1.000000,0.000000) [0.000000|3.000000] "" ICAS1_Gateway ICAS1_KommunikationsServer
 SG_ AB_Gurtwarn_Reihe4_MI  : 18|2@1+ (1.000000,0.000000) [0.000000|3.000000] "" ICAS1_Gateway ICAS1_KommunikationsServer
 SG_ AB_Gurtwarn_Reihe2_FA  : 20|2@1+ (1.000000,0.000000) [0.000000|3.000000] "" ICAS1_Gateway ICAS1_KommunikationsServer
 SG_ AB_Gurtwarn_Reihe2_BF  : 22|2@1+ (1.000000,0.000000) [0.000000|3.000000] "" ICAS1_Gateway ICAS1_KommunikationsServer
 SG_ AbstWarn_MV_FAS_Fkt_Status  : 24|2@1+ (1.000000,0.000000) [0.000000|3.000000] "" ICAS1_Gateway
 SG_ WarnBrems_Charisma_Status  : 26|2@1+ (1.000000,0.000000) [0.000000|3.000000] "" ICAS1_Gateway
 SG_ WarnBrems_Charisma_FahrPr  : 28|4@1+ (1.000000,0.000000) [0.000000|15.000000] "" ICAS1_Gateway
 SG_ AB_Gurtwarn_Reihe2_MI  : 32|2@1+ (1.000000,0.000000) [0.000000|3.000000] "" ICAS1_Gateway ICAS1_KommunikationsServer
 SG_ AB_Gurtwarn_Reihe3_FA  : 34|2@1+ (1.000000,0.000000) [0.000000|3.000000] "" ICAS1_Gateway ICAS1_KommunikationsServer
 SG_ AB_Gurtwarn_Reihe3_MI  : 36|2@1+ (1.000000,0.000000) [0.000000|3.000000] "" ICAS1_Gateway ICAS1_KommunikationsServer
 SG_ AB_Gurtwarn_Reihe3_BF  : 38|2@1+ (1.000000,0.000000) [0.000000|3.000000] "" ICAS1_Gateway ICAS1_KommunikationsServer
 SG_ LGI_FAS_Fkt_Status  : 40|2@1+ (1.000000,0.000000) [0.000000|3.000000] "" ICAS1_Gateway
 SG_ PreCrash_FAS_Fkt_Status  : 42|3@1+ (1.000000,0.000000) [0.000000|7.000000] "" ICAS1_Gateway
 SG_ AB_SBR_hinten_verbau  : 48|2@1+ (1.000000,0.000000) [0.000000|3.000000] "" ICAS1_Gateway ICAS1_KommunikationsServer
 SG_ AWV_Einstellung_System_ASG  : 51|1@1+ (1.000000,0.000000) [0.000000|1.000000] "" ICAS1_Gateway
 SG_ AWV_Einstellung_Warnung_ASG  : 52|3@1+ (1.000000,0.000000) [0.000000|7.000000] "" ICAS1_Gateway
 SG_ SC_PreSense_Modus_Warnung_NV  : 55|3@1+ (1.000000,0.000000) [0.000000|7.000000] "" ICAS1_Gateway
 SG_ SC_PreSense_Modus_Warnung_MV  : 58|3@1+ (1.000000,0.000000) [0.000000|7.000000] "" ICAS1_Gateway
 SG_ SC_PreSense_Modus_System_MV  : 61|1@1+ (1.000000,0.000000) [0.000000|1.000000] "" ICAS1_Gateway
 SG_ SC_PreSense_Modus_System_NV  : 62|1@1+ (1.000000,0.000000) [0.000000|1.000000] "" ICAS1_Gateway
 SG_ SC_PreSense_Modus_System_KAS  : 63|1@1+ (1.000000,0.000000) [0.000000|1.000000] "" ICAS1_Gateway

BO_ 2527679722 Airbag_06: 8 Airbag
 SG_ AB_Gurtschloss_Reihe4_FA  : 12|2@1+ (1.000000,0.000000) [0.000000|3.000000] "" ICAS1_Gateway ICAS1_KommunikationsServer
 SG_ AB_Gurtschloss_Reihe4_BF  : 14|2@1+ (1.000000,0.000000) [0.000000|3.000000] "" ICAS1_Gateway ICAS1_KommunikationsServer
 SG_ AB_Gurtschloss_Reihe4_MI  : 16|2@1+ (1.000000,0.000000) [0.000000|3.000000] "" ICAS1_Gateway ICAS1_KommunikationsServer

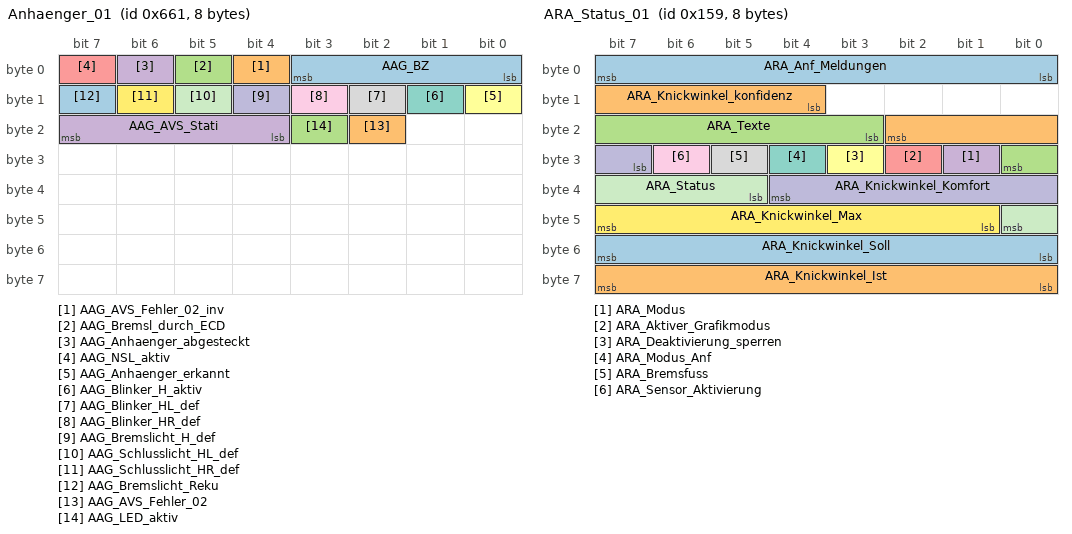
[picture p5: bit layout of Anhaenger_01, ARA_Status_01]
BO_ 1633 Anhaenger_01: 8 ICAS1_Gateway
 SG_ AAG_BZ  : 0|4@1+ (1.000000,0.000000) [0.000000|15.000000] "" Vector__XXX
 SG_ AAG_AVS_Fehler_02_inv  : 4|1@1+ (1.000000,0.000000) [0.000000|1.000000] "" Vector__XXX
 SG_ AAG_Bremsl_durch_ECD  : 5|1@1+ (1.000000,0.000000) [0.000000|1.000000] "" Motor_BEV
 SG_ AAG_Anhaenger_abgesteckt  : 6|1@1+ (1.000000,0.000000) [0.000000|1.000000] "" Motor_BEV
 SG_ AAG_NSL_aktiv  : 7|1@1+ (1.000000,0.000000) [0.000000|1.000000] "" Vector__XXX
 SG_ AAG_Anhaenger_erkannt  : 8|1@1+ (1.000000,0.000000) [0.000000|1.000000] "" Motor_BEV
 SG_ AAG_Blinker_H_aktiv  : 9|1@1+ (1.000000,0.000000) [0.000000|1.000000] "" Vector__XXX
 SG_ AAG_Blinker_HL_def  : 10|1@1+ (1.000000,0.000000) [0.000000|1.000000] "" Vector__XXX
 SG_ AAG_Blinker_HR_def  : 11|1@1+ (1.000000,0.000000) [0.000000|1.000000] "" Vector__XXX
 SG_ AAG_Bremslicht_H_def  : 12|1@1+ (1.000000,0.000000) [0.000000|1.000000] "" Motor_BEV
 SG_ AAG_Schlusslicht_HL_def  : 13|1@1+ (1.000000,0.000000) [0.000000|1.000000] "" Vector__XXX
 SG_ AAG_Schlusslicht_HR_def  : 14|1@1+ (1.000000,0.000000) [0.000000|1.000000] "" Vector__XXX
 SG_ AAG_Bremslicht_Reku  : 15|1@1+ (1.000000,0.000000) [0.000000|1.000000] "" Vector__XXX
 SG_ AAG_AVS_Fehler_02  : 18|1@1+ (1.000000,0.000000) [0.000000|1.000000] "" Vector__XXX
 SG_ AAG_LED_aktiv  : 19|1@1+ (1.000000,0.000000) [0.000000|1.000000] "" Vector__XXX
 SG_ AAG_AVS_Stati  : 20|4@1+ (1.000000,0.000000) [0.000000|15.000000] "" Vector__XXX

BO_ 345 ARA_Status_01: 8 ICAS1_Gateway
 SG_ ARA_Anf_Meldungen  : 0|8@1+ (1.000000,0.000000) [0.000000|255.000000] "" Vector__XXX
 SG_ ARA_Knickwinkel_konfidenz  : 12|7@1+ (1.000000,0.000000) [0.000000|120.000000] "Unit_DegreOfArc" Vector__XXX
 SG_ ARA_Texte  : 19|6@1+ (1.000000,0.000000) [0.000000|63.000000] "" Vector__XXX
 SG_ ARA_Modus  : 25|1@1+ (1.000000,0.000000) [0.000000|1.000000] "" Vector__XXX
 SG_ ARA_Aktiver_Grafikmodus  : 26|1@1+ (1.000000,0.000000) [0.000000|1.000000] "" Vector__XXX
 SG_ ARA_Deaktivierung_sperren  : 27|1@1+ (1.000000,0.000000) [0.000000|1.000000] "" Vector__XXX
 SG_ ARA_Modus_Anf  : 28|1@1+ (1.000000,0.000000) [0.000000|1.000000] "" Vector__XXX
 SG_ ARA_Bremsfuss  : 29|1@1+ (1.000000,0.000000) [0.000000|1.000000] "" Vector__XXX
 SG_ ARA_Sensor_Aktivierung  : 30|1@1+ (1.000000,0.000000) [0.000000|1.000000] "" Vector__XXX
 SG_ ARA_Knickwinkel_Komfort  : 31|6@1+ (1.000000,0.000000) [0.000000|60.000000] "Unit_DegreOfArc" Vector__XXX
 SG_ ARA_Status  : 37|4@1+ (1.000000,0.000000) [0.000000|15.000000] "" Motor_BEV
 SG_ ARA_Knickwinkel_Max  : 41|7@1+ (1.000000,0.000000) [0.000000|120.000000] "Unit_DegreOfArc" Vector__XXX
 SG_ ARA_Knickwinkel_Soll  : 48|8@1+ (1.000000,-125.000000) [-125.000000|126.000000] "Unit_DegreOfArc" Vector__XXX
 SG_ ARA_Knickwinkel_Ist  : 56|8@1+ (1.000000,-125.000000) [-125.000000|126.000000] "Unit_DegreOfArc" Vector__XXX

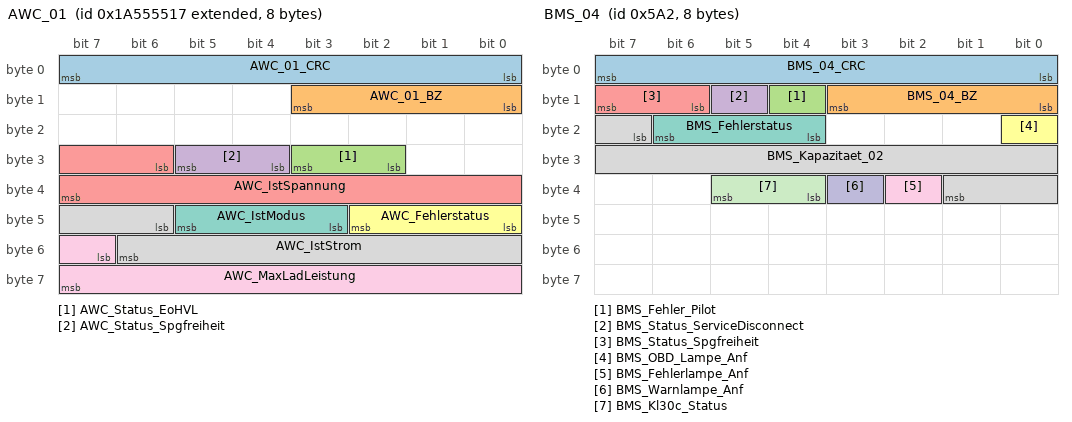
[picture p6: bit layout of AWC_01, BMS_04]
BO_ 2589283607 AWC_01: 8 ICAS1_Gateway
 SG_ AWC_01_CRC  : 0|8@1+ (1.000000,0.000000) [0.000000|255.000000] "" Vector__XXX
 SG_ AWC_01_BZ  : 8|4@1+ (1.000000,0.000000) [0.000000|15.000000] "" Vector__XXX
 SG_ AWC_Status_EoHVL  : 26|2@1+ (1.000000,0.000000) [0.000000|3.000000] "" Motor_BEV
 SG_ AWC_Status_Spgfreiheit  : 28|2@1+ (1.000000,0.000000) [0.000000|3.000000] "" Vector__XXX
 SG_ AWC_IstSpannung  : 30|10@1+ (1.000000,0.000000) [0.000000|1021.000000] "Unit_Volt" Vector__XXX
 SG_ AWC_Fehlerstatus  : 40|3@1+ (1.000000,0.000000) [0.000000|7.000000] "" Vector__XXX
 SG_ AWC_IstModus  : 43|3@1+ (1.000000,0.000000) [0.000000|7.000000] "" Vector__XXX
 SG_ AWC_IstStrom  : 46|9@1+ (0.100000,0.000000) [0.000000|50.900000] "Unit_Amper" Vector__XXX
 SG_ AWC_MaxLadLeistung  : 55|9@1+ (25.000000,0.000000) [0.000000|12725.000000] "Unit_Watt" Vector__XXX

BO_ 219 AWV_03: 48 ICAS1_Gateway
 SG_ AWV_03_CRC  : 0|8@1+ (1.000000,0.000000) [0.000000|255.000000] "" Airbag
 SG_ AWV_03_BZ  : 8|4@1+ (1.000000,0.000000) [0.000000|15.000000] "" Airbag
 SG_ PCF_Freigabe  : 12|1@1+ (1.000000,0.000000) [0.000000|1.000000] "" Airbag
 SG_ SDF_PSF_Objektstatus  : 13|3@1+ (1.000000,0.000000) [0.000000|7.000000] "" Airbag
 SG_ SDF_PSF_CU_Status  : 16|1@1+ (1.000000,0.000000) [0.000000|1.000000] "" Airbag
 SG_ SDF_PSF_CW  : 17|7@1+ (1.000000,0.000000) [0.000000|100.000000] "" Airbag
 SG_ SDF_PSF_Fahrer_aktiv  : 24|1@1+ (1.000000,0.000000) [0.000000|1.000000] "" Airbag
 SG_ SDF_PSF_Guete  : 25|2@1+ (1.000000,0.000000) [0.000000|3.000000] "" Airbag
 SG_ SDF_PSF_Kollisionsueberdeckung  : 27|5@1+ (0.100000,0.000000) [0.100000|2.800000] "Unit_Meter" Airbag
 SG_ SDF_PSF_Time_To_Collision  : 32|8@1+ (0.010000,0.000000) [0.000000|2.500000] "Unit_Secon" Vector__XXX
 SG_ SDF_PSF_v_rel  : 40|8@1+ (0.400000,0.000000) [0.400000|101.200000] "Unit_MeterPerSecon" Airbag
 SG_ AWV_Eingriff_Sendeart  : 64|1@1+ (1.000000,0.000000) [0.000000|1.000000] "" Airbag
 SG_ AWV_Verz_Freigabe  : 65|1@1+ (1.000000,0.000000) [0.000000|1.000000] "" Airbag
 SG_ AWV_Verz_Anf  : 66|10@1+ (0.024000,-20.016000) [-20.016000|4.512000] "Unit_MeterPerSeconSquar" Airbag
 SG_ AWV_Anf_Prefill  : 76|1@1+ (1.000000,0.000000) [0.000000|1.000000] "" Airbag
 SG_ AWV_Ruckprofil  : 77|3@1+ (1.000000,0.000000) [0.000000|7.000000] "" Vector__XXX
 SG_ AWV_Time_to_collision  : 80|8@1+ (0.010000,0.000000) [0.000000|2.500000] "Unit_Secon" Airbag
 SG_ AWV_HBA_Param  : 88|2@1+ (1.000000,0.000000) [0.000000|3.000000] "" Vector__XXX
 SG_ AWV_Verz_Anf_ASIL  : 90|3@1+ (1.000000,0.000000) [0.000000|7.000000] "" Vector__XXX
 SG_ AWV_Time_to_brake  : 93|7@1+ (10.000000,0.000000) [0.000000|1240.000000] "Unit_MilliSecon" Vector__XXX
 SG_ AWV_Zielobjekttyp  : 100|4@1+ (1.000000,0.000000) [0.000000|15.000000] "" Airbag
 SG_ AWV_QFK_KruemmSoll  : 104|15@1+ (0.000007,0.000000) [0.000000|0.219539] "Unit_MeterInver" Vector__XXX
 SG_ AWV_QFK_KruemmSoll_VZ  : 119|1@1+ (1.000000,0.000000) [0.000000|1.000000] "" Vector__XXX
 SG_ AWV_QFK_Spuerb  : 120|8@1+ (0.400000,0.000000) [0.000000|100.000000] "Unit_PerCent" Vector__XXX
 SG_ AWV_QFK_AnfStat  : 128|4@1+ (1.000000,0.000000) [0.000000|15.000000] "" Airbag
 SG_ AWV_QFK_Signal1  : 132|10@1+ (1.000000,0.000000) [0.000000|1023.000000] "" Vector__XXX
 SG_ AWV_QFK_Art1  : 142|3@1+ (1.000000,0.000000) [0.000000|7.000000] "" Vector__XXX
 SG_ AWV_QFK_Art2  : 145|3@1+ (1.000000,0.000000) [0.000000|7.000000] "" Vector__XXX
 SG_ AWV_QFK_Signal2  : 148|10@1+ (1.000000,0.000000) [0.000000|1023.000000] "" Vector__XXX

BO_ 2536767264 BAP_Debug_Cmd: 8 BAP_Tester
 SG_ BAP_Debug_Cmd  : 0|16@1+ (1.000000,0.000000) [0.000000|65535.000000] "" Motor_BEV

BO_ 2536767280 BAP_Debug_Data: 8 Motor_BEV
 SG_ BAP_Debug_Data  : 0|64@1+ (1.000000,0.000000) [0.000000|18446744073709551616.000000] "" BAP_Tester

BO_ 2536717313 BAP_EfficiencyAssist_ASG_02: 8 ICAS1_Gateway
 SG_ BAP_EfficAssist_ASG_02_Header  : 0|64@1+ (1.000000,0.000000) [0.000000|18446744073709551616.000000] "" Motor_BEV

BO_ 2536717314 BAP_EfficiencyAssist_ASG_03: 8 ICAS1_Gateway
 SG_ BAP_EfficAssist_ASG_03_Header  : 0|8@1+ (1.000000,0.000000) [0.000000|255.000000] "" Motor_BEV

BO_ 2536717328 BAP_EfficiencyAssist_FSG_01: 8 Motor_BEV
 SG_ BAP_EfficAssist_FSG_01_Header  : 0|8@1+ (1.000000,0.000000) [0.000000|255.000000] "" ICAS1_Gateway

BO_ 2536709120 BAP_Hybrid_ASG_01: 8 ICAS1_Gateway
 SG_ BAP_Hybrid_ASG_01_Header  : 0|8@1+ (1.000000,0.000000) [0.000000|255.000000] "" Motor_BEV

BO_ 2536709136 BAP_Hybrid_FSG_01: 8 Motor_BEV
 SG_ BAP_Hybrid_FSG_01_Header  : 0|8@1+ (1.000000,0.000000) [0.000000|255.000000] "" ICAS1_Gateway

BO_ 869 BEM_05: 8 ICAS1_Gateway
 SG_ BEM_UBDM  : 0|8@1+ (0.050000,5.000000) [5.050000|17.700000] "Unit_Volt" Vector__XXX
 SG_ NVEM_Ladefreigabe  : 8|2@1+ (1.000000,0.000000) [0.000000|3.000000] "" Vector__XXX
 SG_ NVEM_FMAus_Info  : 10|2@1+ (1.000000,0.000000) [0.000000|3.000000] "" Vector__XXX
 SG_ NVEM_PTC_Sollstufe  : 12|2@1+ (1.000000,0.000000) [0.000000|3.000000] "" Vector__XXX
 SG_ NVEM_P_Generator_Status  : 15|1@1+ (1.000000,0.000000) [0.000000|1.000000] "" Vector__XXX
 SG_ BEM_P_Generator  : 16|8@1+ (50.000000,0.000000) [0.000000|12700.000000] "Unit_Watt" Vector__XXX
 SG_ BEM_n_LLA  : 24|2@1+ (1.000000,0.000000) [0.000000|3.000000] "" Vector__XXX
 SG_ BEM_01_Abschaltstufen  : 26|3@1+ (1.000000,0.000000) [0.000000|7.000000] "" Vector__XXX
 SG_ BEM_Anf_KL  : 29|1@1+ (1.000000,0.000000) [0.000000|1.000000] "" Vector__XXX
 SG_ BEM_StartStopp_Info  : 30|2@1+ (1.000000,0.000000) [0.000000|3.000000] "" Vector__XXX
 SG_ BEM_DFM  : 32|5@1+ (3.225000,0.025000) [0.025000|100.000000] "" Vector__XXX
 SG_ BEM_EMLIN_ungueltig  : 37|1@1+ (1.000000,0.000000) [0.000000|1.000000] "" Vector__XXX
 SG_ BEM_Batt_Ab  : 38|1@1+ (1.000000,0.000000) [0.000000|1.000000] "" Motor_BEV
 SG_ NVEM_FMAus_I_Verbrauch  : 39|5@1+ (5.000000,0.000000) [0.000000|145.000000] "Unit_Amper" Vector__XXX
 SG_ NVEM_Freilauf_Info  : 44|2@1+ (1.000000,0.000000) [0.000000|3.000000] "" Vector__XXX
 SG_ BEM_NV_NachladAnf  : 46|2@1+ (1.000000,0.000000) [0.000000|3.000000] "" Vector__XXX
 SG_ BEM_Segel_Info  : 48|2@1+ (1.000000,0.000000) [0.000000|3.000000] "" Vector__XXX
 SG_ BEM_HYB_DC_uSollLV  : 50|6@1+ (0.100000,10.600000) [10.600000|16.000000] "Unit_Volt" Vector__XXX
 SG_ BEM_HYB_DC_uMinLV  : 56|8@1+ (0.100000,0.000000) [0.000000|25.300000] "Unit_Volt" Vector__XXX

BO_ 1442 BMS_04: 8 ICAS1_Gateway
 SG_ BMS_04_CRC  : 0|8@1+ (1.000000,0.000000) [0.000000|255.000000] "" Vector__XXX
 SG_ BMS_04_BZ  : 8|4@1+ (1.000000,0.000000) [0.000000|15.000000] "" Vector__XXX
 SG_ BMS_Fehler_Pilot  : 12|1@1+ (1.000000,0.000000) [0.000000|1.000000] "" Vector__XXX
 SG_ BMS_Status_ServiceDisconnect  : 13|1@1+ (1.000000,0.000000) [0.000000|1.000000] "" Vector__XXX
 SG_ BMS_Status_Spgfreiheit  : 14|2@1+ (1.000000,0.000000) [0.000000|3.000000] "" Motor_BEV
 SG_ BMS_OBD_Lampe_Anf  : 16|1@1+ (1.000000,0.000000) [0.000000|1.000000] "" Motor_BEV
 SG_ BMS_Fehlerstatus  : 20|3@1+ (1.000000,0.000000) [0.000000|7.000000] "" Vector__XXX
 SG_ BMS_Kapazitaet_02  : 23|11@1+ (0.200000,0.000000) [0.000000|409.200000] "Unit_AmperHour" Vector__XXX
 SG_ BMS_Fehlerlampe_Anf  : 34|1@1+ (1.000000,0.000000) [0.000000|1.000000] "" Motor_BEV
 SG_ BMS_Warnlampe_Anf  : 35|1@1+ (1.000000,0.000000) [0.000000|1.000000] "" Motor_BEV
 SG_ BMS_Kl30c_Status  : 36|2@1+ (1.000000,0.000000) [0.000000|3.000000] "" Motor_BEV

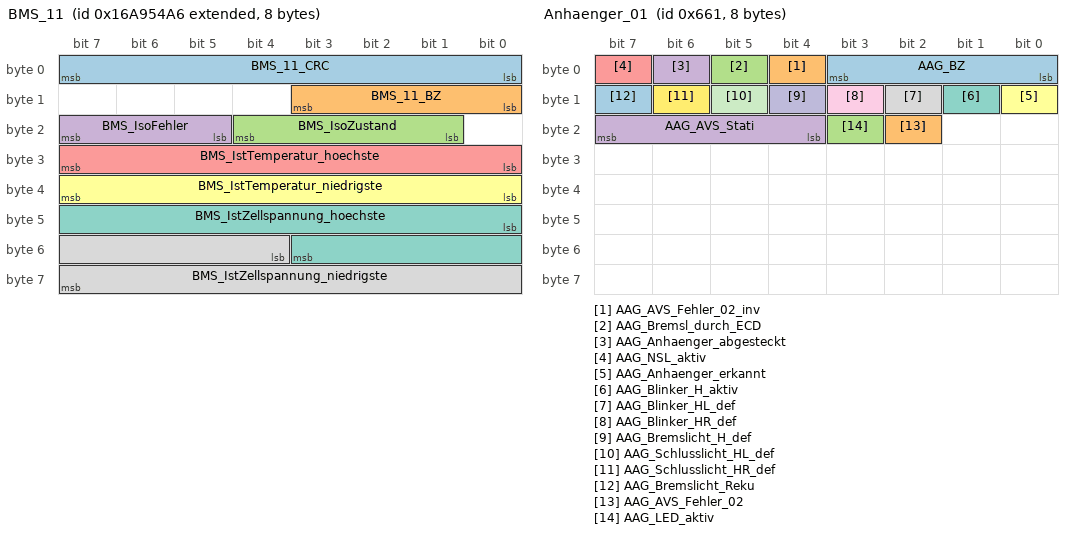
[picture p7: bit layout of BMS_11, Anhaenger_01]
BO_ 2527679654 BMS_11: 8 ICAS1_Gateway
 SG_ BMS_11_CRC  : 0|8@1+ (1.000000,0.000000) [0.000000|255.000000] "" Motor_BEV
 SG_ BMS_11_BZ  : 8|4@1+ (1.000000,0.000000) [0.000000|15.000000] "" Motor_BEV
 SG_ BMS_IsoZustand  : 17|4@1+ (1.000000,0.000000) [0.000000|15.000000] "" Motor_BEV
 SG_ BMS_IsoFehler  : 21|3@1+ (1.000000,0.000000) [0.000000|7.000000] "" Motor_BEV
 SG_ BMS_IstTemperatur_hoechste  : 24|8@1+ (0.500000,-40.000000) [-40.000000|86.000000] "Unit_DegreCelsi" Vector__XXX
 SG_ BMS_IstTemperatur_niedrigste  : 32|8@1+ (0.500000,-40.000000) [-40.000000|86.000000] "Unit_DegreCelsi" Vector__XXX
 SG_ BMS_IstZellspannung_hoechste  : 40|12@1+ (1.000000,1000.000000) [1000.000000|5091.000000] "Unit_MilliVolt" Vector__XXX
 SG_ BMS_IstZellspannung_niedrigste  : 52|12@1+ (1.000000,1000.000000) [1000.000000|5091.000000] "Unit_MilliVolt" Vector__XXX

BU_:  Airbag BAP_Tester ICAS1_Gateway ICAS1_KommunikationsServer LE1 LE2 Motor_BEV Schaltbetaetigung

BO_ 333 ACC_18: 32 ICAS1_Gateway
 SG_ ACC_18_CRC  : 0|8@1+ (1.000000,0.000000) [0.000000|255.000000] "" Motor_BEV
 SG_ ACC_18_BZ  : 8|4@1+ (1.000000,0.000000) [0.000000|15.000000] "" Motor_BEV
 SG_ ACC_limitierte_Anfahrdyn  : 12|1@0- (1.000000,0.000000) [0.000000|1.000000] "" Motor_BEV
 SG_ ACC_nachtr_Stopp_Anf  : 13|1@1+ (1.000000,0.000000) [0.000000|1.000000] "" Vector__XXX
 SG_ ACC_DynErhoehung  : 14|1@1+ (1.000000,0.000000) [0.000000|1.000000] "" Motor_BEV
 SG_ ACC_Freilaufstrategie_TSK  : 15|1@1+ (1.000000,0.000000) [0.000000|1.000000] "" Motor_BEV
 SG_ ACC_zul_Regelabw_unten  : 16|6@1+ (0.024000,0.000000) [0.000000|1.512000] "Unit_MeterPerSeconSquar" Motor_BEV
 SG_ ACC_StartStopp_Info  : 22|2@1+ (1.000000,0.000000) [0.000000|3.000000] "" Vector__XXX
 SG_ ACC_Sollbeschleunigung_02  : 24|11@1+ (0.005000,-7.220000) [-7.220000|3.005000] "Unit_MeterPerSeconSquar" Motor_BEV
 SG_ ACC_zul_Regelabw_oben  : 35|5@1+ (0.062500,0.000000) [0.000000|1.937500] "Unit_MeterPerSeconSquar" Motor_BEV
 SG_ ACC_neg_Sollbeschl_Grad_02  : 40|8@1+ (0.050000,0.000000) [0.000000|12.750000] "Unit_MeterPerCubicSecon" Motor_BEV
 SG_ ACC_pos_Sollbeschl_Grad_02  : 48|8@1+ (0.050000,0.000000) [0.000000|12.750000] "Unit_MeterPerCubicSecon" Motor_BEV
 SG_ ACC_Anfahren  : 56|1@1+ (1.000000,0.000000) [0.000000|1.000000] "" Motor_BEV
 SG_ ACC_Anhalten  : 57|1@1+ (1.000000,0.000000) [0.000000|1.000000] "" Motor_BEV
 SG_ ACC_Typ  : 58|2@1+ (1.000000,0.000000) [0.000000|3.000000] "" Motor_BEV
 SG_ ACC_Status_ACC  : 60|3@1+ (1.000000,0.000000) [0.000000|7.000000] "" Motor_BEV
 SG_ ACC_Minimale_Bremsung  : 63|1@1+ (1.000000,0.000000) [0.000000|1.000000] "" Motor_BEV
 SG_ ACC_Anhalteweg  : 64|11@1+ (0.010000,0.000000) [0.000000|20.450000] "Unit_Meter" Vector__XXX
 SG_ ACC_Boost  : 75|1@1+ (1.000000,0.000000) [0.000000|1.000000] "" Vector__XXX
 SG_ ACC_Freilauf_Anf  : 76|1@1+ (1.000000,0.000000) [0.000000|1.000000] "" Vector__XXX
 SG_ ACC_Anforderung_HMS  : 77|3@1+ (1.000000,0.000000) [0.000000|7.000000] "" Vector__XXX
 SG_ ACC_Folgebeschl  : 80|8@1+ (0.030000,-4.600000) [-4.600000|2.990000] "Unit_MeterPerSeconSquar" Motor_BEV
 SG_ ACC_Freilauf_Info  : 88|2@1+ (1.000000,0.000000) [0.000000|3.000000] "" Motor_BEV
 SG_ ACC_Tempolimitassistent_Ein  : 90|1@1+ (1.000000,0.000000) [0.000000|1.000000] "" Vector__XXX
 SG_ ACC_FoD_Status  : 91|2@1+ (1.000000,0.000000) [0.000000|3.000000] "" Motor_BEV
 SG_ vESC_Verz_Anf  : 232|4@1+ (0.500000,0.000000) [0.000000|3.500000] "Unit_MeterPerSeconSquar" Vector__XXX
 SG_ RDR_v_ueber_Grund  : 236|12@1+ (0.100000,0.000000) [0.000000|409.000000] "Unit_KiloMeterPerHour" Vector__XXX
 SG_ RDR_v_ueber_Grund_Genauigkeit  : 248|6@1+ (0.100000,0.000000) [0.000000|6.000000] "Unit_KiloMeterPerHour" Vector__XXX
 SG_ RDR_v_ueber_Grund_Fahrtrichtung  : 254|2@1+ (1.000000,0.000000) [0.000000|3.000000] "" Vector__XXX

BO_ 2527679682 ACC_ASM_01: 8 ICAS1_Gateway
 SG_ ACC_ASM_Ereignis  : 0|8@1+ (1.000000,0.000000) [1.000000|254.000000] "" Airbag
 SG_ ACC_ASM_Zeitstempel  : 8|8@1+ (0.080000,0.000000) [0.000000|20.320000] "Unit_Secon" Airbag
 SG_ ACC_ASM_Data_1  : 16|8@1+ (1.000000,0.000000) [0.000000|255.000000] "" Airbag
 SG_ ACC_ASM_Data_2  : 24|8@1+ (1.000000,0.000000) [0.000000|255.000000] "" Airbag
 SG_ ACC_ASM_Data_3  : 32|8@1+ (1.000000,0.000000) [0.000000|255.000000] "" Airbag
 SG_ ACC_ASM_Data_4  : 40|8@1+ (1.000000,0.000000) [0.000000|255.000000] "" Airbag
 SG_ ACC_ASM_Data_5  : 48|8@1+ (1.000000,0.000000) [0.000000|255.000000] "" Airbag
 SG_ ACC_ASM_Data_6  : 56|8@1+ (1.000000,0.000000) [0.000000|255.000000] "" Airbag

BO_ 64 Airbag_01: 8 Airbag
 SG_ Airbag_01_CRC  : 0|8@1+ (1.000000,0.000000) [0.000000|255.000000] "" ICAS1_Gateway LE1 LE2 Motor_BEV
 SG_ Airbag_01_BZ  : 8|4@1+ (1.000000,0.000000) [0.000000|15.000000] "" ICAS1_Gateway LE1 LE2 Motor_BEV
 SG_ AB_RGS_Anst  : 12|4@1+ (1.000000,0.000000) [0.000000|15.000000] "" ICAS1_Gateway ICAS1_KommunikationsServer
 SG_ AB_Front_Crash  : 16|1@1+ (1.000000,0.000000) [0.000000|1.000000] "" ICAS1_Gateway
 SG_ AB_Heck_Crash  : 17|1@1+ (1.000000,0.000000) [0.000000|1.000000] "" ICAS1_Gateway
 SG_ AB_SF_Crash  : 18|1@1+ (1.000000,0.000000) [0.000000|1.000000] "" ICAS1_Gateway
 SG_ AB_SB_Crash  : 19|1@1+ (1.000000,0.000000) [0.000000|1.000000] "" ICAS1_Gateway
 SG_ AB_Rollover_Crash  : 20|1@1+ (1.000000,0.000000) [0.000000|1.000000] "" ICAS1_Gateway
 SG_ AB_Crash_Int  : 21|3@1+ (1.000000,0.000000) [0.000000|7.000000] "" ICAS1_Gateway ICAS1_KommunikationsServer Motor_BEV
 SG_ AB_Lampe  : 24|1@1+ (1.000000,0.000000) [0.000000|1.000000] "" ICAS1_Gateway ICAS1_KommunikationsServer
 SG_ AB_Deaktiviert  : 25|1@1+ (1.000000,0.000000) [0.000000|1.000000] "" ICAS1_Gateway
 SG_ AB_VB_deaktiviert  : 26|1@1+ (1.000000,0.000000) [0.000000|1.000000] "" ICAS1_Gateway
 SG_ AB_Systemfehler  : 27|1@1+ (1.000000,0.000000) [0.000000|1.000000] "" ICAS1_Gateway ICAS1_KommunikationsServer
 SG_ AB_Diagnose  : 28|1@1+ (1.000000,0.000000) [0.000000|1.000000] "" ICAS1_Gateway
 SG_ AB_Stellgliedtest  : 29|1@1+ (1.000000,0.000000) [0.000000|1.000000] "" ICAS1_Gateway
 SG_ AB_Erh_Auf_VB  : 30|2@1+ (1.000000,0.000000) [0.000000|3.000000] "" ICAS1_Gateway
 SG_ AB_Gurtwarn_VF  : 32|1@1+ (1.000000,0.000000) [0.000000|1.000000] "" ICAS1_Gateway ICAS1_KommunikationsServer
 SG_ AB_Gurtwarn_VB  : 33|1@1+ (1.000000,0.000000) [0.000000|1.000000] "" ICAS1_Gateway ICAS1_KommunikationsServer
 SG_ AB_Anzeige_Fussg  : 34|2@1+ (1.000000,0.000000) [0.000000|3.000000] "" ICAS1_Gateway
 SG_ AB_Texte_AKS  : 36|2@1+ (1.000000,0.000000) [0.000000|3.000000] "" ICAS1_Gateway
 SG_ AB_PAO_Leuchte_Anf  : 38|1@1+ (1.000000,0.000000) [0.000000|1.000000] "" ICAS1_Gateway
 SG_ AB_MKB_gueltig  : 39|1@1+ (1.000000,0.000000) [0.000000|1.000000] "" ICAS1_Gateway
 SG_ AB_MKB_Anforderung  : 40|1@1+ (1.000000,0.000000) [0.000000|1.000000] "" ICAS1_Gateway
 SG_ AB_Versorgungsspannung  : 41|1@1+ (1.000000,0.000000) [0.000000|1.000000] "" ICAS1_Gateway
 SG_ AB_Deaktivierung_HV  : 42|3@1+ (1.000000,0.000000) [0.000000|7.000000] "" ICAS1_Gateway ICAS1_KommunikationsServer LE1 LE2 Motor_BEV
 SG_ AB_EDR_Trigger  : 45|2@1+ (1.000000,0.000000) [0.000000|3.000000] "" ICAS1_Gateway
 SG_ AB_Belegung_VF  : 47|2@1+ (1.000000,0.000000) [0.000000|3.000000] "" ICAS1_Gateway
 SG_ AB_Gurtschloss_FA_ext  : 49|3@1+ (1.000000,0.000000) [0.000000|7.000000] "" ICAS1_Gateway
 SG_ AB_Belegung_VF_ext  : 52|3@1+ (1.000000,0.000000) [0.000000|7.000000] "" ICAS1_Gateway
 SG_ ASM_Masterzeit  : 56|8@1+ (0.080000,0.000000) [0.000000|20.320000] "Unit_Secon" ICAS1_Gateway

BO_ 1312 Airbag_02: 8 Airbag
 SG_ Airbag_02_CRC  : 0|8@1+ (1.000000,0.000000) [0.000000|255.000000] "" ICAS1_Gateway Motor_BEV
 SG_ Airbag_02_BZ  : 8|4@1+ (1.000000,0.000000) [0.000000|15.000000] "" ICAS1_Gateway Motor_BEV
 SG_ LoGeWa_Event_Kombiwarnung  : 12|4@1+ (1.000000,0.000000) [0.000000|15.000000] "" ICAS1_Gateway
 SG_ AB_Anforderung_eCall  : 16|1@1+ (1.000000,0.000000) [0.000000|1.000000] "" ICAS1_Gateway
 SG_ AB_Anprall_Seite_Beifahrer  : 17|1@1+ (1.000000,0.000000) [0.000000|1.000000] "" ICAS1_Gateway ICAS1_KommunikationsServer
 SG_ AB_Anprall_Rollover  : 18|1@1+ (1.000000,0.000000) [0.000000|1.000000] "" ICAS1_Gateway ICAS1_KommunikationsServer
 SG_ AB_Anprall_FGS  : 19|1@1+ (1.000000,0.000000) [0.000000|1.000000] "" ICAS1_Gateway ICAS1_KommunikationsServer
 SG_ AB_Anprall_Front_Beifahrer  : 20|1@1+ (1.000000,0.000000) [0.000000|1.000000] "" ICAS1_Gateway ICAS1_KommunikationsServer
 SG_ AB_Anprall_Front_Fahrer  : 21|1@1+ (1.000000,0.000000) [0.000000|1.000000] "" ICAS1_Gateway ICAS1_KommunikationsServer
 SG_ AB_Anprall_Heck_Beifahrer  : 22|1@1+ (1.000000,0.000000) [0.000000|1.000000] "" ICAS1_Gateway ICAS1_KommunikationsServer
 SG_ AB_Anprall_Heck_Fahrer  : 23|1@1+ (1.000000,0.000000) [0.000000|1.000000] "" ICAS1_Gateway ICAS1_KommunikationsServer
 SG_ AB_Wickelklappung_Reihe2_MI  : 24|2@1+ (1.000000,0.000000) [0.000000|3.000000] "" ICAS1_Gateway
 SG_ AB_Belegung_VB  : 26|2@1+ (1.000000,0.000000) [0.000000|3.000000] "" ICAS1_Gateway
 SG_ AB_Abschaltanf_SIH_BF  : 28|1@1+ (1.000000,0.000000) [0.000000|1.000000] "" ICAS1_Gateway
 SG_ AB_Anprall_Seite_Fahrer  : 29|1@1+ (1.000000,0.000000) [0.000000|1.000000] "" ICAS1_Gateway ICAS1_KommunikationsServer
 SG_ SC_PAO_Schriftzug_Anf  : 30|2@1+ (1.000000,0.000000) [0.000000|3.000000] "" ICAS1_Gateway
 SG_ SC_PAO_ON_Anf  : 32|2@1+ (1.000000,0.000000) [0.000000|3.000000] "" ICAS1_Gateway
 SG_ SC_PAO_OFF_Anf  : 34|2@1+ (1.000000,0.000000) [0.000000|3.000000] "" ICAS1_Gateway
 SG_ AB_Crashschwere  : 36|3@1+ (1.000000,0.000000) [0.000000|7.000000] "" ICAS1_Gateway ICAS1_KommunikationsServer
 SG_ AB_Anforderung_USM  : 39|1@1+ (1.000000,0.000000) [0.000000|1.000000] "" ICAS1_Gateway
 SG_ AB_Gurtschloss_FA  : 40|2@1+ (1.000000,0.000000) [0.000000|3.000000] "" ICAS1_Gateway ICAS1_KommunikationsServer Motor_BEV
 SG_ AB_Gurtschloss_BF  : 42|2@1+ (1.000000,0.000000) [0.000000|3.000000] "" ICAS1_Gateway ICAS1_KommunikationsServer
 SG_ AB_Gurtschloss_Reihe2_FA  : 44|2@1+ (1.000000,0.000000) [0.000000|3.000000] "" ICAS1_Gateway ICAS1_KommunikationsServer
 SG_ AB_Gurtschloss_Reihe2_MI  : 46|2@1+ (1.000000,0.000000) [0.000000|3.000000] "" ICAS1_Gateway ICAS1_KommunikationsServer
 SG_ AB_Gurtschloss_Reihe2_BF  : 48|2@1+ (1.000000,0.000000) [0.000000|3.000000] "" ICAS1_Gateway ICAS1_KommunikationsServer
 SG_ AB_Gurtschloss_Reihe3_FA  : 50|2@1+ (1.000000,0.000000) [0.000000|3.000000] "" ICAS1_Gateway ICAS1_KommunikationsServer
 SG_ AB_Gurtschloss_Reihe3_MI  : 52|2@1+ (1.000000,0.000000) [0.000000|3.000000] "" ICAS1_Gateway ICAS1_KommunikationsServer
 SG_ AB_Gurtschloss_Reihe3_BF  : 54|2@1+ (1.000000,0.000000) [0.000000|3.000000] "" ICAS1_Gateway ICAS1_KommunikationsServer
 SG_ AB_Sitzpos_Sens_FA  : 56|2@1+ (1.000000,0.000000) [0.000000|3.000000] "" ICAS1_Gateway
 SG_ AB_Sitzpos_Sens_BF  : 58|2@1+ (1.000000,0.000000) [0.000000|3.000000] "" ICAS1_Gateway
 SG_ AB_Wickelklappung_Reihe2_BF  : 60|2@1+ (1.000000,0.000000) [0.000000|3.000000] "" ICAS1_Gateway
 SG_ AB_Wickelklappung_Reihe2_FA  : 62|2@1+ (1.000000,0.000000) [0.000000|3.000000] "" ICAS1_Gateway

BO_ 65 Airbag_03: 8 Airbag
 SG_ Airbag_03_CRC  : 0|8@1+ (1.000000,0.000000) [0.000000|255.000000] "" ICAS1_Gateway
 SG_ Airbag_03_BZ  : 8|4@1+ (1.000000,0.000000) [0.000000|15.000000] "" ICAS1_Gateway
 SG_ AB_MKB_Safing  : 63|1@1+ (1.000000,0.000000) [0.000000|1.000000] "" ICAS1_Gateway

BO_ 1349 Airbag_04: 8 Airbag
 SG_ AB_Gurtwarn_Reihe4_FA  : 14|2@1+ (1.000000,0.000000) [0.000000|3.000000] "" ICAS1_Gateway ICAS1_KommunikationsServer
 SG_ AB_Gurtwarn_Reihe4_BF  : 16|2@1+ (1.000000,0.000000) [0.000000|3.000000] "" ICAS1_Gateway ICAS1_KommunikationsServer
 SG_ AB_Gurtwarn_Reihe4_MI  : 18|2@1+ (1.000000,0.000000) [0.000000|3.000000] "" ICAS1_Gateway ICAS1_KommunikationsServer
 SG_ AB_Gurtwarn_Reihe2_FA  : 20|2@1+ (1.000000,0.000000) [0.000000|3.000000] "" ICAS1_Gateway ICAS1_KommunikationsServer
 SG_ AB_Gurtwarn_Reihe2_BF  : 22|2@1+ (1.000000,0.000000) [0.000000|3.000000] "" ICAS1_Gateway ICAS1_KommunikationsServer
 SG_ AbstWarn_MV_FAS_Fkt_Status  : 24|2@1+ (1.000000,0.000000) [0.000000|3.000000] "" ICAS1_Gateway
 SG_ WarnBrems_Charisma_Status  : 26|2@1+ (1.000000,0.000000) [0.000000|3.000000] "" ICAS1_Gateway
 SG_ WarnBrems_Charisma_FahrPr  : 28|4@1+ (1.000000,0.000000) [0.000000|15.000000] "" ICAS1_Gateway
 SG_ AB_Gurtwarn_Reihe2_MI  : 32|2@1+ (1.000000,0.000000) [0.000000|3.000000] "" ICAS1_Gateway ICAS1_KommunikationsServer
 SG_ AB_Gurtwarn_Reihe3_FA  : 34|2@1+ (1.000000,0.000000) [0.000000|3.000000] "" ICAS1_Gateway ICAS1_KommunikationsServer
 SG_ AB_Gurtwarn_Reihe3_MI  : 36|2@1+ (1.000000,0.000000) [0.000000|3.000000] "" ICAS1_Gateway ICAS1_KommunikationsServer
 SG_ AB_Gurtwarn_Reihe3_BF  : 38|2@1+ (1.000000,0.000000) [0.000000|3.000000] "" ICAS1_Gateway ICAS1_KommunikationsServer
 SG_ LGI_FAS_Fkt_Status  : 40|2@1+ (1.000000,0.000000) [0.000000|3.000000] "" ICAS1_Gateway
 SG_ PreCrash_FAS_Fkt_Status  : 42|3@1+ (1.000000,0.000000) [0.000000|7.000000] "" ICAS1_Gateway
 SG_ AB_SBR_hinten_verbau  : 48|2@1+ (1.000000,0.000000) [0.000000|3.000000] "" ICAS1_Gateway ICAS1_KommunikationsServer
 SG_ AWV_Einstellung_System_ASG  : 51|1@1+ (1.000000,0.000000) [0.000000|1.000000] "" ICAS1_Gateway
 SG_ AWV_Einstellung_Warnung_ASG  : 52|3@1+ (1.000000,0.000000) [0.000000|7.000000] "" ICAS1_Gateway
 SG_ SC_PreSense_Modus_Warnung_NV  : 55|3@1+ (1.000000,0.000000) [0.000000|7.000000] "" ICAS1_Gateway
 SG_ SC_PreSense_Modus_Warnung_MV  : 58|3@1+ (1.000000,0.000000) [0.000000|7.000000] "" ICAS1_Gateway
 SG_ SC_PreSense_Modus_System_MV  : 61|1@1+ (1.000000,0.000000) [0.000000|1.000000] "" ICAS1_Gateway
 SG_ SC_PreSense_Modus_System_NV  : 62|1@1+ (1.000000,0.000000) [0.000000|1.000000] "" ICAS1_Gateway
 SG_ SC_PreSense_Modus_System_KAS  : 63|1@1+ (1.000000,0.000000) [0.000000|1.000000] "" ICAS1_Gateway

BO_ 2527679722 Airbag_06: 8 Airbag
 SG_ AB_Gurtschloss_Reihe4_FA  : 12|2@1+ (1.000000,0.000000) [0.000000|3.000000] "" ICAS1_Gateway ICAS1_KommunikationsServer
 SG_ AB_Gurtschloss_Reihe4_BF  : 14|2@1+ (1.000000,0.000000) [0.000000|3.000000] "" ICAS1_Gateway ICAS1_KommunikationsServer
 SG_ AB_Gurtschloss_Reihe4_MI  : 16|2@1+ (1.000000,0.000000) [0.000000|3.000000] "" ICAS1_Gateway ICAS1_KommunikationsServer

BO_ 1633 Anhaenger_01: 8 ICAS1_Gateway
 SG_ AAG_BZ  : 0|4@1+ (1.000000,0.000000) [0.000000|15.000000] "" Vector__XXX
 SG_ AAG_AVS_Fehler_02_inv  : 4|1@1+ (1.000000,0.000000) [0.000000|1.000000] "" Vector__XXX
 SG_ AAG_Bremsl_durch_ECD  : 5|1@1+ (1.000000,0.000000) [0.000000|1.000000] "" Motor_BEV
 SG_ AAG_Anhaenger_abgesteckt  : 6|1@1+ (1.000000,0.000000) [0.000000|1.000000] "" Motor_BEV
 SG_ AAG_NSL_aktiv  : 7|1@1+ (1.000000,0.000000) [0.000000|1.000000] "" Vector__XXX
 SG_ AAG_Anhaenger_erkannt  : 8|1@1+ (1.000000,0.000000) [0.000000|1.000000] "" Motor_BEV
 SG_ AAG_Blinker_H_aktiv  : 9|1@1+ (1.000000,0.000000) [0.000000|1.000000] "" Vector__XXX
 SG_ AAG_Blinker_HL_def  : 10|1@1+ (1.000000,0.000000) [0.000000|1.000000] "" Vector__XXX
 SG_ AAG_Blinker_HR_def  : 11|1@1+ (1.000000,0.000000) [0.000000|1.000000] "" Vector__XXX
 SG_ AAG_Bremslicht_H_def  : 12|1@1+ (1.000000,0.000000) [0.000000|1.000000] "" Motor_BEV
 SG_ AAG_Schlusslicht_HL_def  : 13|1@1+ (1.000000,0.000000) [0.000000|1.000000] "" Vector__XXX
 SG_ AAG_Schlusslicht_HR_def  : 14|1@1+ (1.000000,0.000000) [0.000000|1.000000] "" Vector__XXX
 SG_ AAG_Bremslicht_Reku  : 15|1@1+ (1.000000,0.000000) [0.000000|1.000000] "" Vector__XXX
 SG_ AAG_AVS_Fehler_02  : 18|1@1+ (1.000000,0.000000) [0.000000|1.000000] "" Vector__XXX
 SG_ AAG_LED_aktiv  : 19|1@1+ (1.000000,0.000000) [0.000000|1.000000] "" Vector__XXX
 SG_ AAG_AVS_Stati  : 20|4@1+ (1.000000,0.000000) [0.000000|15.000000] "" Vector__XXX

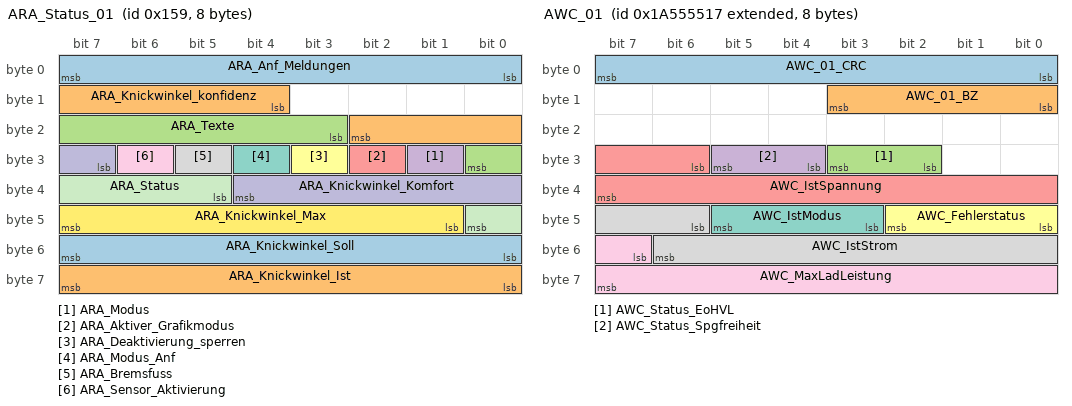
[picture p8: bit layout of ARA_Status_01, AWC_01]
BO_ 345 ARA_Status_01: 8 ICAS1_Gateway
 SG_ ARA_Anf_Meldungen  : 0|8@1+ (1.000000,0.000000) [0.000000|255.000000] "" Vector__XXX
 SG_ ARA_Knickwinkel_konfidenz  : 12|7@1+ (1.000000,0.000000) [0.000000|120.000000] "Unit_DegreOfArc" Vector__XXX
 SG_ ARA_Texte  : 19|6@1+ (1.000000,0.000000) [0.000000|63.000000] "" Vector__XXX
 SG_ ARA_Modus  : 25|1@1+ (1.000000,0.000000) [0.000000|1.000000] "" Vector__XXX
 SG_ ARA_Aktiver_Grafikmodus  : 26|1@1+ (1.000000,0.000000) [0.000000|1.000000] "" Vector__XXX
 SG_ ARA_Deaktivierung_sperren  : 27|1@1+ (1.000000,0.000000) [0.000000|1.000000] "" Vector__XXX
 SG_ ARA_Modus_Anf  : 28|1@1+ (1.000000,0.000000) [0.000000|1.000000] "" Vector__XXX
 SG_ ARA_Bremsfuss  : 29|1@1+ (1.000000,0.000000) [0.000000|1.000000] "" Vector__XXX
 SG_ ARA_Sensor_Aktivierung  : 30|1@1+ (1.000000,0.000000) [0.000000|1.000000] "" Vector__XXX
 SG_ ARA_Knickwinkel_Komfort  : 31|6@1+ (1.000000,0.000000) [0.000000|60.000000] "Unit_DegreOfArc" Vector__XXX
 SG_ ARA_Status  : 37|4@1+ (1.000000,0.000000) [0.000000|15.000000] "" Motor_BEV
 SG_ ARA_Knickwinkel_Max  : 41|7@1+ (1.000000,0.000000) [0.000000|120.000000] "Unit_DegreOfArc" Vector__XXX
 SG_ ARA_Knickwinkel_Soll  : 48|8@1+ (1.000000,-125.000000) [-125.000000|126.000000] "Unit_DegreOfArc" Vector__XXX
 SG_ ARA_Knickwinkel_Ist  : 56|8@1+ (1.000000,-125.000000) [-125.000000|126.000000] "Unit_DegreOfArc" Vector__XXX

BO_ 2589283607 AWC_01: 8 ICAS1_Gateway
 SG_ AWC_01_CRC  : 0|8@1+ (1.000000,0.000000) [0.000000|255.000000] "" Vector__XXX
 SG_ AWC_01_BZ  : 8|4@1+ (1.000000,0.000000) [0.000000|15.000000] "" Vector__XXX
 SG_ AWC_Status_EoHVL  : 26|2@1+ (1.000000,0.000000) [0.000000|3.000000] "" Motor_BEV
 SG_ AWC_Status_Spgfreiheit  : 28|2@1+ (1.000000,0.000000) [0.000000|3.000000] "" Vector__XXX
 SG_ AWC_IstSpannung  : 30|10@1+ (1.000000,0.000000) [0.000000|1021.000000] "Unit_Volt" Vector__XXX
 SG_ AWC_Fehlerstatus  : 40|3@1+ (1.000000,0.000000) [0.000000|7.000000] "" Vector__XXX
 SG_ AWC_IstModus  : 43|3@1+ (1.000000,0.000000) [0.000000|7.000000] "" Vector__XXX
 SG_ AWC_IstStrom  : 46|9@1+ (0.100000,0.000000) [0.000000|50.900000] "Unit_Amper" Vector__XXX
 SG_ AWC_MaxLadLeistung  : 55|9@1+ (25.000000,0.000000) [0.000000|12725.000000] "Unit_Watt" Vector__XXX

BO_ 219 AWV_03: 48 ICAS1_Gateway
 SG_ AWV_03_CRC  : 0|8@1+ (1.000000,0.000000) [0.000000|255.000000] "" Airbag
 SG_ AWV_03_BZ  : 8|4@1+ (1.000000,0.000000) [0.000000|15.000000] "" Airbag
 SG_ PCF_Freigabe  : 12|1@1+ (1.000000,0.000000) [0.000000|1.000000] "" Airbag
 SG_ SDF_PSF_Objektstatus  : 13|3@1+ (1.000000,0.000000) [0.000000|7.000000] "" Airbag
 SG_ SDF_PSF_CU_Status  : 16|1@1+ (1.000000,0.000000) [0.000000|1.000000] "" Airbag
 SG_ SDF_PSF_CW  : 17|7@1+ (1.000000,0.000000) [0.000000|100.000000] "" Airbag
 SG_ SDF_PSF_Fahrer_aktiv  : 24|1@1+ (1.000000,0.000000) [0.000000|1.000000] "" Airbag
 SG_ SDF_PSF_Guete  : 25|2@1+ (1.000000,0.000000) [0.000000|3.000000] "" Airbag
 SG_ SDF_PSF_Kollisionsueberdeckung  : 27|5@1+ (0.100000,0.000000) [0.100000|2.800000] "Unit_Meter" Airbag
 SG_ SDF_PSF_Time_To_Collision  : 32|8@1+ (0.010000,0.000000) [0.000000|2.500000] "Unit_Secon" Vector__XXX
 SG_ SDF_PSF_v_rel  : 40|8@1+ (0.400000,0.000000) [0.400000|101.200000] "Unit_MeterPerSecon" Airbag
 SG_ AWV_Eingriff_Sendeart  : 64|1@1+ (1.000000,0.000000) [0.000000|1.000000] "" Airbag
 SG_ AWV_Verz_Freigabe  : 65|1@1+ (1.000000,0.000000) [0.000000|1.000000] "" Airbag
 SG_ AWV_Verz_Anf  : 66|10@1+ (0.024000,-20.016000) [-20.016000|4.512000] "Unit_MeterPerSeconSquar" Airbag
 SG_ AWV_Anf_Prefill  : 76|1@1+ (1.000000,0.000000) [0.000000|1.000000] "" Airbag
 SG_ AWV_Ruckprofil  : 77|3@1+ (1.000000,0.000000) [0.000000|7.000000] "" Vector__XXX
 SG_ AWV_Time_to_collision  : 80|8@1+ (0.010000,0.000000) [0.000000|2.500000] "Unit_Secon" Airbag
 SG_ AWV_HBA_Param  : 88|2@1+ (1.000000,0.000000) [0.000000|3.000000] "" Vector__XXX
 SG_ AWV_Verz_Anf_ASIL  : 90|3@1+ (1.000000,0.000000) [0.000000|7.000000] "" Vector__XXX
 SG_ AWV_Time_to_brake  : 93|7@1+ (10.000000,0.000000) [0.000000|1240.000000] "Unit_MilliSecon" Vector__XXX
 SG_ AWV_Zielobjekttyp  : 100|4@1+ (1.000000,0.000000) [0.000000|15.000000] "" Airbag
 SG_ AWV_QFK_KruemmSoll  : 104|15@1+ (0.000007,0.000000) [0.000000|0.219539] "Unit_MeterInver" Vector__XXX
 SG_ AWV_QFK_KruemmSoll_VZ  : 119|1@1+ (1.000000,0.000000) [0.000000|1.000000] "" Vector__XXX
 SG_ AWV_QFK_Spuerb  : 120|8@1+ (0.400000,0.000000) [0.000000|100.000000] "Unit_PerCent" Vector__XXX
 SG_ AWV_QFK_AnfStat  : 128|4@1+ (1.000000,0.000000) [0.000000|15.000000] "" Airbag
 SG_ AWV_QFK_Signal1  : 132|10@1+ (1.000000,0.000000) [0.000000|1023.000000] "" Vector__XXX
 SG_ AWV_QFK_Art1  : 142|3@1+ (1.000000,0.000000) [0.000000|7.000000] "" Vector__XXX
 SG_ AWV_QFK_Art2  : 145|3@1+ (1.000000,0.000000) [0.000000|7.000000] "" Vector__XXX
 SG_ AWV_QFK_Signal2  : 148|10@1+ (1.000000,0.000000) [0.000000|1023.000000] "" Vector__XXX

BO_ 2536767264 BAP_Debug_Cmd: 8 BAP_Tester
 SG_ BAP_Debug_Cmd  : 0|16@1+ (1.000000,0.000000) [0.000000|65535.000000] "" Motor_BEV

BO_ 2536767280 BAP_Debug_Data: 8 Motor_BEV
 SG_ BAP_Debug_Data  : 0|64@1+ (1.000000,0.000000) [0.000000|18446744073709551616.000000] "" BAP_Tester

BO_ 2536717313 BAP_EfficiencyAssist_ASG_02: 8 ICAS1_Gateway
 SG_ BAP_EfficAssist_ASG_02_Header  : 0|64@1+ (1.000000,0.000000) [0.000000|18446744073709551616.000000] "" Motor_BEV

BO_ 2536717314 BAP_EfficiencyAssist_ASG_03: 8 ICAS1_Gateway
 SG_ BAP_EfficAssist_ASG_03_Header  : 0|8@1+ (1.000000,0.000000) [0.000000|255.000000] "" Motor_BEV

BO_ 2536717328 BAP_EfficiencyAssist_FSG_01: 8 Motor_BEV
 SG_ BAP_EfficAssist_FSG_01_Header  : 0|8@1+ (1.000000,0.000000) [0.000000|255.000000] "" ICAS1_Gateway

BO_ 2536709120 BAP_Hybrid_ASG_01: 8 ICAS1_Gateway
 SG_ BAP_Hybrid_ASG_01_Header  : 0|8@1+ (1.000000,0.000000) [0.000000|255.000000] "" Motor_BEV

BO_ 2536709136 BAP_Hybrid_FSG_01: 8 Motor_BEV
 SG_ BAP_Hybrid_FSG_01_Header  : 0|8@1+ (1.000000,0.000000) [0.000000|255.000000] "" ICAS1_Gateway

BO_ 869 BEM_05: 8 ICAS1_Gateway
 SG_ BEM_UBDM  : 0|8@1+ (0.050000,5.000000) [5.050000|17.700000] "Unit_Volt" Vector__XXX
 SG_ NVEM_Ladefreigabe  : 8|2@1+ (1.000000,0.000000) [0.000000|3.000000] "" Vector__XXX
 SG_ NVEM_FMAus_Info  : 10|2@1+ (1.000000,0.000000) [0.000000|3.000000] "" Vector__XXX
 SG_ NVEM_PTC_Sollstufe  : 12|2@1+ (1.000000,0.000000) [0.000000|3.000000] "" Vector__XXX
 SG_ NVEM_P_Generator_Status  : 15|1@1+ (1.000000,0.000000) [0.000000|1.000000] "" Vector__XXX
 SG_ BEM_P_Generator  : 16|8@1+ (50.000000,0.000000) [0.000000|12700.000000] "Unit_Watt" Vector__XXX
 SG_ BEM_n_LLA  : 24|2@1+ (1.000000,0.000000) [0.000000|3.000000] "" Vector__XXX
 SG_ BEM_01_Abschaltstufen  : 26|3@1+ (1.000000,0.000000) [0.000000|7.000000] "" Vector__XXX
 SG_ BEM_Anf_KL  : 29|1@1+ (1.000000,0.000000) [0.000000|1.000000] "" Vector__XXX
 SG_ BEM_StartStopp_Info  : 30|2@1+ (1.000000,0.000000) [0.000000|3.000000] "" Vector__XXX
 SG_ BEM_DFM  : 32|5@1+ (3.225000,0.025000) [0.025000|100.000000] "" Vector__XXX
 SG_ BEM_EMLIN_ungueltig  : 37|1@1+ (1.000000,0.000000) [0.000000|1.000000] "" Vector__XXX
 SG_ BEM_Batt_Ab  : 38|1@1+ (1.000000,0.000000) [0.000000|1.000000] "" Motor_BEV
 SG_ NVEM_FMAus_I_Verbrauch  : 39|5@1+ (5.000000,0.000000) [0.000000|145.000000] "Unit_Amper" Vector__XXX
 SG_ NVEM_Freilauf_Info  : 44|2@1+ (1.000000,0.000000) [0.000000|3.000000] "" Vector__XXX
 SG_ BEM_NV_NachladAnf  : 46|2@1+ (1.000000,0.000000) [0.000000|3.000000] "" Vector__XXX
 SG_ BEM_Segel_Info  : 48|2@1+ (1.000000,0.000000) [0.000000|3.000000] "" Vector__XXX
 SG_ BEM_HYB_DC_uSollLV  : 50|6@1+ (0.100000,10.600000) [10.600000|16.000000] "Unit_Volt" Vector__XXX
 SG_ BEM_HYB_DC_uMinLV  : 56|8@1+ (0.100000,0.000000) [0.000000|25.300000] "Unit_Volt" Vector__XXX

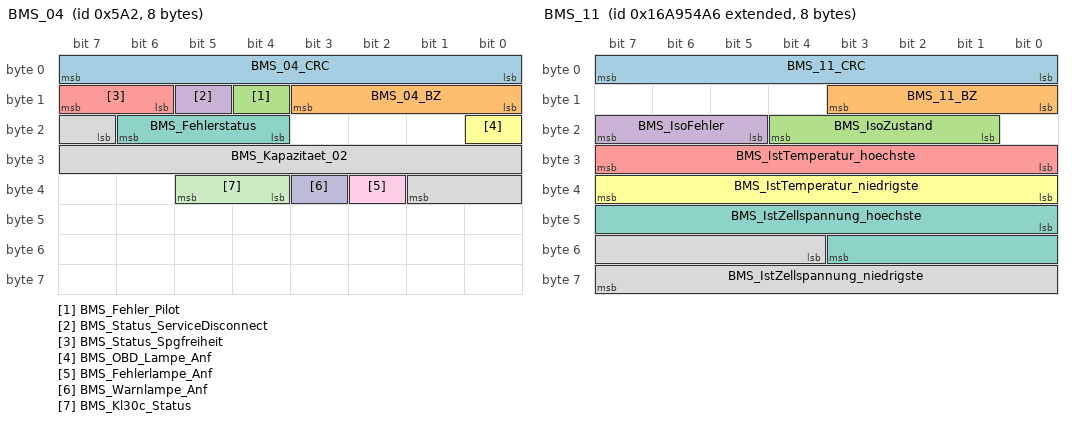
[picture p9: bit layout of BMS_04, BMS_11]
BO_ 1442 BMS_04: 8 ICAS1_Gateway
 SG_ BMS_04_CRC  : 0|8@1+ (1.000000,0.000000) [0.000000|255.000000] "" Vector__XXX
 SG_ BMS_04_BZ  : 8|4@1+ (1.000000,0.000000) [0.000000|15.000000] "" Vector__XXX
 SG_ BMS_Fehler_Pilot  : 12|1@1+ (1.000000,0.000000) [0.000000|1.000000] "" Vector__XXX
 SG_ BMS_Status_ServiceDisconnect  : 13|1@1+ (1.000000,0.000000) [0.000000|1.000000] "" Vector__XXX
 SG_ BMS_Status_Spgfreiheit  : 14|2@1+ (1.000000,0.000000) [0.000000|3.000000] "" Motor_BEV
 SG_ BMS_OBD_Lampe_Anf  : 16|1@1+ (1.000000,0.000000) [0.000000|1.000000] "" Motor_BEV
 SG_ BMS_Fehlerstatus  : 20|3@1+ (1.000000,0.000000) [0.000000|7.000000] "" Vector__XXX
 SG_ BMS_Kapazitaet_02  : 23|11@1+ (0.200000,0.000000) [0.000000|409.200000] "Unit_AmperHour" Vector__XXX
 SG_ BMS_Fehlerlampe_Anf  : 34|1@1+ (1.000000,0.000000) [0.000000|1.000000] "" Motor_BEV
 SG_ BMS_Warnlampe_Anf  : 35|1@1+ (1.000000,0.000000) [0.000000|1.000000] "" Motor_BEV
 SG_ BMS_Kl30c_Status  : 36|2@1+ (1.000000,0.000000) [0.000000|3.000000] "" Motor_BEV

BO_ 2527679654 BMS_11: 8 ICAS1_Gateway
 SG_ BMS_11_CRC  : 0|8@1+ (1.000000,0.000000) [0.000000|255.000000] "" Motor_BEV
 SG_ BMS_11_BZ  : 8|4@1+ (1.000000,0.000000) [0.000000|15.000000] "" Motor_BEV
 SG_ BMS_IsoZustand  : 17|4@1+ (1.000000,0.000000) [0.000000|15.000000] "" Motor_BEV
 SG_ BMS_IsoFehler  : 21|3@1+ (1.000000,0.000000) [0.000000|7.000000] "" Motor_BEV
 SG_ BMS_IstTemperatur_hoechste  : 24|8@1+ (0.500000,-40.000000) [-40.000000|86.000000] "Unit_DegreCelsi" Vector__XXX
 SG_ BMS_IstTemperatur_niedrigste  : 32|8@1+ (0.500000,-40.000000) [-40.000000|86.000000] "Unit_DegreCelsi" Vector__XXX
 SG_ BMS_IstZellspannung_hoechste  : 40|12@1+ (1.000000,1000.000000) [1000.000000|5091.000000] "Unit_MilliVolt" Vector__XXX
 SG_ BMS_IstZellspannung_niedrigste  : 52|12@1+ (1.000000,1000.000000) [1000.000000|5091.000000] "Unit_MilliVolt" Vector__XXX

BU_:  Airbag BAP_Tester ICAS1_Gateway ICAS1_KommunikationsServer LE1 LE2 Motor_BEV Schaltbetaetigung

BO_ 333 ACC_18: 32 ICAS1_Gateway
 SG_ ACC_18_CRC  : 0|8@1+ (1.000000,0.000000) [0.000000|255.000000] "" Motor_BEV
 SG_ ACC_18_BZ  : 8|4@1+ (1.000000,0.000000) [0.000000|15.000000] "" Motor_BEV
 SG_ ACC_limitierte_Anfahrdyn  : 12|1@0- (1.000000,0.000000) [0.000000|1.000000] "" Motor_BEV
 SG_ ACC_nachtr_Stopp_Anf  : 13|1@1+ (1.000000,0.000000) [0.000000|1.000000] "" Vector__XXX
 SG_ ACC_DynErhoehung  : 14|1@1+ (1.000000,0.000000) [0.000000|1.000000] "" Motor_BEV
 SG_ ACC_Freilaufstrategie_TSK  : 15|1@1+ (1.000000,0.000000) [0.000000|1.000000] "" Motor_BEV
 SG_ ACC_zul_Regelabw_unten  : 16|6@1+ (0.024000,0.000000) [0.000000|1.512000] "Unit_MeterPerSeconSquar" Motor_BEV
 SG_ ACC_StartStopp_Info  : 22|2@1+ (1.000000,0.000000) [0.000000|3.000000] "" Vector__XXX
 SG_ ACC_Sollbeschleunigung_02  : 24|11@1+ (0.005000,-7.220000) [-7.220000|3.005000] "Unit_MeterPerSeconSquar" Motor_BEV
 SG_ ACC_zul_Regelabw_oben  : 35|5@1+ (0.062500,0.000000) [0.000000|1.937500] "Unit_MeterPerSeconSquar" Motor_BEV
 SG_ ACC_neg_Sollbeschl_Grad_02  : 40|8@1+ (0.050000,0.000000) [0.000000|12.750000] "Unit_MeterPerCubicSecon" Motor_BEV
 SG_ ACC_pos_Sollbeschl_Grad_02  : 48|8@1+ (0.050000,0.000000) [0.000000|12.750000] "Unit_MeterPerCubicSecon" Motor_BEV
 SG_ ACC_Anfahren  : 56|1@1+ (1.000000,0.000000) [0.000000|1.000000] "" Motor_BEV
 SG_ ACC_Anhalten  : 57|1@1+ (1.000000,0.000000) [0.000000|1.000000] "" Motor_BEV
 SG_ ACC_Typ  : 58|2@1+ (1.000000,0.000000) [0.000000|3.000000] "" Motor_BEV
 SG_ ACC_Status_ACC  : 60|3@1+ (1.000000,0.000000) [0.000000|7.000000] "" Motor_BEV
 SG_ ACC_Minimale_Bremsung  : 63|1@1+ (1.000000,0.000000) [0.000000|1.000000] "" Motor_BEV
 SG_ ACC_Anhalteweg  : 64|11@1+ (0.010000,0.000000) [0.000000|20.450000] "Unit_Meter" Vector__XXX
 SG_ ACC_Boost  : 75|1@1+ (1.000000,0.000000) [0.000000|1.000000] "" Vector__XXX
 SG_ ACC_Freilauf_Anf  : 76|1@1+ (1.000000,0.000000) [0.000000|1.000000] "" Vector__XXX
 SG_ ACC_Anforderung_HMS  : 77|3@1+ (1.000000,0.000000) [0.000000|7.000000] "" Vector__XXX
 SG_ ACC_Folgebeschl  : 80|8@1+ (0.030000,-4.600000) [-4.600000|2.990000] "Unit_MeterPerSeconSquar" Motor_BEV
 SG_ ACC_Freilauf_Info  : 88|2@1+ (1.000000,0.000000) [0.000000|3.000000] "" Motor_BEV
 SG_ ACC_Tempolimitassistent_Ein  : 90|1@1+ (1.000000,0.000000) [0.000000|1.000000] "" Vector__XXX
 SG_ ACC_FoD_Status  : 91|2@1+ (1.000000,0.000000) [0.000000|3.000000] "" Motor_BEV
 SG_ vESC_Verz_Anf  : 232|4@1+ (0.500000,0.000000) [0.000000|3.500000] "Unit_MeterPerSeconSquar" Vector__XXX
 SG_ RDR_v_ueber_Grund  : 236|12@1+ (0.100000,0.000000) [0.000000|409.000000] "Unit_KiloMeterPerHour" Vector__XXX
 SG_ RDR_v_ueber_Grund_Genauigkeit  : 248|6@1+ (0.100000,0.000000) [0.000000|6.000000] "Unit_KiloMeterPerHour" Vector__XXX
 SG_ RDR_v_ueber_Grund_Fahrtrichtung  : 254|2@1+ (1.000000,0.000000) [0.000000|3.000000] "" Vector__XXX

BO_ 2527679682 ACC_ASM_01: 8 ICAS1_Gateway
 SG_ ACC_ASM_Ereignis  : 0|8@1+ (1.000000,0.000000) [1.000000|254.000000] "" Airbag
 SG_ ACC_ASM_Zeitstempel  : 8|8@1+ (0.080000,0.000000) [0.000000|20.320000] "Unit_Secon" Airbag
 SG_ ACC_ASM_Data_1  : 16|8@1+ (1.000000,0.000000) [0.000000|255.000000] "" Airbag
 SG_ ACC_ASM_Data_2  : 24|8@1+ (1.000000,0.000000) [0.000000|255.000000] "" Airbag
 SG_ ACC_ASM_Data_3  : 32|8@1+ (1.000000,0.000000) [0.000000|255.000000] "" Airbag
 SG_ ACC_ASM_Data_4  : 40|8@1+ (1.000000,0.000000) [0.000000|255.000000] "" Airbag
 SG_ ACC_ASM_Data_5  : 48|8@1+ (1.000000,0.000000) [0.000000|255.000000] "" Airbag
 SG_ ACC_ASM_Data_6  : 56|8@1+ (1.000000,0.000000) [0.000000|255.000000] "" Airbag

BO_ 64 Airbag_01: 8 Airbag
 SG_ Airbag_01_CRC  : 0|8@1+ (1.000000,0.000000) [0.000000|255.000000] "" ICAS1_Gateway LE1 LE2 Motor_BEV
 SG_ Airbag_01_BZ  : 8|4@1+ (1.000000,0.000000) [0.000000|15.000000] "" ICAS1_Gateway LE1 LE2 Motor_BEV
 SG_ AB_RGS_Anst  : 12|4@1+ (1.000000,0.000000) [0.000000|15.000000] "" ICAS1_Gateway ICAS1_KommunikationsServer
 SG_ AB_Front_Crash  : 16|1@1+ (1.000000,0.000000) [0.000000|1.000000] "" ICAS1_Gateway
 SG_ AB_Heck_Crash  : 17|1@1+ (1.000000,0.000000) [0.000000|1.000000] "" ICAS1_Gateway
 SG_ AB_SF_Crash  : 18|1@1+ (1.000000,0.000000) [0.000000|1.000000] "" ICAS1_Gateway
 SG_ AB_SB_Crash  : 19|1@1+ (1.000000,0.000000) [0.000000|1.000000] "" ICAS1_Gateway
 SG_ AB_Rollover_Crash  : 20|1@1+ (1.000000,0.000000) [0.000000|1.000000] "" ICAS1_Gateway
 SG_ AB_Crash_Int  : 21|3@1+ (1.000000,0.000000) [0.000000|7.000000] "" ICAS1_Gateway ICAS1_KommunikationsServer Motor_BEV
 SG_ AB_Lampe  : 24|1@1+ (1.000000,0.000000) [0.000000|1.000000] "" ICAS1_Gateway ICAS1_KommunikationsServer
 SG_ AB_Deaktiviert  : 25|1@1+ (1.000000,0.000000) [0.000000|1.000000] "" ICAS1_Gateway
 SG_ AB_VB_deaktiviert  : 26|1@1+ (1.000000,0.000000) [0.000000|1.000000] "" ICAS1_Gateway
 SG_ AB_Systemfehler  : 27|1@1+ (1.000000,0.000000) [0.000000|1.000000] "" ICAS1_Gateway ICAS1_KommunikationsServer
 SG_ AB_Diagnose  : 28|1@1+ (1.000000,0.000000) [0.000000|1.000000] "" ICAS1_Gateway
 SG_ AB_Stellgliedtest  : 29|1@1+ (1.000000,0.000000) [0.000000|1.000000] "" ICAS1_Gateway
 SG_ AB_Erh_Auf_VB  : 30|2@1+ (1.000000,0.000000) [0.000000|3.000000] "" ICAS1_Gateway
 SG_ AB_Gurtwarn_VF  : 32|1@1+ (1.000000,0.000000) [0.000000|1.000000] "" ICAS1_Gateway ICAS1_KommunikationsServer
 SG_ AB_Gurtwarn_VB  : 33|1@1+ (1.000000,0.000000) [0.000000|1.000000] "" ICAS1_Gateway ICAS1_KommunikationsServer
 SG_ AB_Anzeige_Fussg  : 34|2@1+ (1.000000,0.000000) [0.000000|3.000000] "" ICAS1_Gateway
 SG_ AB_Texte_AKS  : 36|2@1+ (1.000000,0.000000) [0.000000|3.000000] "" ICAS1_Gateway
 SG_ AB_PAO_Leuchte_Anf  : 38|1@1+ (1.000000,0.000000) [0.000000|1.000000] "" ICAS1_Gateway
 SG_ AB_MKB_gueltig  : 39|1@1+ (1.000000,0.000000) [0.000000|1.000000] "" ICAS1_Gateway
 SG_ AB_MKB_Anforderung  : 40|1@1+ (1.000000,0.000000) [0.000000|1.000000] "" ICAS1_Gateway
 SG_ AB_Versorgungsspannung  : 41|1@1+ (1.000000,0.000000) [0.000000|1.000000] "" ICAS1_Gateway
 SG_ AB_Deaktivierung_HV  : 42|3@1+ (1.000000,0.000000) [0.000000|7.000000] "" ICAS1_Gateway ICAS1_KommunikationsServer LE1 LE2 Motor_BEV
 SG_ AB_EDR_Trigger  : 45|2@1+ (1.000000,0.000000) [0.000000|3.000000] "" ICAS1_Gateway
 SG_ AB_Belegung_VF  : 47|2@1+ (1.000000,0.000000) [0.000000|3.000000] "" ICAS1_Gateway
 SG_ AB_Gurtschloss_FA_ext  : 49|3@1+ (1.000000,0.000000) [0.000000|7.000000] "" ICAS1_Gateway
 SG_ AB_Belegung_VF_ext  : 52|3@1+ (1.000000,0.000000) [0.000000|7.000000] "" ICAS1_Gateway
 SG_ ASM_Masterzeit  : 56|8@1+ (0.080000,0.000000) [0.000000|20.320000] "Unit_Secon" ICAS1_Gateway

BO_ 1312 Airbag_02: 8 Airbag
 SG_ Airbag_02_CRC  : 0|8@1+ (1.000000,0.000000) [0.000000|255.000000] "" ICAS1_Gateway Motor_BEV
 SG_ Airbag_02_BZ  : 8|4@1+ (1.000000,0.000000) [0.000000|15.000000] "" ICAS1_Gateway Motor_BEV
 SG_ LoGeWa_Event_Kombiwarnung  : 12|4@1+ (1.000000,0.000000) [0.000000|15.000000] "" ICAS1_Gateway
 SG_ AB_Anforderung_eCall  : 16|1@1+ (1.000000,0.000000) [0.000000|1.000000] "" ICAS1_Gateway
 SG_ AB_Anprall_Seite_Beifahrer  : 17|1@1+ (1.000000,0.000000) [0.000000|1.000000] "" ICAS1_Gateway ICAS1_KommunikationsServer
 SG_ AB_Anprall_Rollover  : 18|1@1+ (1.000000,0.000000) [0.000000|1.000000] "" ICAS1_Gateway ICAS1_KommunikationsServer
 SG_ AB_Anprall_FGS  : 19|1@1+ (1.000000,0.000000) [0.000000|1.000000] "" ICAS1_Gateway ICAS1_KommunikationsServer
 SG_ AB_Anprall_Front_Beifahrer  : 20|1@1+ (1.000000,0.000000) [0.000000|1.000000] "" ICAS1_Gateway ICAS1_KommunikationsServer
 SG_ AB_Anprall_Front_Fahrer  : 21|1@1+ (1.000000,0.000000) [0.000000|1.000000] "" ICAS1_Gateway ICAS1_KommunikationsServer
 SG_ AB_Anprall_Heck_Beifahrer  : 22|1@1+ (1.000000,0.000000) [0.000000|1.000000] "" ICAS1_Gateway ICAS1_KommunikationsServer
 SG_ AB_Anprall_Heck_Fahrer  : 23|1@1+ (1.000000,0.000000) [0.000000|1.000000] "" ICAS1_Gateway ICAS1_KommunikationsServer
 SG_ AB_Wickelklappung_Reihe2_MI  : 24|2@1+ (1.000000,0.000000) [0.000000|3.000000] "" ICAS1_Gateway
 SG_ AB_Belegung_VB  : 26|2@1+ (1.000000,0.000000) [0.000000|3.000000] "" ICAS1_Gateway
 SG_ AB_Abschaltanf_SIH_BF  : 28|1@1+ (1.000000,0.000000) [0.000000|1.000000] "" ICAS1_Gateway
 SG_ AB_Anprall_Seite_Fahrer  : 29|1@1+ (1.000000,0.000000) [0.000000|1.000000] "" ICAS1_Gateway ICAS1_KommunikationsServer
 SG_ SC_PAO_Schriftzug_Anf  : 30|2@1+ (1.000000,0.000000) [0.000000|3.000000] "" ICAS1_Gateway
 SG_ SC_PAO_ON_Anf  : 32|2@1+ (1.000000,0.000000) [0.000000|3.000000] "" ICAS1_Gateway
 SG_ SC_PAO_OFF_Anf  : 34|2@1+ (1.000000,0.000000) [0.000000|3.000000] "" ICAS1_Gateway
 SG_ AB_Crashschwere  : 36|3@1+ (1.000000,0.000000) [0.000000|7.000000] "" ICAS1_Gateway ICAS1_KommunikationsServer
 SG_ AB_Anforderung_USM  : 39|1@1+ (1.000000,0.000000) [0.000000|1.000000] "" ICAS1_Gateway
 SG_ AB_Gurtschloss_FA  : 40|2@1+ (1.000000,0.000000) [0.000000|3.000000] "" ICAS1_Gateway ICAS1_KommunikationsServer Motor_BEV
 SG_ AB_Gurtschloss_BF  : 42|2@1+ (1.000000,0.000000) [0.000000|3.000000] "" ICAS1_Gateway ICAS1_KommunikationsServer
 SG_ AB_Gurtschloss_Reihe2_FA  : 44|2@1+ (1.000000,0.000000) [0.000000|3.000000] "" ICAS1_Gateway ICAS1_KommunikationsServer
 SG_ AB_Gurtschloss_Reihe2_MI  : 46|2@1+ (1.000000,0.000000) [0.000000|3.000000] "" ICAS1_Gateway ICAS1_KommunikationsServer
 SG_ AB_Gurtschloss_Reihe2_BF  : 48|2@1+ (1.000000,0.000000) [0.000000|3.000000] "" ICAS1_Gateway ICAS1_KommunikationsServer
 SG_ AB_Gurtschloss_Reihe3_FA  : 50|2@1+ (1.000000,0.000000) [0.000000|3.000000] "" ICAS1_Gateway ICAS1_KommunikationsServer
 SG_ AB_Gurtschloss_Reihe3_MI  : 52|2@1+ (1.000000,0.000000) [0.000000|3.000000] "" ICAS1_Gateway ICAS1_KommunikationsServer
 SG_ AB_Gurtschloss_Reihe3_BF  : 54|2@1+ (1.000000,0.000000) [0.000000|3.000000] "" ICAS1_Gateway ICAS1_KommunikationsServer
 SG_ AB_Sitzpos_Sens_FA  : 56|2@1+ (1.000000,0.000000) [0.000000|3.000000] "" ICAS1_Gateway
 SG_ AB_Sitzpos_Sens_BF  : 58|2@1+ (1.000000,0.000000) [0.000000|3.000000] "" ICAS1_Gateway
 SG_ AB_Wickelklappung_Reihe2_BF  : 60|2@1+ (1.000000,0.000000) [0.000000|3.000000] "" ICAS1_Gateway
 SG_ AB_Wickelklappung_Reihe2_FA  : 62|2@1+ (1.000000,0.000000) [0.000000|3.000000] "" ICAS1_Gateway

BO_ 65 Airbag_03: 8 Airbag
 SG_ Airbag_03_CRC  : 0|8@1+ (1.000000,0.000000) [0.000000|255.000000] "" ICAS1_Gateway
 SG_ Airbag_03_BZ  : 8|4@1+ (1.000000,0.000000) [0.000000|15.000000] "" ICAS1_Gateway
 SG_ AB_MKB_Safing  : 63|1@1+ (1.000000,0.000000) [0.000000|1.000000] "" ICAS1_Gateway

BO_ 1349 Airbag_04: 8 Airbag
 SG_ AB_Gurtwarn_Reihe4_FA  : 14|2@1+ (1.000000,0.000000) [0.000000|3.000000] "" ICAS1_Gateway ICAS1_KommunikationsServer
 SG_ AB_Gurtwarn_Reihe4_BF  : 16|2@1+ (1.000000,0.000000) [0.000000|3.000000] "" ICAS1_Gateway ICAS1_KommunikationsServer
 SG_ AB_Gurtwarn_Reihe4_MI  : 18|2@1+ (1.000000,0.000000) [0.000000|3.000000] "" ICAS1_Gateway ICAS1_KommunikationsServer
 SG_ AB_Gurtwarn_Reihe2_FA  : 20|2@1+ (1.000000,0.000000) [0.000000|3.000000] "" ICAS1_Gateway ICAS1_KommunikationsServer
 SG_ AB_Gurtwarn_Reihe2_BF  : 22|2@1+ (1.000000,0.000000) [0.000000|3.000000] "" ICAS1_Gateway ICAS1_KommunikationsServer
 SG_ AbstWarn_MV_FAS_Fkt_Status  : 24|2@1+ (1.000000,0.000000) [0.000000|3.000000] "" ICAS1_Gateway
 SG_ WarnBrems_Charisma_Status  : 26|2@1+ (1.000000,0.000000) [0.000000|3.000000] "" ICAS1_Gateway
 SG_ WarnBrems_Charisma_FahrPr  : 28|4@1+ (1.000000,0.000000) [0.000000|15.000000] "" ICAS1_Gateway
 SG_ AB_Gurtwarn_Reihe2_MI  : 32|2@1+ (1.000000,0.000000) [0.000000|3.000000] "" ICAS1_Gateway ICAS1_KommunikationsServer
 SG_ AB_Gurtwarn_Reihe3_FA  : 34|2@1+ (1.000000,0.000000) [0.000000|3.000000] "" ICAS1_Gateway ICAS1_KommunikationsServer
 SG_ AB_Gurtwarn_Reihe3_MI  : 36|2@1+ (1.000000,0.000000) [0.000000|3.000000] "" ICAS1_Gateway ICAS1_KommunikationsServer
 SG_ AB_Gurtwarn_Reihe3_BF  : 38|2@1+ (1.000000,0.000000) [0.000000|3.000000] "" ICAS1_Gateway ICAS1_KommunikationsServer
 SG_ LGI_FAS_Fkt_Status  : 40|2@1+ (1.000000,0.000000) [0.000000|3.000000] "" ICAS1_Gateway
 SG_ PreCrash_FAS_Fkt_Status  : 42|3@1+ (1.000000,0.000000) [0.000000|7.000000] "" ICAS1_Gateway
 SG_ AB_SBR_hinten_verbau  : 48|2@1+ (1.000000,0.000000) [0.000000|3.000000] "" ICAS1_Gateway ICAS1_KommunikationsServer
 SG_ AWV_Einstellung_System_ASG  : 51|1@1+ (1.000000,0.000000) [0.000000|1.000000] "" ICAS1_Gateway
 SG_ AWV_Einstellung_Warnung_ASG  : 52|3@1+ (1.000000,0.000000) [0.000000|7.000000] "" ICAS1_Gateway
 SG_ SC_PreSense_Modus_Warnung_NV  : 55|3@1+ (1.000000,0.000000) [0.000000|7.000000] "" ICAS1_Gateway
 SG_ SC_PreSense_Modus_Warnung_MV  : 58|3@1+ (1.000000,0.000000) [0.000000|7.000000] "" ICAS1_Gateway
 SG_ SC_PreSense_Modus_System_MV  : 61|1@1+ (1.000000,0.000000) [0.000000|1.000000] "" ICAS1_Gateway
 SG_ SC_PreSense_Modus_System_NV  : 62|1@1+ (1.000000,0.000000) [0.000000|1.000000] "" ICAS1_Gateway
 SG_ SC_PreSense_Modus_System_KAS  : 63|1@1+ (1.000000,0.000000) [0.000000|1.000000] "" ICAS1_Gateway

BO_ 2527679722 Airbag_06: 8 Airbag
 SG_ AB_Gurtschloss_Reihe4_FA  : 12|2@1+ (1.000000,0.000000) [0.000000|3.000000] "" ICAS1_Gateway ICAS1_KommunikationsServer
 SG_ AB_Gurtschloss_Reihe4_BF  : 14|2@1+ (1.000000,0.000000) [0.000000|3.000000] "" ICAS1_Gateway ICAS1_KommunikationsServer
 SG_ AB_Gurtschloss_Reihe4_MI  : 16|2@1+ (1.000000,0.000000) [0.000000|3.000000] "" ICAS1_Gateway ICAS1_KommunikationsServer

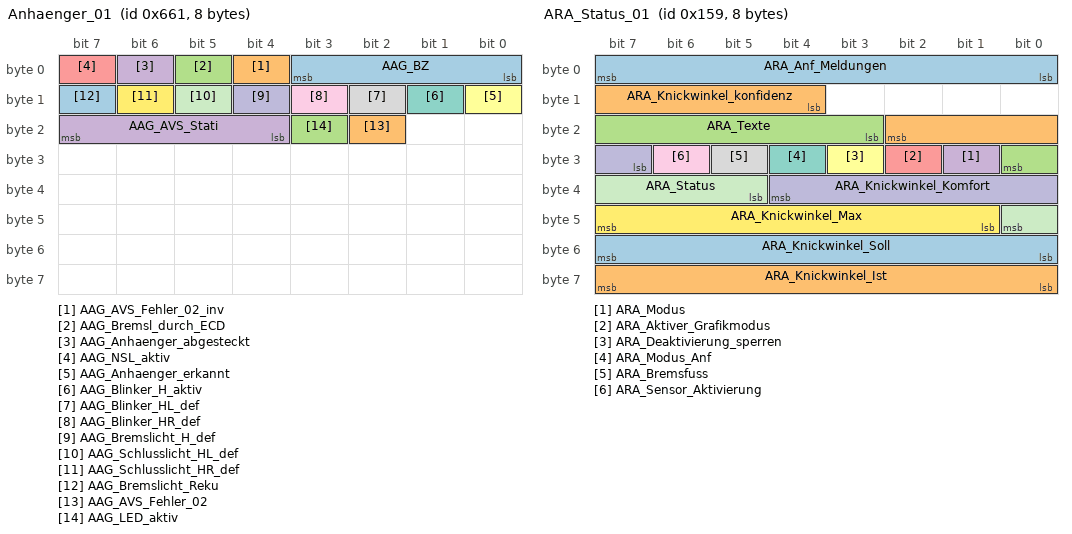
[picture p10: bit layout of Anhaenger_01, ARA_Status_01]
BO_ 1633 Anhaenger_01: 8 ICAS1_Gateway
 SG_ AAG_BZ  : 0|4@1+ (1.000000,0.000000) [0.000000|15.000000] "" Vector__XXX
 SG_ AAG_AVS_Fehler_02_inv  : 4|1@1+ (1.000000,0.000000) [0.000000|1.000000] "" Vector__XXX
 SG_ AAG_Bremsl_durch_ECD  : 5|1@1+ (1.000000,0.000000) [0.000000|1.000000] "" Motor_BEV
 SG_ AAG_Anhaenger_abgesteckt  : 6|1@1+ (1.000000,0.000000) [0.000000|1.000000] "" Motor_BEV
 SG_ AAG_NSL_aktiv  : 7|1@1+ (1.000000,0.000000) [0.000000|1.000000] "" Vector__XXX
 SG_ AAG_Anhaenger_erkannt  : 8|1@1+ (1.000000,0.000000) [0.000000|1.000000] "" Motor_BEV
 SG_ AAG_Blinker_H_aktiv  : 9|1@1+ (1.000000,0.000000) [0.000000|1.000000] "" Vector__XXX
 SG_ AAG_Blinker_HL_def  : 10|1@1+ (1.000000,0.000000) [0.000000|1.000000] "" Vector__XXX
 SG_ AAG_Blinker_HR_def  : 11|1@1+ (1.000000,0.000000) [0.000000|1.000000] "" Vector__XXX
 SG_ AAG_Bremslicht_H_def  : 12|1@1+ (1.000000,0.000000) [0.000000|1.000000] "" Motor_BEV
 SG_ AAG_Schlusslicht_HL_def  : 13|1@1+ (1.000000,0.000000) [0.000000|1.000000] "" Vector__XXX
 SG_ AAG_Schlusslicht_HR_def  : 14|1@1+ (1.000000,0.000000) [0.000000|1.000000] "" Vector__XXX
 SG_ AAG_Bremslicht_Reku  : 15|1@1+ (1.000000,0.000000) [0.000000|1.000000] "" Vector__XXX
 SG_ AAG_AVS_Fehler_02  : 18|1@1+ (1.000000,0.000000) [0.000000|1.000000] "" Vector__XXX
 SG_ AAG_LED_aktiv  : 19|1@1+ (1.000000,0.000000) [0.000000|1.000000] "" Vector__XXX
 SG_ AAG_AVS_Stati  : 20|4@1+ (1.000000,0.000000) [0.000000|15.000000] "" Vector__XXX

BO_ 345 ARA_Status_01: 8 ICAS1_Gateway
 SG_ ARA_Anf_Meldungen  : 0|8@1+ (1.000000,0.000000) [0.000000|255.000000] "" Vector__XXX
 SG_ ARA_Knickwinkel_konfidenz  : 12|7@1+ (1.000000,0.000000) [0.000000|120.000000] "Unit_DegreOfArc" Vector__XXX
 SG_ ARA_Texte  : 19|6@1+ (1.000000,0.000000) [0.000000|63.000000] "" Vector__XXX
 SG_ ARA_Modus  : 25|1@1+ (1.000000,0.000000) [0.000000|1.000000] "" Vector__XXX
 SG_ ARA_Aktiver_Grafikmodus  : 26|1@1+ (1.000000,0.000000) [0.000000|1.000000] "" Vector__XXX
 SG_ ARA_Deaktivierung_sperren  : 27|1@1+ (1.000000,0.000000) [0.000000|1.000000] "" Vector__XXX
 SG_ ARA_Modus_Anf  : 28|1@1+ (1.000000,0.000000) [0.000000|1.000000] "" Vector__XXX
 SG_ ARA_Bremsfuss  : 29|1@1+ (1.000000,0.000000) [0.000000|1.000000] "" Vector__XXX
 SG_ ARA_Sensor_Aktivierung  : 30|1@1+ (1.000000,0.000000) [0.000000|1.000000] "" Vector__XXX
 SG_ ARA_Knickwinkel_Komfort  : 31|6@1+ (1.000000,0.000000) [0.000000|60.000000] "Unit_DegreOfArc" Vector__XXX
 SG_ ARA_Status  : 37|4@1+ (1.000000,0.000000) [0.000000|15.000000] "" Motor_BEV
 SG_ ARA_Knickwinkel_Max  : 41|7@1+ (1.000000,0.000000) [0.000000|120.000000] "Unit_DegreOfArc" Vector__XXX
 SG_ ARA_Knickwinkel_Soll  : 48|8@1+ (1.000000,-125.000000) [-125.000000|126.000000] "Unit_DegreOfArc" Vector__XXX
 SG_ ARA_Knickwinkel_Ist  : 56|8@1+ (1.000000,-125.000000) [-125.000000|126.000000] "Unit_DegreOfArc" Vector__XXX

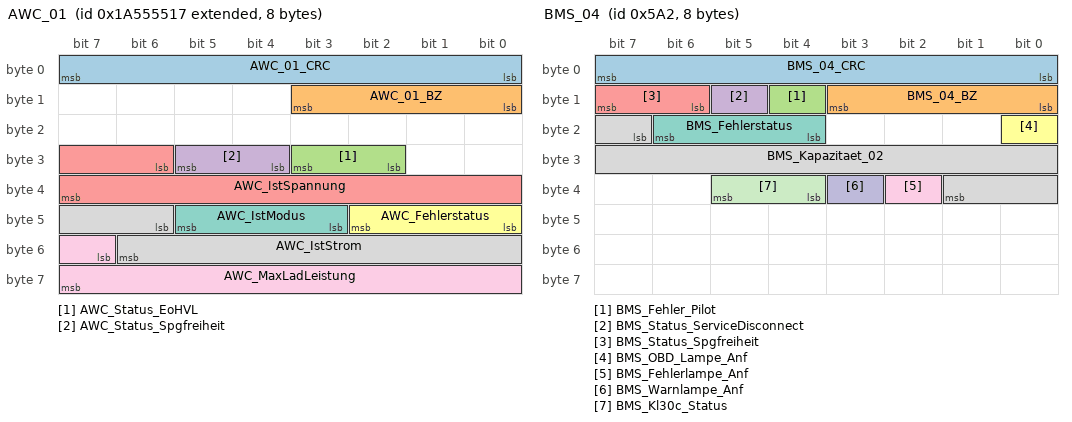
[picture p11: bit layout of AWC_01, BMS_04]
BO_ 2589283607 AWC_01: 8 ICAS1_Gateway
 SG_ AWC_01_CRC  : 0|8@1+ (1.000000,0.000000) [0.000000|255.000000] "" Vector__XXX
 SG_ AWC_01_BZ  : 8|4@1+ (1.000000,0.000000) [0.000000|15.000000] "" Vector__XXX
 SG_ AWC_Status_EoHVL  : 26|2@1+ (1.000000,0.000000) [0.000000|3.000000] "" Motor_BEV
 SG_ AWC_Status_Spgfreiheit  : 28|2@1+ (1.000000,0.000000) [0.000000|3.000000] "" Vector__XXX
 SG_ AWC_IstSpannung  : 30|10@1+ (1.000000,0.000000) [0.000000|1021.000000] "Unit_Volt" Vector__XXX
 SG_ AWC_Fehlerstatus  : 40|3@1+ (1.000000,0.000000) [0.000000|7.000000] "" Vector__XXX
 SG_ AWC_IstModus  : 43|3@1+ (1.000000,0.000000) [0.000000|7.000000] "" Vector__XXX
 SG_ AWC_IstStrom  : 46|9@1+ (0.100000,0.000000) [0.000000|50.900000] "Unit_Amper" Vector__XXX
 SG_ AWC_MaxLadLeistung  : 55|9@1+ (25.000000,0.000000) [0.000000|12725.000000] "Unit_Watt" Vector__XXX

BO_ 219 AWV_03: 48 ICAS1_Gateway
 SG_ AWV_03_CRC  : 0|8@1+ (1.000000,0.000000) [0.000000|255.000000] "" Airbag
 SG_ AWV_03_BZ  : 8|4@1+ (1.000000,0.000000) [0.000000|15.000000] "" Airbag
 SG_ PCF_Freigabe  : 12|1@1+ (1.000000,0.000000) [0.000000|1.000000] "" Airbag
 SG_ SDF_PSF_Objektstatus  : 13|3@1+ (1.000000,0.000000) [0.000000|7.000000] "" Airbag
 SG_ SDF_PSF_CU_Status  : 16|1@1+ (1.000000,0.000000) [0.000000|1.000000] "" Airbag
 SG_ SDF_PSF_CW  : 17|7@1+ (1.000000,0.000000) [0.000000|100.000000] "" Airbag
 SG_ SDF_PSF_Fahrer_aktiv  : 24|1@1+ (1.000000,0.000000) [0.000000|1.000000] "" Airbag
 SG_ SDF_PSF_Guete  : 25|2@1+ (1.000000,0.000000) [0.000000|3.000000] "" Airbag
 SG_ SDF_PSF_Kollisionsueberdeckung  : 27|5@1+ (0.100000,0.000000) [0.100000|2.800000] "Unit_Meter" Airbag
 SG_ SDF_PSF_Time_To_Collision  : 32|8@1+ (0.010000,0.000000) [0.000000|2.500000] "Unit_Secon" Vector__XXX
 SG_ SDF_PSF_v_rel  : 40|8@1+ (0.400000,0.000000) [0.400000|101.200000] "Unit_MeterPerSecon" Airbag
 SG_ AWV_Eingriff_Sendeart  : 64|1@1+ (1.000000,0.000000) [0.000000|1.000000] "" Airbag
 SG_ AWV_Verz_Freigabe  : 65|1@1+ (1.000000,0.000000) [0.000000|1.000000] "" Airbag
 SG_ AWV_Verz_Anf  : 66|10@1+ (0.024000,-20.016000) [-20.016000|4.512000] "Unit_MeterPerSeconSquar" Airbag
 SG_ AWV_Anf_Prefill  : 76|1@1+ (1.000000,0.000000) [0.000000|1.000000] "" Airbag
 SG_ AWV_Ruckprofil  : 77|3@1+ (1.000000,0.000000) [0.000000|7.000000] "" Vector__XXX
 SG_ AWV_Time_to_collision  : 80|8@1+ (0.010000,0.000000) [0.000000|2.500000] "Unit_Secon" Airbag
 SG_ AWV_HBA_Param  : 88|2@1+ (1.000000,0.000000) [0.000000|3.000000] "" Vector__XXX
 SG_ AWV_Verz_Anf_ASIL  : 90|3@1+ (1.000000,0.000000) [0.000000|7.000000] "" Vector__XXX
 SG_ AWV_Time_to_brake  : 93|7@1+ (10.000000,0.000000) [0.000000|1240.000000] "Unit_MilliSecon" Vector__XXX
 SG_ AWV_Zielobjekttyp  : 100|4@1+ (1.000000,0.000000) [0.000000|15.000000] "" Airbag
 SG_ AWV_QFK_KruemmSoll  : 104|15@1+ (0.000007,0.000000) [0.000000|0.219539] "Unit_MeterInver" Vector__XXX
 SG_ AWV_QFK_KruemmSoll_VZ  : 119|1@1+ (1.000000,0.000000) [0.000000|1.000000] "" Vector__XXX
 SG_ AWV_QFK_Spuerb  : 120|8@1+ (0.400000,0.000000) [0.000000|100.000000] "Unit_PerCent" Vector__XXX
 SG_ AWV_QFK_AnfStat  : 128|4@1+ (1.000000,0.000000) [0.000000|15.000000] "" Airbag
 SG_ AWV_QFK_Signal1  : 132|10@1+ (1.000000,0.000000) [0.000000|1023.000000] "" Vector__XXX
 SG_ AWV_QFK_Art1  : 142|3@1+ (1.000000,0.000000) [0.000000|7.000000] "" Vector__XXX
 SG_ AWV_QFK_Art2  : 145|3@1+ (1.000000,0.000000) [0.000000|7.000000] "" Vector__XXX
 SG_ AWV_QFK_Signal2  : 148|10@1+ (1.000000,0.000000) [0.000000|1023.000000] "" Vector__XXX

BO_ 2536767264 BAP_Debug_Cmd: 8 BAP_Tester
 SG_ BAP_Debug_Cmd  : 0|16@1+ (1.000000,0.000000) [0.000000|65535.000000] "" Motor_BEV

BO_ 2536767280 BAP_Debug_Data: 8 Motor_BEV
 SG_ BAP_Debug_Data  : 0|64@1+ (1.000000,0.000000) [0.000000|18446744073709551616.000000] "" BAP_Tester

BO_ 2536717313 BAP_EfficiencyAssist_ASG_02: 8 ICAS1_Gateway
 SG_ BAP_EfficAssist_ASG_02_Header  : 0|64@1+ (1.000000,0.000000) [0.000000|18446744073709551616.000000] "" Motor_BEV

BO_ 2536717314 BAP_EfficiencyAssist_ASG_03: 8 ICAS1_Gateway
 SG_ BAP_EfficAssist_ASG_03_Header  : 0|8@1+ (1.000000,0.000000) [0.000000|255.000000] "" Motor_BEV

BO_ 2536717328 BAP_EfficiencyAssist_FSG_01: 8 Motor_BEV
 SG_ BAP_EfficAssist_FSG_01_Header  : 0|8@1+ (1.000000,0.000000) [0.000000|255.000000] "" ICAS1_Gateway

BO_ 2536709120 BAP_Hybrid_ASG_01: 8 ICAS1_Gateway
 SG_ BAP_Hybrid_ASG_01_Header  : 0|8@1+ (1.000000,0.000000) [0.000000|255.000000] "" Motor_BEV

BO_ 2536709136 BAP_Hybrid_FSG_01: 8 Motor_BEV
 SG_ BAP_Hybrid_FSG_01_Header  : 0|8@1+ (1.000000,0.000000) [0.000000|255.000000] "" ICAS1_Gateway

BO_ 869 BEM_05: 8 ICAS1_Gateway
 SG_ BEM_UBDM  : 0|8@1+ (0.050000,5.000000) [5.050000|17.700000] "Unit_Volt" Vector__XXX
 SG_ NVEM_Ladefreigabe  : 8|2@1+ (1.000000,0.000000) [0.000000|3.000000] "" Vector__XXX
 SG_ NVEM_FMAus_Info  : 10|2@1+ (1.000000,0.000000) [0.000000|3.000000] "" Vector__XXX
 SG_ NVEM_PTC_Sollstufe  : 12|2@1+ (1.000000,0.000000) [0.000000|3.000000] "" Vector__XXX
 SG_ NVEM_P_Generator_Status  : 15|1@1+ (1.000000,0.000000) [0.000000|1.000000] "" Vector__XXX
 SG_ BEM_P_Generator  : 16|8@1+ (50.000000,0.000000) [0.000000|12700.000000] "Unit_Watt" Vector__XXX
 SG_ BEM_n_LLA  : 24|2@1+ (1.000000,0.000000) [0.000000|3.000000] "" Vector__XXX
 SG_ BEM_01_Abschaltstufen  : 26|3@1+ (1.000000,0.000000) [0.000000|7.000000] "" Vector__XXX
 SG_ BEM_Anf_KL  : 29|1@1+ (1.000000,0.000000) [0.000000|1.000000] "" Vector__XXX
 SG_ BEM_StartStopp_Info  : 30|2@1+ (1.000000,0.000000) [0.000000|3.000000] "" Vector__XXX
 SG_ BEM_DFM  : 32|5@1+ (3.225000,0.025000) [0.025000|100.000000] "" Vector__XXX
 SG_ BEM_EMLIN_ungueltig  : 37|1@1+ (1.000000,0.000000) [0.000000|1.000000] "" Vector__XXX
 SG_ BEM_Batt_Ab  : 38|1@1+ (1.000000,0.000000) [0.000000|1.000000] "" Motor_BEV
 SG_ NVEM_FMAus_I_Verbrauch  : 39|5@1+ (5.000000,0.000000) [0.000000|145.000000] "Unit_Amper" Vector__XXX
 SG_ NVEM_Freilauf_Info  : 44|2@1+ (1.000000,0.000000) [0.000000|3.000000] "" Vector__XXX
 SG_ BEM_NV_NachladAnf  : 46|2@1+ (1.000000,0.000000) [0.000000|3.000000] "" Vector__XXX
 SG_ BEM_Segel_Info  : 48|2@1+ (1.000000,0.000000) [0.000000|3.000000] "" Vector__XXX
 SG_ BEM_HYB_DC_uSollLV  : 50|6@1+ (0.100000,10.600000) [10.600000|16.000000] "Unit_Volt" Vector__XXX
 SG_ BEM_HYB_DC_uMinLV  : 56|8@1+ (0.100000,0.000000) [0.000000|25.300000] "Unit_Volt" Vector__XXX

BO_ 1442 BMS_04: 8 ICAS1_Gateway
 SG_ BMS_04_CRC  : 0|8@1+ (1.000000,0.000000) [0.000000|255.000000] "" Vector__XXX
 SG_ BMS_04_BZ  : 8|4@1+ (1.000000,0.000000) [0.000000|15.000000] "" Vector__XXX
 SG_ BMS_Fehler_Pilot  : 12|1@1+ (1.000000,0.000000) [0.000000|1.000000] "" Vector__XXX
 SG_ BMS_Status_ServiceDisconnect  : 13|1@1+ (1.000000,0.000000) [0.000000|1.000000] "" Vector__XXX
 SG_ BMS_Status_Spgfreiheit  : 14|2@1+ (1.000000,0.000000) [0.000000|3.000000] "" Motor_BEV
 SG_ BMS_OBD_Lampe_Anf  : 16|1@1+ (1.000000,0.000000) [0.000000|1.000000] "" Motor_BEV
 SG_ BMS_Fehlerstatus  : 20|3@1+ (1.000000,0.000000) [0.000000|7.000000] "" Vector__XXX
 SG_ BMS_Kapazitaet_02  : 23|11@1+ (0.200000,0.000000) [0.000000|409.200000] "Unit_AmperHour" Vector__XXX
 SG_ BMS_Fehlerlampe_Anf  : 34|1@1+ (1.000000,0.000000) [0.000000|1.000000] "" Motor_BEV
 SG_ BMS_Warnlampe_Anf  : 35|1@1+ (1.000000,0.000000) [0.000000|1.000000] "" Motor_BEV
 SG_ BMS_Kl30c_Status  : 36|2@1+ (1.000000,0.000000) [0.000000|3.000000] "" Motor_BEV

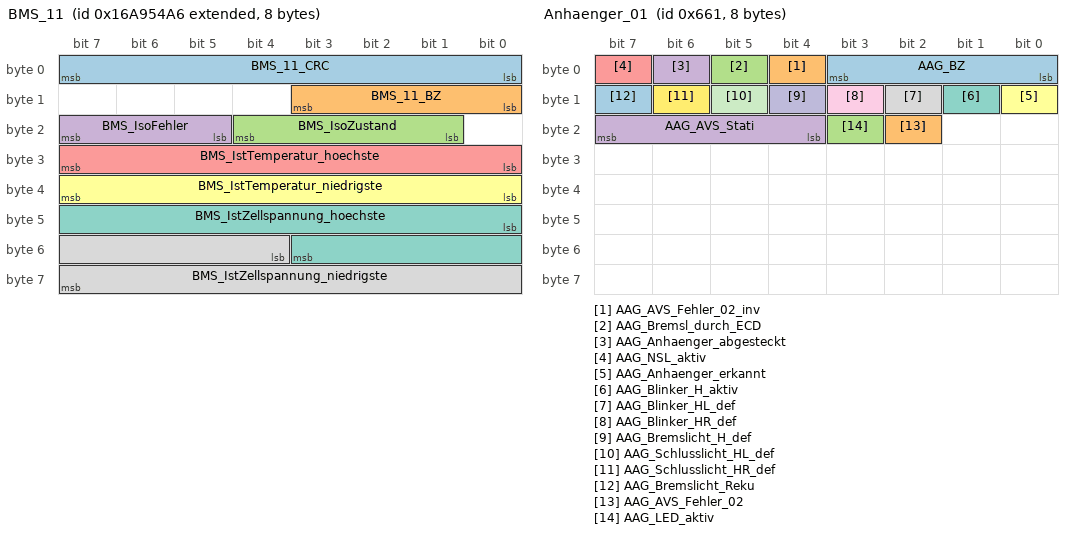
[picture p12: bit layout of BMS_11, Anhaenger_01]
BO_ 2527679654 BMS_11: 8 ICAS1_Gateway
 SG_ BMS_11_CRC  : 0|8@1+ (1.000000,0.000000) [0.000000|255.000000] "" Motor_BEV
 SG_ BMS_11_BZ  : 8|4@1+ (1.000000,0.000000) [0.000000|15.000000] "" Motor_BEV
 SG_ BMS_IsoZustand  : 17|4@1+ (1.000000,0.000000) [0.000000|15.000000] "" Motor_BEV
 SG_ BMS_IsoFehler  : 21|3@1+ (1.000000,0.000000) [0.000000|7.000000] "" Motor_BEV
 SG_ BMS_IstTemperatur_hoechste  : 24|8@1+ (0.500000,-40.000000) [-40.000000|86.000000] "Unit_DegreCelsi" Vector__XXX
 SG_ BMS_IstTemperatur_niedrigste  : 32|8@1+ (0.500000,-40.000000) [-40.000000|86.000000] "Unit_DegreCelsi" Vector__XXX
 SG_ BMS_IstZellspannung_hoechste  : 40|12@1+ (1.000000,1000.000000) [1000.000000|5091.000000] "Unit_MilliVolt" Vector__XXX
 SG_ BMS_IstZellspannung_niedrigste  : 52|12@1+ (1.000000,1000.000000) [1000.000000|5091.000000] "Unit_MilliVolt" Vector__XXX

BU_:  Airbag BAP_Tester ICAS1_Gateway ICAS1_KommunikationsServer LE1 LE2 Motor_BEV Schaltbetaetigung

BO_ 333 ACC_18: 32 ICAS1_Gateway
 SG_ ACC_18_CRC  : 0|8@1+ (1.000000,0.000000) [0.000000|255.000000] "" Motor_BEV
 SG_ ACC_18_BZ  : 8|4@1+ (1.000000,0.000000) [0.000000|15.000000] "" Motor_BEV
 SG_ ACC_limitierte_Anfahrdyn  : 12|1@0- (1.000000,0.000000) [0.000000|1.000000] "" Motor_BEV
 SG_ ACC_nachtr_Stopp_Anf  : 13|1@1+ (1.000000,0.000000) [0.000000|1.000000] "" Vector__XXX
 SG_ ACC_DynErhoehung  : 14|1@1+ (1.000000,0.000000) [0.000000|1.000000] "" Motor_BEV
 SG_ ACC_Freilaufstrategie_TSK  : 15|1@1+ (1.000000,0.000000) [0.000000|1.000000] "" Motor_BEV
 SG_ ACC_zul_Regelabw_unten  : 16|6@1+ (0.024000,0.000000) [0.000000|1.512000] "Unit_MeterPerSeconSquar" Motor_BEV
 SG_ ACC_StartStopp_Info  : 22|2@1+ (1.000000,0.000000) [0.000000|3.000000] "" Vector__XXX
 SG_ ACC_Sollbeschleunigung_02  : 24|11@1+ (0.005000,-7.220000) [-7.220000|3.005000] "Unit_MeterPerSeconSquar" Motor_BEV
 SG_ ACC_zul_Regelabw_oben  : 35|5@1+ (0.062500,0.000000) [0.000000|1.937500] "Unit_MeterPerSeconSquar" Motor_BEV
 SG_ ACC_neg_Sollbeschl_Grad_02  : 40|8@1+ (0.050000,0.000000) [0.000000|12.750000] "Unit_MeterPerCubicSecon" Motor_BEV
 SG_ ACC_pos_Sollbeschl_Grad_02  : 48|8@1+ (0.050000,0.000000) [0.000000|12.750000] "Unit_MeterPerCubicSecon" Motor_BEV
 SG_ ACC_Anfahren  : 56|1@1+ (1.000000,0.000000) [0.000000|1.000000] "" Motor_BEV
 SG_ ACC_Anhalten  : 57|1@1+ (1.000000,0.000000) [0.000000|1.000000] "" Motor_BEV
 SG_ ACC_Typ  : 58|2@1+ (1.000000,0.000000) [0.000000|3.000000] "" Motor_BEV
 SG_ ACC_Status_ACC  : 60|3@1+ (1.000000,0.000000) [0.000000|7.000000] "" Motor_BEV
 SG_ ACC_Minimale_Bremsung  : 63|1@1+ (1.000000,0.000000) [0.000000|1.000000] "" Motor_BEV
 SG_ ACC_Anhalteweg  : 64|11@1+ (0.010000,0.000000) [0.000000|20.450000] "Unit_Meter" Vector__XXX
 SG_ ACC_Boost  : 75|1@1+ (1.000000,0.000000) [0.000000|1.000000] "" Vector__XXX
 SG_ ACC_Freilauf_Anf  : 76|1@1+ (1.000000,0.000000) [0.000000|1.000000] "" Vector__XXX
 SG_ ACC_Anforderung_HMS  : 77|3@1+ (1.000000,0.000000) [0.000000|7.000000] "" Vector__XXX
 SG_ ACC_Folgebeschl  : 80|8@1+ (0.030000,-4.600000) [-4.600000|2.990000] "Unit_MeterPerSeconSquar" Motor_BEV
 SG_ ACC_Freilauf_Info  : 88|2@1+ (1.000000,0.000000) [0.000000|3.000000] "" Motor_BEV
 SG_ ACC_Tempolimitassistent_Ein  : 90|1@1+ (1.000000,0.000000) [0.000000|1.000000] "" Vector__XXX
 SG_ ACC_FoD_Status  : 91|2@1+ (1.000000,0.000000) [0.000000|3.000000] "" Motor_BEV
 SG_ vESC_Verz_Anf  : 232|4@1+ (0.500000,0.000000) [0.000000|3.500000] "Unit_MeterPerSeconSquar" Vector__XXX
 SG_ RDR_v_ueber_Grund  : 236|12@1+ (0.100000,0.000000) [0.000000|409.000000] "Unit_KiloMeterPerHour" Vector__XXX
 SG_ RDR_v_ueber_Grund_Genauigkeit  : 248|6@1+ (0.100000,0.000000) [0.000000|6.000000] "Unit_KiloMeterPerHour" Vector__XXX
 SG_ RDR_v_ueber_Grund_Fahrtrichtung  : 254|2@1+ (1.000000,0.000000) [0.000000|3.000000] "" Vector__XXX

BO_ 2527679682 ACC_ASM_01: 8 ICAS1_Gateway
 SG_ ACC_ASM_Ereignis  : 0|8@1+ (1.000000,0.000000) [1.000000|254.000000] "" Airbag
 SG_ ACC_ASM_Zeitstempel  : 8|8@1+ (0.080000,0.000000) [0.000000|20.320000] "Unit_Secon" Airbag
 SG_ ACC_ASM_Data_1  : 16|8@1+ (1.000000,0.000000) [0.000000|255.000000] "" Airbag
 SG_ ACC_ASM_Data_2  : 24|8@1+ (1.000000,0.000000) [0.000000|255.000000] "" Airbag
 SG_ ACC_ASM_Data_3  : 32|8@1+ (1.000000,0.000000) [0.000000|255.000000] "" Airbag
 SG_ ACC_ASM_Data_4  : 40|8@1+ (1.000000,0.000000) [0.000000|255.000000] "" Airbag
 SG_ ACC_ASM_Data_5  : 48|8@1+ (1.000000,0.000000) [0.000000|255.000000] "" Airbag
 SG_ ACC_ASM_Data_6  : 56|8@1+ (1.000000,0.000000) [0.000000|255.000000] "" Airbag

BO_ 64 Airbag_01: 8 Airbag
 SG_ Airbag_01_CRC  : 0|8@1+ (1.000000,0.000000) [0.000000|255.000000] "" ICAS1_Gateway LE1 LE2 Motor_BEV
 SG_ Airbag_01_BZ  : 8|4@1+ (1.000000,0.000000) [0.000000|15.000000] "" ICAS1_Gateway LE1 LE2 Motor_BEV
 SG_ AB_RGS_Anst  : 12|4@1+ (1.000000,0.000000) [0.000000|15.000000] "" ICAS1_Gateway ICAS1_KommunikationsServer
 SG_ AB_Front_Crash  : 16|1@1+ (1.000000,0.000000) [0.000000|1.000000] "" ICAS1_Gateway
 SG_ AB_Heck_Crash  : 17|1@1+ (1.000000,0.000000) [0.000000|1.000000] "" ICAS1_Gateway
 SG_ AB_SF_Crash  : 18|1@1+ (1.000000,0.000000) [0.000000|1.000000] "" ICAS1_Gateway
 SG_ AB_SB_Crash  : 19|1@1+ (1.000000,0.000000) [0.000000|1.000000] "" ICAS1_Gateway
 SG_ AB_Rollover_Crash  : 20|1@1+ (1.000000,0.000000) [0.000000|1.000000] "" ICAS1_Gateway
 SG_ AB_Crash_Int  : 21|3@1+ (1.000000,0.000000) [0.000000|7.000000] "" ICAS1_Gateway ICAS1_KommunikationsServer Motor_BEV
 SG_ AB_Lampe  : 24|1@1+ (1.000000,0.000000) [0.000000|1.000000] "" ICAS1_Gateway ICAS1_KommunikationsServer
 SG_ AB_Deaktiviert  : 25|1@1+ (1.000000,0.000000) [0.000000|1.000000] "" ICAS1_Gateway
 SG_ AB_VB_deaktiviert  : 26|1@1+ (1.000000,0.000000) [0.000000|1.000000] "" ICAS1_Gateway
 SG_ AB_Systemfehler  : 27|1@1+ (1.000000,0.000000) [0.000000|1.000000] "" ICAS1_Gateway ICAS1_KommunikationsServer
 SG_ AB_Diagnose  : 28|1@1+ (1.000000,0.000000) [0.000000|1.000000] "" ICAS1_Gateway
 SG_ AB_Stellgliedtest  : 29|1@1+ (1.000000,0.000000) [0.000000|1.000000] "" ICAS1_Gateway
 SG_ AB_Erh_Auf_VB  : 30|2@1+ (1.000000,0.000000) [0.000000|3.000000] "" ICAS1_Gateway
 SG_ AB_Gurtwarn_VF  : 32|1@1+ (1.000000,0.000000) [0.000000|1.000000] "" ICAS1_Gateway ICAS1_KommunikationsServer
 SG_ AB_Gurtwarn_VB  : 33|1@1+ (1.000000,0.000000) [0.000000|1.000000] "" ICAS1_Gateway ICAS1_KommunikationsServer
 SG_ AB_Anzeige_Fussg  : 34|2@1+ (1.000000,0.000000) [0.000000|3.000000] "" ICAS1_Gateway
 SG_ AB_Texte_AKS  : 36|2@1+ (1.000000,0.000000) [0.000000|3.000000] "" ICAS1_Gateway
 SG_ AB_PAO_Leuchte_Anf  : 38|1@1+ (1.000000,0.000000) [0.000000|1.000000] "" ICAS1_Gateway
 SG_ AB_MKB_gueltig  : 39|1@1+ (1.000000,0.000000) [0.000000|1.000000] "" ICAS1_Gateway
 SG_ AB_MKB_Anforderung  : 40|1@1+ (1.000000,0.000000) [0.000000|1.000000] "" ICAS1_Gateway
 SG_ AB_Versorgungsspannung  : 41|1@1+ (1.000000,0.000000) [0.000000|1.000000] "" ICAS1_Gateway
 SG_ AB_Deaktivierung_HV  : 42|3@1+ (1.000000,0.000000) [0.000000|7.000000] "" ICAS1_Gateway ICAS1_KommunikationsServer LE1 LE2 Motor_BEV
 SG_ AB_EDR_Trigger  : 45|2@1+ (1.000000,0.000000) [0.000000|3.000000] "" ICAS1_Gateway
 SG_ AB_Belegung_VF  : 47|2@1+ (1.000000,0.000000) [0.000000|3.000000] "" ICAS1_Gateway
 SG_ AB_Gurtschloss_FA_ext  : 49|3@1+ (1.000000,0.000000) [0.000000|7.000000] "" ICAS1_Gateway
 SG_ AB_Belegung_VF_ext  : 52|3@1+ (1.000000,0.000000) [0.000000|7.000000] "" ICAS1_Gateway
 SG_ ASM_Masterzeit  : 56|8@1+ (0.080000,0.000000) [0.000000|20.320000] "Unit_Secon" ICAS1_Gateway

BO_ 1312 Airbag_02: 8 Airbag
 SG_ Airbag_02_CRC  : 0|8@1+ (1.000000,0.000000) [0.000000|255.000000] "" ICAS1_Gateway Motor_BEV
 SG_ Airbag_02_BZ  : 8|4@1+ (1.000000,0.000000) [0.000000|15.000000] "" ICAS1_Gateway Motor_BEV
 SG_ LoGeWa_Event_Kombiwarnung  : 12|4@1+ (1.000000,0.000000) [0.000000|15.000000] "" ICAS1_Gateway
 SG_ AB_Anforderung_eCall  : 16|1@1+ (1.000000,0.000000) [0.000000|1.000000] "" ICAS1_Gateway
 SG_ AB_Anprall_Seite_Beifahrer  : 17|1@1+ (1.000000,0.000000) [0.000000|1.000000] "" ICAS1_Gateway ICAS1_KommunikationsServer
 SG_ AB_Anprall_Rollover  : 18|1@1+ (1.000000,0.000000) [0.000000|1.000000] "" ICAS1_Gateway ICAS1_KommunikationsServer
 SG_ AB_Anprall_FGS  : 19|1@1+ (1.000000,0.000000) [0.000000|1.000000] "" ICAS1_Gateway ICAS1_KommunikationsServer
 SG_ AB_Anprall_Front_Beifahrer  : 20|1@1+ (1.000000,0.000000) [0.000000|1.000000] "" ICAS1_Gateway ICAS1_KommunikationsServer
 SG_ AB_Anprall_Front_Fahrer  : 21|1@1+ (1.000000,0.000000) [0.000000|1.000000] "" ICAS1_Gateway ICAS1_KommunikationsServer
 SG_ AB_Anprall_Heck_Beifahrer  : 22|1@1+ (1.000000,0.000000) [0.000000|1.000000] "" ICAS1_Gateway ICAS1_KommunikationsServer
 SG_ AB_Anprall_Heck_Fahrer  : 23|1@1+ (1.000000,0.000000) [0.000000|1.000000] "" ICAS1_Gateway ICAS1_KommunikationsServer
 SG_ AB_Wickelklappung_Reihe2_MI  : 24|2@1+ (1.000000,0.000000) [0.000000|3.000000] "" ICAS1_Gateway
 SG_ AB_Belegung_VB  : 26|2@1+ (1.000000,0.000000) [0.000000|3.000000] "" ICAS1_Gateway
 SG_ AB_Abschaltanf_SIH_BF  : 28|1@1+ (1.000000,0.000000) [0.000000|1.000000] "" ICAS1_Gateway
 SG_ AB_Anprall_Seite_Fahrer  : 29|1@1+ (1.000000,0.000000) [0.000000|1.000000] "" ICAS1_Gateway ICAS1_KommunikationsServer
 SG_ SC_PAO_Schriftzug_Anf  : 30|2@1+ (1.000000,0.000000) [0.000000|3.000000] "" ICAS1_Gateway
 SG_ SC_PAO_ON_Anf  : 32|2@1+ (1.000000,0.000000) [0.000000|3.000000] "" ICAS1_Gateway
 SG_ SC_PAO_OFF_Anf  : 34|2@1+ (1.000000,0.000000) [0.000000|3.000000] "" ICAS1_Gateway
 SG_ AB_Crashschwere  : 36|3@1+ (1.000000,0.000000) [0.000000|7.000000] "" ICAS1_Gateway ICAS1_KommunikationsServer
 SG_ AB_Anforderung_USM  : 39|1@1+ (1.000000,0.000000) [0.000000|1.000000] "" ICAS1_Gateway
 SG_ AB_Gurtschloss_FA  : 40|2@1+ (1.000000,0.000000) [0.000000|3.000000] "" ICAS1_Gateway ICAS1_KommunikationsServer Motor_BEV
 SG_ AB_Gurtschloss_BF  : 42|2@1+ (1.000000,0.000000) [0.000000|3.000000] "" ICAS1_Gateway ICAS1_KommunikationsServer
 SG_ AB_Gurtschloss_Reihe2_FA  : 44|2@1+ (1.000000,0.000000) [0.000000|3.000000] "" ICAS1_Gateway ICAS1_KommunikationsServer
 SG_ AB_Gurtschloss_Reihe2_MI  : 46|2@1+ (1.000000,0.000000) [0.000000|3.000000] "" ICAS1_Gateway ICAS1_KommunikationsServer
 SG_ AB_Gurtschloss_Reihe2_BF  : 48|2@1+ (1.000000,0.000000) [0.000000|3.000000] "" ICAS1_Gateway ICAS1_KommunikationsServer
 SG_ AB_Gurtschloss_Reihe3_FA  : 50|2@1+ (1.000000,0.000000) [0.000000|3.000000] "" ICAS1_Gateway ICAS1_KommunikationsServer
 SG_ AB_Gurtschloss_Reihe3_MI  : 52|2@1+ (1.000000,0.000000) [0.000000|3.000000] "" ICAS1_Gateway ICAS1_KommunikationsServer
 SG_ AB_Gurtschloss_Reihe3_BF  : 54|2@1+ (1.000000,0.000000) [0.000000|3.000000] "" ICAS1_Gateway ICAS1_KommunikationsServer
 SG_ AB_Sitzpos_Sens_FA  : 56|2@1+ (1.000000,0.000000) [0.000000|3.000000] "" ICAS1_Gateway
 SG_ AB_Sitzpos_Sens_BF  : 58|2@1+ (1.000000,0.000000) [0.000000|3.000000] "" ICAS1_Gateway
 SG_ AB_Wickelklappung_Reihe2_BF  : 60|2@1+ (1.000000,0.000000) [0.000000|3.000000] "" ICAS1_Gateway
 SG_ AB_Wickelklappung_Reihe2_FA  : 62|2@1+ (1.000000,0.000000) [0.000000|3.000000] "" ICAS1_Gateway

BO_ 65 Airbag_03: 8 Airbag
 SG_ Airbag_03_CRC  : 0|8@1+ (1.000000,0.000000) [0.000000|255.000000] "" ICAS1_Gateway
 SG_ Airbag_03_BZ  : 8|4@1+ (1.000000,0.000000) [0.000000|15.000000] "" ICAS1_Gateway
 SG_ AB_MKB_Safing  : 63|1@1+ (1.000000,0.000000) [0.000000|1.000000] "" ICAS1_Gateway

BO_ 1349 Airbag_04: 8 Airbag
 SG_ AB_Gurtwarn_Reihe4_FA  : 14|2@1+ (1.000000,0.000000) [0.000000|3.000000] "" ICAS1_Gateway ICAS1_KommunikationsServer
 SG_ AB_Gurtwarn_Reihe4_BF  : 16|2@1+ (1.000000,0.000000) [0.000000|3.000000] "" ICAS1_Gateway ICAS1_KommunikationsServer
 SG_ AB_Gurtwarn_Reihe4_MI  : 18|2@1+ (1.000000,0.000000) [0.000000|3.000000] "" ICAS1_Gateway ICAS1_KommunikationsServer
 SG_ AB_Gurtwarn_Reihe2_FA  : 20|2@1+ (1.000000,0.000000) [0.000000|3.000000] "" ICAS1_Gateway ICAS1_KommunikationsServer
 SG_ AB_Gurtwarn_Reihe2_BF  : 22|2@1+ (1.000000,0.000000) [0.000000|3.000000] "" ICAS1_Gateway ICAS1_KommunikationsServer
 SG_ AbstWarn_MV_FAS_Fkt_Status  : 24|2@1+ (1.000000,0.000000) [0.000000|3.000000] "" ICAS1_Gateway
 SG_ WarnBrems_Charisma_Status  : 26|2@1+ (1.000000,0.000000) [0.000000|3.000000] "" ICAS1_Gateway
 SG_ WarnBrems_Charisma_FahrPr  : 28|4@1+ (1.000000,0.000000) [0.000000|15.000000] "" ICAS1_Gateway
 SG_ AB_Gurtwarn_Reihe2_MI  : 32|2@1+ (1.000000,0.000000) [0.000000|3.000000] "" ICAS1_Gateway ICAS1_KommunikationsServer
 SG_ AB_Gurtwarn_Reihe3_FA  : 34|2@1+ (1.000000,0.000000) [0.000000|3.000000] "" ICAS1_Gateway ICAS1_KommunikationsServer
 SG_ AB_Gurtwarn_Reihe3_MI  : 36|2@1+ (1.000000,0.000000) [0.000000|3.000000] "" ICAS1_Gateway ICAS1_KommunikationsServer
 SG_ AB_Gurtwarn_Reihe3_BF  : 38|2@1+ (1.000000,0.000000) [0.000000|3.000000] "" ICAS1_Gateway ICAS1_KommunikationsServer
 SG_ LGI_FAS_Fkt_Status  : 40|2@1+ (1.000000,0.000000) [0.000000|3.000000] "" ICAS1_Gateway
 SG_ PreCrash_FAS_Fkt_Status  : 42|3@1+ (1.000000,0.000000) [0.000000|7.000000] "" ICAS1_Gateway
 SG_ AB_SBR_hinten_verbau  : 48|2@1+ (1.000000,0.000000) [0.000000|3.000000] "" ICAS1_Gateway ICAS1_KommunikationsServer
 SG_ AWV_Einstellung_System_ASG  : 51|1@1+ (1.000000,0.000000) [0.000000|1.000000] "" ICAS1_Gateway
 SG_ AWV_Einstellung_Warnung_ASG  : 52|3@1+ (1.000000,0.000000) [0.000000|7.000000] "" ICAS1_Gateway
 SG_ SC_PreSense_Modus_Warnung_NV  : 55|3@1+ (1.000000,0.000000) [0.000000|7.000000] "" ICAS1_Gateway
 SG_ SC_PreSense_Modus_Warnung_MV  : 58|3@1+ (1.000000,0.000000) [0.000000|7.000000] "" ICAS1_Gateway
 SG_ SC_PreSense_Modus_System_MV  : 61|1@1+ (1.000000,0.000000) [0.000000|1.000000] "" ICAS1_Gateway
 SG_ SC_PreSense_Modus_System_NV  : 62|1@1+ (1.000000,0.000000) [0.000000|1.000000] "" ICAS1_Gateway
 SG_ SC_PreSense_Modus_System_KAS  : 63|1@1+ (1.000000,0.000000) [0.000000|1.000000] "" ICAS1_Gateway

BO_ 2527679722 Airbag_06: 8 Airbag
 SG_ AB_Gurtschloss_Reihe4_FA  : 12|2@1+ (1.000000,0.000000) [0.000000|3.000000] "" ICAS1_Gateway ICAS1_KommunikationsServer
 SG_ AB_Gurtschloss_Reihe4_BF  : 14|2@1+ (1.000000,0.000000) [0.000000|3.000000] "" ICAS1_Gateway ICAS1_KommunikationsServer
 SG_ AB_Gurtschloss_Reihe4_MI  : 16|2@1+ (1.000000,0.000000) [0.000000|3.000000] "" ICAS1_Gateway ICAS1_KommunikationsServer

BO_ 1633 Anhaenger_01: 8 ICAS1_Gateway
 SG_ AAG_BZ  : 0|4@1+ (1.000000,0.000000) [0.000000|15.000000] "" Vector__XXX
 SG_ AAG_AVS_Fehler_02_inv  : 4|1@1+ (1.000000,0.000000) [0.000000|1.000000] "" Vector__XXX
 SG_ AAG_Bremsl_durch_ECD  : 5|1@1+ (1.000000,0.000000) [0.000000|1.000000] "" Motor_BEV
 SG_ AAG_Anhaenger_abgesteckt  : 6|1@1+ (1.000000,0.000000) [0.000000|1.000000] "" Motor_BEV
 SG_ AAG_NSL_aktiv  : 7|1@1+ (1.000000,0.000000) [0.000000|1.000000] "" Vector__XXX
 SG_ AAG_Anhaenger_erkannt  : 8|1@1+ (1.000000,0.000000) [0.000000|1.000000] "" Motor_BEV
 SG_ AAG_Blinker_H_aktiv  : 9|1@1+ (1.000000,0.000000) [0.000000|1.000000] "" Vector__XXX
 SG_ AAG_Blinker_HL_def  : 10|1@1+ (1.000000,0.000000) [0.000000|1.000000] "" Vector__XXX
 SG_ AAG_Blinker_HR_def  : 11|1@1+ (1.000000,0.000000) [0.000000|1.000000] "" Vector__XXX
 SG_ AAG_Bremslicht_H_def  : 12|1@1+ (1.000000,0.000000) [0.000000|1.000000] "" Motor_BEV
 SG_ AAG_Schlusslicht_HL_def  : 13|1@1+ (1.000000,0.000000) [0.000000|1.000000] "" Vector__XXX
 SG_ AAG_Schlusslicht_HR_def  : 14|1@1+ (1.000000,0.000000) [0.000000|1.000000] "" Vector__XXX
 SG_ AAG_Bremslicht_Reku  : 15|1@1+ (1.000000,0.000000) [0.000000|1.000000] "" Vector__XXX
 SG_ AAG_AVS_Fehler_02  : 18|1@1+ (1.000000,0.000000) [0.000000|1.000000] "" Vector__XXX
 SG_ AAG_LED_aktiv  : 19|1@1+ (1.000000,0.000000) [0.000000|1.000000] "" Vector__XXX
 SG_ AAG_AVS_Stati  : 20|4@1+ (1.000000,0.000000) [0.000000|15.000000] "" Vector__XXX

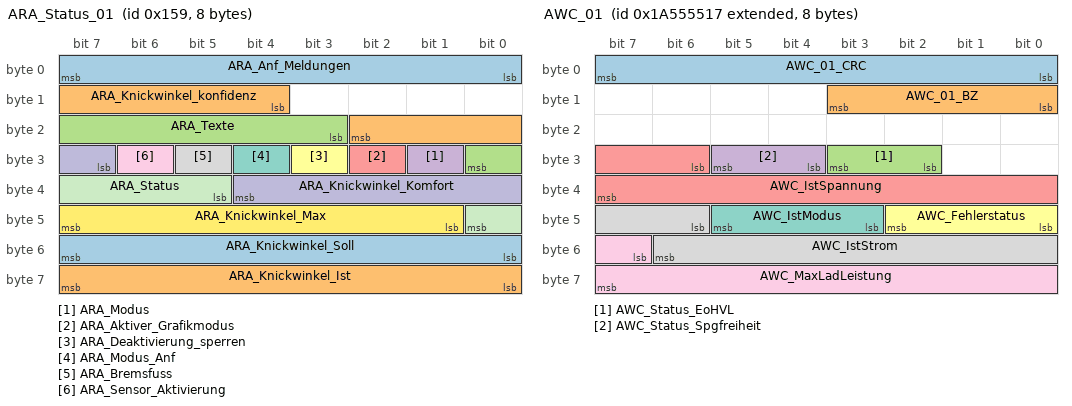
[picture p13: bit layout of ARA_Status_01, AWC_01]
BO_ 345 ARA_Status_01: 8 ICAS1_Gateway
 SG_ ARA_Anf_Meldungen  : 0|8@1+ (1.000000,0.000000) [0.000000|255.000000] "" Vector__XXX
 SG_ ARA_Knickwinkel_konfidenz  : 12|7@1+ (1.000000,0.000000) [0.000000|120.000000] "Unit_DegreOfArc" Vector__XXX
 SG_ ARA_Texte  : 19|6@1+ (1.000000,0.000000) [0.000000|63.000000] "" Vector__XXX
 SG_ ARA_Modus  : 25|1@1+ (1.000000,0.000000) [0.000000|1.000000] "" Vector__XXX
 SG_ ARA_Aktiver_Grafikmodus  : 26|1@1+ (1.000000,0.000000) [0.000000|1.000000] "" Vector__XXX
 SG_ ARA_Deaktivierung_sperren  : 27|1@1+ (1.000000,0.000000) [0.000000|1.000000] "" Vector__XXX
 SG_ ARA_Modus_Anf  : 28|1@1+ (1.000000,0.000000) [0.000000|1.000000] "" Vector__XXX
 SG_ ARA_Bremsfuss  : 29|1@1+ (1.000000,0.000000) [0.000000|1.000000] "" Vector__XXX
 SG_ ARA_Sensor_Aktivierung  : 30|1@1+ (1.000000,0.000000) [0.000000|1.000000] "" Vector__XXX
 SG_ ARA_Knickwinkel_Komfort  : 31|6@1+ (1.000000,0.000000) [0.000000|60.000000] "Unit_DegreOfArc" Vector__XXX
 SG_ ARA_Status  : 37|4@1+ (1.000000,0.000000) [0.000000|15.000000] "" Motor_BEV
 SG_ ARA_Knickwinkel_Max  : 41|7@1+ (1.000000,0.000000) [0.000000|120.000000] "Unit_DegreOfArc" Vector__XXX
 SG_ ARA_Knickwinkel_Soll  : 48|8@1+ (1.000000,-125.000000) [-125.000000|126.000000] "Unit_DegreOfArc" Vector__XXX
 SG_ ARA_Knickwinkel_Ist  : 56|8@1+ (1.000000,-125.000000) [-125.000000|126.000000] "Unit_DegreOfArc" Vector__XXX

BO_ 2589283607 AWC_01: 8 ICAS1_Gateway
 SG_ AWC_01_CRC  : 0|8@1+ (1.000000,0.000000) [0.000000|255.000000] "" Vector__XXX
 SG_ AWC_01_BZ  : 8|4@1+ (1.000000,0.000000) [0.000000|15.000000] "" Vector__XXX
 SG_ AWC_Status_EoHVL  : 26|2@1+ (1.000000,0.000000) [0.000000|3.000000] "" Motor_BEV
 SG_ AWC_Status_Spgfreiheit  : 28|2@1+ (1.000000,0.000000) [0.000000|3.000000] "" Vector__XXX
 SG_ AWC_IstSpannung  : 30|10@1+ (1.000000,0.000000) [0.000000|1021.000000] "Unit_Volt" Vector__XXX
 SG_ AWC_Fehlerstatus  : 40|3@1+ (1.000000,0.000000) [0.000000|7.000000] "" Vector__XXX
 SG_ AWC_IstModus  : 43|3@1+ (1.000000,0.000000) [0.000000|7.000000] "" Vector__XXX
 SG_ AWC_IstStrom  : 46|9@1+ (0.100000,0.000000) [0.000000|50.900000] "Unit_Amper" Vector__XXX
 SG_ AWC_MaxLadLeistung  : 55|9@1+ (25.000000,0.000000) [0.000000|12725.000000] "Unit_Watt" Vector__XXX

BO_ 219 AWV_03: 48 ICAS1_Gateway
 SG_ AWV_03_CRC  : 0|8@1+ (1.000000,0.000000) [0.000000|255.000000] "" Airbag
 SG_ AWV_03_BZ  : 8|4@1+ (1.000000,0.000000) [0.000000|15.000000] "" Airbag
 SG_ PCF_Freigabe  : 12|1@1+ (1.000000,0.000000) [0.000000|1.000000] "" Airbag
 SG_ SDF_PSF_Objektstatus  : 13|3@1+ (1.000000,0.000000) [0.000000|7.000000] "" Airbag
 SG_ SDF_PSF_CU_Status  : 16|1@1+ (1.000000,0.000000) [0.000000|1.000000] "" Airbag
 SG_ SDF_PSF_CW  : 17|7@1+ (1.000000,0.000000) [0.000000|100.000000] "" Airbag
 SG_ SDF_PSF_Fahrer_aktiv  : 24|1@1+ (1.000000,0.000000) [0.000000|1.000000] "" Airbag
 SG_ SDF_PSF_Guete  : 25|2@1+ (1.000000,0.000000) [0.000000|3.000000] "" Airbag
 SG_ SDF_PSF_Kollisionsueberdeckung  : 27|5@1+ (0.100000,0.000000) [0.100000|2.800000] "Unit_Meter" Airbag
 SG_ SDF_PSF_Time_To_Collision  : 32|8@1+ (0.010000,0.000000) [0.000000|2.500000] "Unit_Secon" Vector__XXX
 SG_ SDF_PSF_v_rel  : 40|8@1+ (0.400000,0.000000) [0.400000|101.200000] "Unit_MeterPerSecon" Airbag
 SG_ AWV_Eingriff_Sendeart  : 64|1@1+ (1.000000,0.000000) [0.000000|1.000000] "" Airbag
 SG_ AWV_Verz_Freigabe  : 65|1@1+ (1.000000,0.000000) [0.000000|1.000000] "" Airbag
 SG_ AWV_Verz_Anf  : 66|10@1+ (0.024000,-20.016000) [-20.016000|4.512000] "Unit_MeterPerSeconSquar" Airbag
 SG_ AWV_Anf_Prefill  : 76|1@1+ (1.000000,0.000000) [0.000000|1.000000] "" Airbag
 SG_ AWV_Ruckprofil  : 77|3@1+ (1.000000,0.000000) [0.000000|7.000000] "" Vector__XXX
 SG_ AWV_Time_to_collision  : 80|8@1+ (0.010000,0.000000) [0.000000|2.500000] "Unit_Secon" Airbag
 SG_ AWV_HBA_Param  : 88|2@1+ (1.000000,0.000000) [0.000000|3.000000] "" Vector__XXX
 SG_ AWV_Verz_Anf_ASIL  : 90|3@1+ (1.000000,0.000000) [0.000000|7.000000] "" Vector__XXX
 SG_ AWV_Time_to_brake  : 93|7@1+ (10.000000,0.000000) [0.000000|1240.000000] "Unit_MilliSecon" Vector__XXX
 SG_ AWV_Zielobjekttyp  : 100|4@1+ (1.000000,0.000000) [0.000000|15.000000] "" Airbag
 SG_ AWV_QFK_KruemmSoll  : 104|15@1+ (0.000007,0.000000) [0.000000|0.219539] "Unit_MeterInver" Vector__XXX
 SG_ AWV_QFK_KruemmSoll_VZ  : 119|1@1+ (1.000000,0.000000) [0.000000|1.000000] "" Vector__XXX
 SG_ AWV_QFK_Spuerb  : 120|8@1+ (0.400000,0.000000) [0.000000|100.000000] "Unit_PerCent" Vector__XXX
 SG_ AWV_QFK_AnfStat  : 128|4@1+ (1.000000,0.000000) [0.000000|15.000000] "" Airbag
 SG_ AWV_QFK_Signal1  : 132|10@1+ (1.000000,0.000000) [0.000000|1023.000000] "" Vector__XXX
 SG_ AWV_QFK_Art1  : 142|3@1+ (1.000000,0.000000) [0.000000|7.000000] "" Vector__XXX
 SG_ AWV_QFK_Art2  : 145|3@1+ (1.000000,0.000000) [0.000000|7.000000] "" Vector__XXX
 SG_ AWV_QFK_Signal2  : 148|10@1+ (1.000000,0.000000) [0.000000|1023.000000] "" Vector__XXX

BO_ 2536767264 BAP_Debug_Cmd: 8 BAP_Tester
 SG_ BAP_Debug_Cmd  : 0|16@1+ (1.000000,0.000000) [0.000000|65535.000000] "" Motor_BEV

BO_ 2536767280 BAP_Debug_Data: 8 Motor_BEV
 SG_ BAP_Debug_Data  : 0|64@1+ (1.000000,0.000000) [0.000000|18446744073709551616.000000] "" BAP_Tester

BO_ 2536717313 BAP_EfficiencyAssist_ASG_02: 8 ICAS1_Gateway
 SG_ BAP_EfficAssist_ASG_02_Header  : 0|64@1+ (1.000000,0.000000) [0.000000|18446744073709551616.000000] "" Motor_BEV

BO_ 2536717314 BAP_EfficiencyAssist_ASG_03: 8 ICAS1_Gateway
 SG_ BAP_EfficAssist_ASG_03_Header  : 0|8@1+ (1.000000,0.000000) [0.000000|255.000000] "" Motor_BEV

BO_ 2536717328 BAP_EfficiencyAssist_FSG_01: 8 Motor_BEV
 SG_ BAP_EfficAssist_FSG_01_Header  : 0|8@1+ (1.000000,0.000000) [0.000000|255.000000] "" ICAS1_Gateway

BO_ 2536709120 BAP_Hybrid_ASG_01: 8 ICAS1_Gateway
 SG_ BAP_Hybrid_ASG_01_Header  : 0|8@1+ (1.000000,0.000000) [0.000000|255.000000] "" Motor_BEV

BO_ 2536709136 BAP_Hybrid_FSG_01: 8 Motor_BEV
 SG_ BAP_Hybrid_FSG_01_Header  : 0|8@1+ (1.000000,0.000000) [0.000000|255.000000] "" ICAS1_Gateway

BO_ 869 BEM_05: 8 ICAS1_Gateway
 SG_ BEM_UBDM  : 0|8@1+ (0.050000,5.000000) [5.050000|17.700000] "Unit_Volt" Vector__XXX
 SG_ NVEM_Ladefreigabe  : 8|2@1+ (1.000000,0.000000) [0.000000|3.000000] "" Vector__XXX
 SG_ NVEM_FMAus_Info  : 10|2@1+ (1.000000,0.000000) [0.000000|3.000000] "" Vector__XXX
 SG_ NVEM_PTC_Sollstufe  : 12|2@1+ (1.000000,0.000000) [0.000000|3.000000] "" Vector__XXX
 SG_ NVEM_P_Generator_Status  : 15|1@1+ (1.000000,0.000000) [0.000000|1.000000] "" Vector__XXX
 SG_ BEM_P_Generator  : 16|8@1+ (50.000000,0.000000) [0.000000|12700.000000] "Unit_Watt" Vector__XXX
 SG_ BEM_n_LLA  : 24|2@1+ (1.000000,0.000000) [0.000000|3.000000] "" Vector__XXX
 SG_ BEM_01_Abschaltstufen  : 26|3@1+ (1.000000,0.000000) [0.000000|7.000000] "" Vector__XXX
 SG_ BEM_Anf_KL  : 29|1@1+ (1.000000,0.000000) [0.000000|1.000000] "" Vector__XXX
 SG_ BEM_StartStopp_Info  : 30|2@1+ (1.000000,0.000000) [0.000000|3.000000] "" Vector__XXX
 SG_ BEM_DFM  : 32|5@1+ (3.225000,0.025000) [0.025000|100.000000] "" Vector__XXX
 SG_ BEM_EMLIN_ungueltig  : 37|1@1+ (1.000000,0.000000) [0.000000|1.000000] "" Vector__XXX
 SG_ BEM_Batt_Ab  : 38|1@1+ (1.000000,0.000000) [0.000000|1.000000] "" Motor_BEV
 SG_ NVEM_FMAus_I_Verbrauch  : 39|5@1+ (5.000000,0.000000) [0.000000|145.000000] "Unit_Amper" Vector__XXX
 SG_ NVEM_Freilauf_Info  : 44|2@1+ (1.000000,0.000000) [0.000000|3.000000] "" Vector__XXX
 SG_ BEM_NV_NachladAnf  : 46|2@1+ (1.000000,0.000000) [0.000000|3.000000] "" Vector__XXX
 SG_ BEM_Segel_Info  : 48|2@1+ (1.000000,0.000000) [0.000000|3.000000] "" Vector__XXX
 SG_ BEM_HYB_DC_uSollLV  : 50|6@1+ (0.100000,10.600000) [10.600000|16.000000] "Unit_Volt" Vector__XXX
 SG_ BEM_HYB_DC_uMinLV  : 56|8@1+ (0.100000,0.000000) [0.000000|25.300000] "Unit_Volt" Vector__XXX

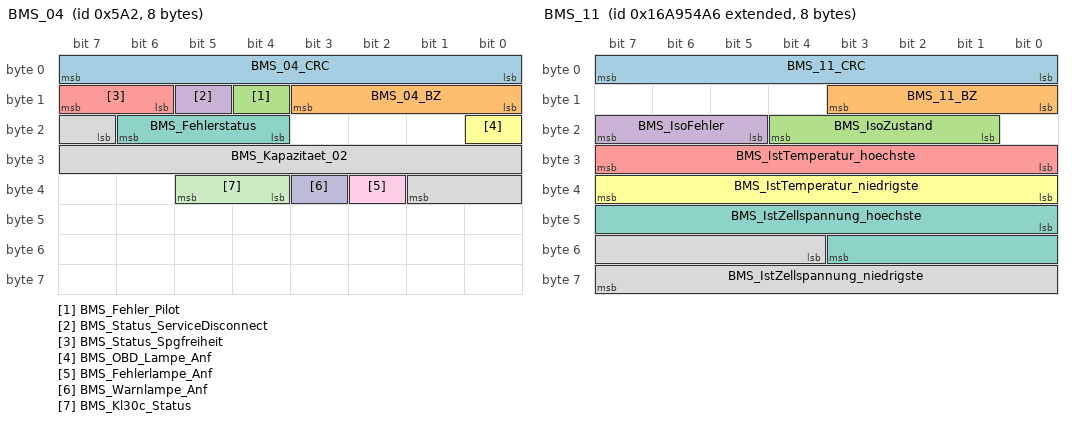
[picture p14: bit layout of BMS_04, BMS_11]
BO_ 1442 BMS_04: 8 ICAS1_Gateway
 SG_ BMS_04_CRC  : 0|8@1+ (1.000000,0.000000) [0.000000|255.000000] "" Vector__XXX
 SG_ BMS_04_BZ  : 8|4@1+ (1.000000,0.000000) [0.000000|15.000000] "" Vector__XXX
 SG_ BMS_Fehler_Pilot  : 12|1@1+ (1.000000,0.000000) [0.000000|1.000000] "" Vector__XXX
 SG_ BMS_Status_ServiceDisconnect  : 13|1@1+ (1.000000,0.000000) [0.000000|1.000000] "" Vector__XXX
 SG_ BMS_Status_Spgfreiheit  : 14|2@1+ (1.000000,0.000000) [0.000000|3.000000] "" Motor_BEV
 SG_ BMS_OBD_Lampe_Anf  : 16|1@1+ (1.000000,0.000000) [0.000000|1.000000] "" Motor_BEV
 SG_ BMS_Fehlerstatus  : 20|3@1+ (1.000000,0.000000) [0.000000|7.000000] "" Vector__XXX
 SG_ BMS_Kapazitaet_02  : 23|11@1+ (0.200000,0.000000) [0.000000|409.200000] "Unit_AmperHour" Vector__XXX
 SG_ BMS_Fehlerlampe_Anf  : 34|1@1+ (1.000000,0.000000) [0.000000|1.000000] "" Motor_BEV
 SG_ BMS_Warnlampe_Anf  : 35|1@1+ (1.000000,0.000000) [0.000000|1.000000] "" Motor_BEV
 SG_ BMS_Kl30c_Status  : 36|2@1+ (1.000000,0.000000) [0.000000|3.000000] "" Motor_BEV

BO_ 2527679654 BMS_11: 8 ICAS1_Gateway
 SG_ BMS_11_CRC  : 0|8@1+ (1.000000,0.000000) [0.000000|255.000000] "" Motor_BEV
 SG_ BMS_11_BZ  : 8|4@1+ (1.000000,0.000000) [0.000000|15.000000] "" Motor_BEV
 SG_ BMS_IsoZustand  : 17|4@1+ (1.000000,0.000000) [0.000000|15.000000] "" Motor_BEV
 SG_ BMS_IsoFehler  : 21|3@1+ (1.000000,0.000000) [0.000000|7.000000] "" Motor_BEV
 SG_ BMS_IstTemperatur_hoechste  : 24|8@1+ (0.500000,-40.000000) [-40.000000|86.000000] "Unit_DegreCelsi" Vector__XXX
 SG_ BMS_IstTemperatur_niedrigste  : 32|8@1+ (0.500000,-40.000000) [-40.000000|86.000000] "Unit_DegreCelsi" Vector__XXX
 SG_ BMS_IstZellspannung_hoechste  : 40|12@1+ (1.000000,1000.000000) [1000.000000|5091.000000] "Unit_MilliVolt" Vector__XXX
 SG_ BMS_IstZellspannung_niedrigste  : 52|12@1+ (1.000000,1000.000000) [1000.000000|5091.000000] "Unit_MilliVolt" Vector__XXX

BU_:  Airbag BAP_Tester ICAS1_Gateway ICAS1_KommunikationsServer LE1 LE2 Motor_BEV Schaltbetaetigung

BO_ 333 ACC_18: 32 ICAS1_Gateway
 SG_ ACC_18_CRC  : 0|8@1+ (1.000000,0.000000) [0.000000|255.000000] "" Motor_BEV
 SG_ ACC_18_BZ  : 8|4@1+ (1.000000,0.000000) [0.000000|15.000000] "" Motor_BEV
 SG_ ACC_limitierte_Anfahrdyn  : 12|1@0- (1.000000,0.000000) [0.000000|1.000000] "" Motor_BEV
 SG_ ACC_nachtr_Stopp_Anf  : 13|1@1+ (1.000000,0.000000) [0.000000|1.000000] "" Vector__XXX
 SG_ ACC_DynErhoehung  : 14|1@1+ (1.000000,0.000000) [0.000000|1.000000] "" Motor_BEV
 SG_ ACC_Freilaufstrategie_TSK  : 15|1@1+ (1.000000,0.000000) [0.000000|1.000000] "" Motor_BEV
 SG_ ACC_zul_Regelabw_unten  : 16|6@1+ (0.024000,0.000000) [0.000000|1.512000] "Unit_MeterPerSeconSquar" Motor_BEV
 SG_ ACC_StartStopp_Info  : 22|2@1+ (1.000000,0.000000) [0.000000|3.000000] "" Vector__XXX
 SG_ ACC_Sollbeschleunigung_02  : 24|11@1+ (0.005000,-7.220000) [-7.220000|3.005000] "Unit_MeterPerSeconSquar" Motor_BEV
 SG_ ACC_zul_Regelabw_oben  : 35|5@1+ (0.062500,0.000000) [0.000000|1.937500] "Unit_MeterPerSeconSquar" Motor_BEV
 SG_ ACC_neg_Sollbeschl_Grad_02  : 40|8@1+ (0.050000,0.000000) [0.000000|12.750000] "Unit_MeterPerCubicSecon" Motor_BEV
 SG_ ACC_pos_Sollbeschl_Grad_02  : 48|8@1+ (0.050000,0.000000) [0.000000|12.750000] "Unit_MeterPerCubicSecon" Motor_BEV
 SG_ ACC_Anfahren  : 56|1@1+ (1.000000,0.000000) [0.000000|1.000000] "" Motor_BEV
 SG_ ACC_Anhalten  : 57|1@1+ (1.000000,0.000000) [0.000000|1.000000] "" Motor_BEV
 SG_ ACC_Typ  : 58|2@1+ (1.000000,0.000000) [0.000000|3.000000] "" Motor_BEV
 SG_ ACC_Status_ACC  : 60|3@1+ (1.000000,0.000000) [0.000000|7.000000] "" Motor_BEV
 SG_ ACC_Minimale_Bremsung  : 63|1@1+ (1.000000,0.000000) [0.000000|1.000000] "" Motor_BEV
 SG_ ACC_Anhalteweg  : 64|11@1+ (0.010000,0.000000) [0.000000|20.450000] "Unit_Meter" Vector__XXX
 SG_ ACC_Boost  : 75|1@1+ (1.000000,0.000000) [0.000000|1.000000] "" Vector__XXX
 SG_ ACC_Freilauf_Anf  : 76|1@1+ (1.000000,0.000000) [0.000000|1.000000] "" Vector__XXX
 SG_ ACC_Anforderung_HMS  : 77|3@1+ (1.000000,0.000000) [0.000000|7.000000] "" Vector__XXX
 SG_ ACC_Folgebeschl  : 80|8@1+ (0.030000,-4.600000) [-4.600000|2.990000] "Unit_MeterPerSeconSquar" Motor_BEV
 SG_ ACC_Freilauf_Info  : 88|2@1+ (1.000000,0.000000) [0.000000|3.000000] "" Motor_BEV
 SG_ ACC_Tempolimitassistent_Ein  : 90|1@1+ (1.000000,0.000000) [0.000000|1.000000] "" Vector__XXX
 SG_ ACC_FoD_Status  : 91|2@1+ (1.000000,0.000000) [0.000000|3.000000] "" Motor_BEV
 SG_ vESC_Verz_Anf  : 232|4@1+ (0.500000,0.000000) [0.000000|3.500000] "Unit_MeterPerSeconSquar" Vector__XXX
 SG_ RDR_v_ueber_Grund  : 236|12@1+ (0.100000,0.000000) [0.000000|409.000000] "Unit_KiloMeterPerHour" Vector__XXX
 SG_ RDR_v_ueber_Grund_Genauigkeit  : 248|6@1+ (0.100000,0.000000) [0.000000|6.000000] "Unit_KiloMeterPerHour" Vector__XXX
 SG_ RDR_v_ueber_Grund_Fahrtrichtung  : 254|2@1+ (1.000000,0.000000) [0.000000|3.000000] "" Vector__XXX

BO_ 2527679682 ACC_ASM_01: 8 ICAS1_Gateway
 SG_ ACC_ASM_Ereignis  : 0|8@1+ (1.000000,0.000000) [1.000000|254.000000] "" Airbag
 SG_ ACC_ASM_Zeitstempel  : 8|8@1+ (0.080000,0.000000) [0.000000|20.320000] "Unit_Secon" Airbag
 SG_ ACC_ASM_Data_1  : 16|8@1+ (1.000000,0.000000) [0.000000|255.000000] "" Airbag
 SG_ ACC_ASM_Data_2  : 24|8@1+ (1.000000,0.000000) [0.000000|255.000000] "" Airbag
 SG_ ACC_ASM_Data_3  : 32|8@1+ (1.000000,0.000000) [0.000000|255.000000] "" Airbag
 SG_ ACC_ASM_Data_4  : 40|8@1+ (1.000000,0.000000) [0.000000|255.000000] "" Airbag
 SG_ ACC_ASM_Data_5  : 48|8@1+ (1.000000,0.000000) [0.000000|255.000000] "" Airbag
 SG_ ACC_ASM_Data_6  : 56|8@1+ (1.000000,0.000000) [0.000000|255.000000] "" Airbag

BO_ 64 Airbag_01: 8 Airbag
 SG_ Airbag_01_CRC  : 0|8@1+ (1.000000,0.000000) [0.000000|255.000000] "" ICAS1_Gateway LE1 LE2 Motor_BEV
 SG_ Airbag_01_BZ  : 8|4@1+ (1.000000,0.000000) [0.000000|15.000000] "" ICAS1_Gateway LE1 LE2 Motor_BEV
 SG_ AB_RGS_Anst  : 12|4@1+ (1.000000,0.000000) [0.000000|15.000000] "" ICAS1_Gateway ICAS1_KommunikationsServer
 SG_ AB_Front_Crash  : 16|1@1+ (1.000000,0.000000) [0.000000|1.000000] "" ICAS1_Gateway
 SG_ AB_Heck_Crash  : 17|1@1+ (1.000000,0.000000) [0.000000|1.000000] "" ICAS1_Gateway
 SG_ AB_SF_Crash  : 18|1@1+ (1.000000,0.000000) [0.000000|1.000000] "" ICAS1_Gateway
 SG_ AB_SB_Crash  : 19|1@1+ (1.000000,0.000000) [0.000000|1.000000] "" ICAS1_Gateway
 SG_ AB_Rollover_Crash  : 20|1@1+ (1.000000,0.000000) [0.000000|1.000000] "" ICAS1_Gateway
 SG_ AB_Crash_Int  : 21|3@1+ (1.000000,0.000000) [0.000000|7.000000] "" ICAS1_Gateway ICAS1_KommunikationsServer Motor_BEV
 SG_ AB_Lampe  : 24|1@1+ (1.000000,0.000000) [0.000000|1.000000] "" ICAS1_Gateway ICAS1_KommunikationsServer
 SG_ AB_Deaktiviert  : 25|1@1+ (1.000000,0.000000) [0.000000|1.000000] "" ICAS1_Gateway
 SG_ AB_VB_deaktiviert  : 26|1@1+ (1.000000,0.000000) [0.000000|1.000000] "" ICAS1_Gateway
 SG_ AB_Systemfehler  : 27|1@1+ (1.000000,0.000000) [0.000000|1.000000] "" ICAS1_Gateway ICAS1_KommunikationsServer
 SG_ AB_Diagnose  : 28|1@1+ (1.000000,0.000000) [0.000000|1.000000] "" ICAS1_Gateway
 SG_ AB_Stellgliedtest  : 29|1@1+ (1.000000,0.000000) [0.000000|1.000000] "" ICAS1_Gateway
 SG_ AB_Erh_Auf_VB  : 30|2@1+ (1.000000,0.000000) [0.000000|3.000000] "" ICAS1_Gateway
 SG_ AB_Gurtwarn_VF  : 32|1@1+ (1.000000,0.000000) [0.000000|1.000000] "" ICAS1_Gateway ICAS1_KommunikationsServer
 SG_ AB_Gurtwarn_VB  : 33|1@1+ (1.000000,0.000000) [0.000000|1.000000] "" ICAS1_Gateway ICAS1_KommunikationsServer
 SG_ AB_Anzeige_Fussg  : 34|2@1+ (1.000000,0.000000) [0.000000|3.000000] "" ICAS1_Gateway
 SG_ AB_Texte_AKS  : 36|2@1+ (1.000000,0.000000) [0.000000|3.000000] "" ICAS1_Gateway
 SG_ AB_PAO_Leuchte_Anf  : 38|1@1+ (1.000000,0.000000) [0.000000|1.000000] "" ICAS1_Gateway
 SG_ AB_MKB_gueltig  : 39|1@1+ (1.000000,0.000000) [0.000000|1.000000] "" ICAS1_Gateway
 SG_ AB_MKB_Anforderung  : 40|1@1+ (1.000000,0.000000) [0.000000|1.000000] "" ICAS1_Gateway
 SG_ AB_Versorgungsspannung  : 41|1@1+ (1.000000,0.000000) [0.000000|1.000000] "" ICAS1_Gateway
 SG_ AB_Deaktivierung_HV  : 42|3@1+ (1.000000,0.000000) [0.000000|7.000000] "" ICAS1_Gateway ICAS1_KommunikationsServer LE1 LE2 Motor_BEV
 SG_ AB_EDR_Trigger  : 45|2@1+ (1.000000,0.000000) [0.000000|3.000000] "" ICAS1_Gateway
 SG_ AB_Belegung_VF  : 47|2@1+ (1.000000,0.000000) [0.000000|3.000000] "" ICAS1_Gateway
 SG_ AB_Gurtschloss_FA_ext  : 49|3@1+ (1.000000,0.000000) [0.000000|7.000000] "" ICAS1_Gateway
 SG_ AB_Belegung_VF_ext  : 52|3@1+ (1.000000,0.000000) [0.000000|7.000000] "" ICAS1_Gateway
 SG_ ASM_Masterzeit  : 56|8@1+ (0.080000,0.000000) [0.000000|20.320000] "Unit_Secon" ICAS1_Gateway

BO_ 1312 Airbag_02: 8 Airbag
 SG_ Airbag_02_CRC  : 0|8@1+ (1.000000,0.000000) [0.000000|255.000000] "" ICAS1_Gateway Motor_BEV
 SG_ Airbag_02_BZ  : 8|4@1+ (1.000000,0.000000) [0.000000|15.000000] "" ICAS1_Gateway Motor_BEV
 SG_ LoGeWa_Event_Kombiwarnung  : 12|4@1+ (1.000000,0.000000) [0.000000|15.000000] "" ICAS1_Gateway
 SG_ AB_Anforderung_eCall  : 16|1@1+ (1.000000,0.000000) [0.000000|1.000000] "" ICAS1_Gateway
 SG_ AB_Anprall_Seite_Beifahrer  : 17|1@1+ (1.000000,0.000000) [0.000000|1.000000] "" ICAS1_Gateway ICAS1_KommunikationsServer
 SG_ AB_Anprall_Rollover  : 18|1@1+ (1.000000,0.000000) [0.000000|1.000000] "" ICAS1_Gateway ICAS1_KommunikationsServer
 SG_ AB_Anprall_FGS  : 19|1@1+ (1.000000,0.000000) [0.000000|1.000000] "" ICAS1_Gateway ICAS1_KommunikationsServer
 SG_ AB_Anprall_Front_Beifahrer  : 20|1@1+ (1.000000,0.000000) [0.000000|1.000000] "" ICAS1_Gateway ICAS1_KommunikationsServer
 SG_ AB_Anprall_Front_Fahrer  : 21|1@1+ (1.000000,0.000000) [0.000000|1.000000] "" ICAS1_Gateway ICAS1_KommunikationsServer
 SG_ AB_Anprall_Heck_Beifahrer  : 22|1@1+ (1.000000,0.000000) [0.000000|1.000000] "" ICAS1_Gateway ICAS1_KommunikationsServer
 SG_ AB_Anprall_Heck_Fahrer  : 23|1@1+ (1.000000,0.000000) [0.000000|1.000000] "" ICAS1_Gateway ICAS1_KommunikationsServer
 SG_ AB_Wickelklappung_Reihe2_MI  : 24|2@1+ (1.000000,0.000000) [0.000000|3.000000] "" ICAS1_Gateway
 SG_ AB_Belegung_VB  : 26|2@1+ (1.000000,0.000000) [0.000000|3.000000] "" ICAS1_Gateway
 SG_ AB_Abschaltanf_SIH_BF  : 28|1@1+ (1.000000,0.000000) [0.000000|1.000000] "" ICAS1_Gateway
 SG_ AB_Anprall_Seite_Fahrer  : 29|1@1+ (1.000000,0.000000) [0.000000|1.000000] "" ICAS1_Gateway ICAS1_KommunikationsServer
 SG_ SC_PAO_Schriftzug_Anf  : 30|2@1+ (1.000000,0.000000) [0.000000|3.000000] "" ICAS1_Gateway
 SG_ SC_PAO_ON_Anf  : 32|2@1+ (1.000000,0.000000) [0.000000|3.000000] "" ICAS1_Gateway
 SG_ SC_PAO_OFF_Anf  : 34|2@1+ (1.000000,0.000000) [0.000000|3.000000] "" ICAS1_Gateway
 SG_ AB_Crashschwere  : 36|3@1+ (1.000000,0.000000) [0.000000|7.000000] "" ICAS1_Gateway ICAS1_KommunikationsServer
 SG_ AB_Anforderung_USM  : 39|1@1+ (1.000000,0.000000) [0.000000|1.000000] "" ICAS1_Gateway
 SG_ AB_Gurtschloss_FA  : 40|2@1+ (1.000000,0.000000) [0.000000|3.000000] "" ICAS1_Gateway ICAS1_KommunikationsServer Motor_BEV
 SG_ AB_Gurtschloss_BF  : 42|2@1+ (1.000000,0.000000) [0.000000|3.000000] "" ICAS1_Gateway ICAS1_KommunikationsServer
 SG_ AB_Gurtschloss_Reihe2_FA  : 44|2@1+ (1.000000,0.000000) [0.000000|3.000000] "" ICAS1_Gateway ICAS1_KommunikationsServer
 SG_ AB_Gurtschloss_Reihe2_MI  : 46|2@1+ (1.000000,0.000000) [0.000000|3.000000] "" ICAS1_Gateway ICAS1_KommunikationsServer
 SG_ AB_Gurtschloss_Reihe2_BF  : 48|2@1+ (1.000000,0.000000) [0.000000|3.000000] "" ICAS1_Gateway ICAS1_KommunikationsServer
 SG_ AB_Gurtschloss_Reihe3_FA  : 50|2@1+ (1.000000,0.000000) [0.000000|3.000000] "" ICAS1_Gateway ICAS1_KommunikationsServer
 SG_ AB_Gurtschloss_Reihe3_MI  : 52|2@1+ (1.000000,0.000000) [0.000000|3.000000] "" ICAS1_Gateway ICAS1_KommunikationsServer
 SG_ AB_Gurtschloss_Reihe3_BF  : 54|2@1+ (1.000000,0.000000) [0.000000|3.000000] "" ICAS1_Gateway ICAS1_KommunikationsServer
 SG_ AB_Sitzpos_Sens_FA  : 56|2@1+ (1.000000,0.000000) [0.000000|3.000000] "" ICAS1_Gateway
 SG_ AB_Sitzpos_Sens_BF  : 58|2@1+ (1.000000,0.000000) [0.000000|3.000000] "" ICAS1_Gateway
 SG_ AB_Wickelklappung_Reihe2_BF  : 60|2@1+ (1.000000,0.000000) [0.000000|3.000000] "" ICAS1_Gateway
 SG_ AB_Wickelklappung_Reihe2_FA  : 62|2@1+ (1.000000,0.000000) [0.000000|3.000000] "" ICAS1_Gateway

BO_ 65 Airbag_03: 8 Airbag
 SG_ Airbag_03_CRC  : 0|8@1+ (1.000000,0.000000) [0.000000|255.000000] "" ICAS1_Gateway
 SG_ Airbag_03_BZ  : 8|4@1+ (1.000000,0.000000) [0.000000|15.000000] "" ICAS1_Gateway
 SG_ AB_MKB_Safing  : 63|1@1+ (1.000000,0.000000) [0.000000|1.000000] "" ICAS1_Gateway

BO_ 1349 Airbag_04: 8 Airbag
 SG_ AB_Gurtwarn_Reihe4_FA  : 14|2@1+ (1.000000,0.000000) [0.000000|3.000000] "" ICAS1_Gateway ICAS1_KommunikationsServer
 SG_ AB_Gurtwarn_Reihe4_BF  : 16|2@1+ (1.000000,0.000000) [0.000000|3.000000] "" ICAS1_Gateway ICAS1_KommunikationsServer
 SG_ AB_Gurtwarn_Reihe4_MI  : 18|2@1+ (1.000000,0.000000) [0.000000|3.000000] "" ICAS1_Gateway ICAS1_KommunikationsServer
 SG_ AB_Gurtwarn_Reihe2_FA  : 20|2@1+ (1.000000,0.000000) [0.000000|3.000000] "" ICAS1_Gateway ICAS1_KommunikationsServer
 SG_ AB_Gurtwarn_Reihe2_BF  : 22|2@1+ (1.000000,0.000000) [0.000000|3.000000] "" ICAS1_Gateway ICAS1_KommunikationsServer
 SG_ AbstWarn_MV_FAS_Fkt_Status  : 24|2@1+ (1.000000,0.000000) [0.000000|3.000000] "" ICAS1_Gateway
 SG_ WarnBrems_Charisma_Status  : 26|2@1+ (1.000000,0.000000) [0.000000|3.000000] "" ICAS1_Gateway
 SG_ WarnBrems_Charisma_FahrPr  : 28|4@1+ (1.000000,0.000000) [0.000000|15.000000] "" ICAS1_Gateway
 SG_ AB_Gurtwarn_Reihe2_MI  : 32|2@1+ (1.000000,0.000000) [0.000000|3.000000] "" ICAS1_Gateway ICAS1_KommunikationsServer
 SG_ AB_Gurtwarn_Reihe3_FA  : 34|2@1+ (1.000000,0.000000) [0.000000|3.000000] "" ICAS1_Gateway ICAS1_KommunikationsServer
 SG_ AB_Gurtwarn_Reihe3_MI  : 36|2@1+ (1.000000,0.000000) [0.000000|3.000000] "" ICAS1_Gateway ICAS1_KommunikationsServer
 SG_ AB_Gurtwarn_Reihe3_BF  : 38|2@1+ (1.000000,0.000000) [0.000000|3.000000] "" ICAS1_Gateway ICAS1_KommunikationsServer
 SG_ LGI_FAS_Fkt_Status  : 40|2@1+ (1.000000,0.000000) [0.000000|3.000000] "" ICAS1_Gateway
 SG_ PreCrash_FAS_Fkt_Status  : 42|3@1+ (1.000000,0.000000) [0.000000|7.000000] "" ICAS1_Gateway
 SG_ AB_SBR_hinten_verbau  : 48|2@1+ (1.000000,0.000000) [0.000000|3.000000] "" ICAS1_Gateway ICAS1_KommunikationsServer
 SG_ AWV_Einstellung_System_ASG  : 51|1@1+ (1.000000,0.000000) [0.000000|1.000000] "" ICAS1_Gateway
 SG_ AWV_Einstellung_Warnung_ASG  : 52|3@1+ (1.000000,0.000000) [0.000000|7.000000] "" ICAS1_Gateway
 SG_ SC_PreSense_Modus_Warnung_NV  : 55|3@1+ (1.000000,0.000000) [0.000000|7.000000] "" ICAS1_Gateway
 SG_ SC_PreSense_Modus_Warnung_MV  : 58|3@1+ (1.000000,0.000000) [0.000000|7.000000] "" ICAS1_Gateway
 SG_ SC_PreSense_Modus_System_MV  : 61|1@1+ (1.000000,0.000000) [0.000000|1.000000] "" ICAS1_Gateway
 SG_ SC_PreSense_Modus_System_NV  : 62|1@1+ (1.000000,0.000000) [0.000000|1.000000] "" ICAS1_Gateway
 SG_ SC_PreSense_Modus_System_KAS  : 63|1@1+ (1.000000,0.000000) [0.000000|1.000000] "" ICAS1_Gateway

BO_ 2527679722 Airbag_06: 8 Airbag
 SG_ AB_Gurtschloss_Reihe4_FA  : 12|2@1+ (1.000000,0.000000) [0.000000|3.000000] "" ICAS1_Gateway ICAS1_KommunikationsServer
 SG_ AB_Gurtschloss_Reihe4_BF  : 14|2@1+ (1.000000,0.000000) [0.000000|3.000000] "" ICAS1_Gateway ICAS1_KommunikationsServer
 SG_ AB_Gurtschloss_Reihe4_MI  : 16|2@1+ (1.000000,0.000000) [0.000000|3.000000] "" ICAS1_Gateway ICAS1_KommunikationsServer

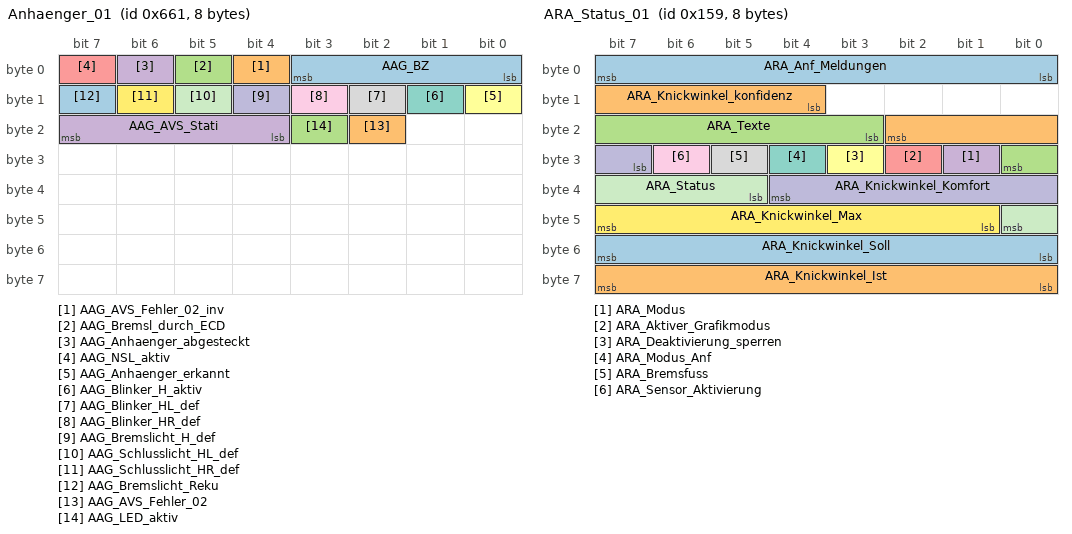
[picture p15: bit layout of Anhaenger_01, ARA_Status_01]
BO_ 1633 Anhaenger_01: 8 ICAS1_Gateway
 SG_ AAG_BZ  : 0|4@1+ (1.000000,0.000000) [0.000000|15.000000] "" Vector__XXX
 SG_ AAG_AVS_Fehler_02_inv  : 4|1@1+ (1.000000,0.000000) [0.000000|1.000000] "" Vector__XXX
 SG_ AAG_Bremsl_durch_ECD  : 5|1@1+ (1.000000,0.000000) [0.000000|1.000000] "" Motor_BEV
 SG_ AAG_Anhaenger_abgesteckt  : 6|1@1+ (1.000000,0.000000) [0.000000|1.000000] "" Motor_BEV
 SG_ AAG_NSL_aktiv  : 7|1@1+ (1.000000,0.000000) [0.000000|1.000000] "" Vector__XXX
 SG_ AAG_Anhaenger_erkannt  : 8|1@1+ (1.000000,0.000000) [0.000000|1.000000] "" Motor_BEV
 SG_ AAG_Blinker_H_aktiv  : 9|1@1+ (1.000000,0.000000) [0.000000|1.000000] "" Vector__XXX
 SG_ AAG_Blinker_HL_def  : 10|1@1+ (1.000000,0.000000) [0.000000|1.000000] "" Vector__XXX
 SG_ AAG_Blinker_HR_def  : 11|1@1+ (1.000000,0.000000) [0.000000|1.000000] "" Vector__XXX
 SG_ AAG_Bremslicht_H_def  : 12|1@1+ (1.000000,0.000000) [0.000000|1.000000] "" Motor_BEV
 SG_ AAG_Schlusslicht_HL_def  : 13|1@1+ (1.000000,0.000000) [0.000000|1.000000] "" Vector__XXX
 SG_ AAG_Schlusslicht_HR_def  : 14|1@1+ (1.000000,0.000000) [0.000000|1.000000] "" Vector__XXX
 SG_ AAG_Bremslicht_Reku  : 15|1@1+ (1.000000,0.000000) [0.000000|1.000000] "" Vector__XXX
 SG_ AAG_AVS_Fehler_02  : 18|1@1+ (1.000000,0.000000) [0.000000|1.000000] "" Vector__XXX
 SG_ AAG_LED_aktiv  : 19|1@1+ (1.000000,0.000000) [0.000000|1.000000] "" Vector__XXX
 SG_ AAG_AVS_Stati  : 20|4@1+ (1.000000,0.000000) [0.000000|15.000000] "" Vector__XXX

BO_ 345 ARA_Status_01: 8 ICAS1_Gateway
 SG_ ARA_Anf_Meldungen  : 0|8@1+ (1.000000,0.000000) [0.000000|255.000000] "" Vector__XXX
 SG_ ARA_Knickwinkel_konfidenz  : 12|7@1+ (1.000000,0.000000) [0.000000|120.000000] "Unit_DegreOfArc" Vector__XXX
 SG_ ARA_Texte  : 19|6@1+ (1.000000,0.000000) [0.000000|63.000000] "" Vector__XXX
 SG_ ARA_Modus  : 25|1@1+ (1.000000,0.000000) [0.000000|1.000000] "" Vector__XXX
 SG_ ARA_Aktiver_Grafikmodus  : 26|1@1+ (1.000000,0.000000) [0.000000|1.000000] "" Vector__XXX
 SG_ ARA_Deaktivierung_sperren  : 27|1@1+ (1.000000,0.000000) [0.000000|1.000000] "" Vector__XXX
 SG_ ARA_Modus_Anf  : 28|1@1+ (1.000000,0.000000) [0.000000|1.000000] "" Vector__XXX
 SG_ ARA_Bremsfuss  : 29|1@1+ (1.000000,0.000000) [0.000000|1.000000] "" Vector__XXX
 SG_ ARA_Sensor_Aktivierung  : 30|1@1+ (1.000000,0.000000) [0.000000|1.000000] "" Vector__XXX
 SG_ ARA_Knickwinkel_Komfort  : 31|6@1+ (1.000000,0.000000) [0.000000|60.000000] "Unit_DegreOfArc" Vector__XXX
 SG_ ARA_Status  : 37|4@1+ (1.000000,0.000000) [0.000000|15.000000] "" Motor_BEV
 SG_ ARA_Knickwinkel_Max  : 41|7@1+ (1.000000,0.000000) [0.000000|120.000000] "Unit_DegreOfArc" Vector__XXX
 SG_ ARA_Knickwinkel_Soll  : 48|8@1+ (1.000000,-125.000000) [-125.000000|126.000000] "Unit_DegreOfArc" Vector__XXX
 SG_ ARA_Knickwinkel_Ist  : 56|8@1+ (1.000000,-125.000000) [-125.000000|126.000000] "Unit_DegreOfArc" Vector__XXX

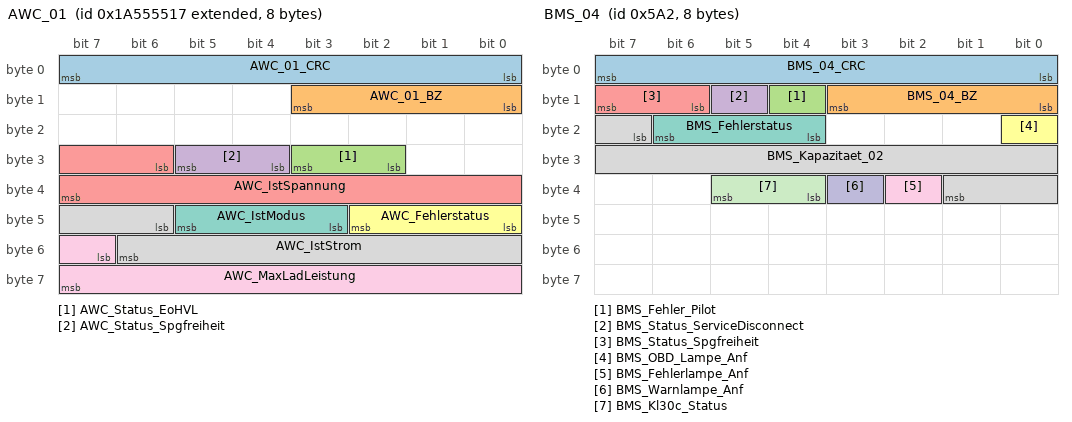
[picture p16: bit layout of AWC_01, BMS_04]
BO_ 2589283607 AWC_01: 8 ICAS1_Gateway
 SG_ AWC_01_CRC  : 0|8@1+ (1.000000,0.000000) [0.000000|255.000000] "" Vector__XXX
 SG_ AWC_01_BZ  : 8|4@1+ (1.000000,0.000000) [0.000000|15.000000] "" Vector__XXX
 SG_ AWC_Status_EoHVL  : 26|2@1+ (1.000000,0.000000) [0.000000|3.000000] "" Motor_BEV
 SG_ AWC_Status_Spgfreiheit  : 28|2@1+ (1.000000,0.000000) [0.000000|3.000000] "" Vector__XXX
 SG_ AWC_IstSpannung  : 30|10@1+ (1.000000,0.000000) [0.000000|1021.000000] "Unit_Volt" Vector__XXX
 SG_ AWC_Fehlerstatus  : 40|3@1+ (1.000000,0.000000) [0.000000|7.000000] "" Vector__XXX
 SG_ AWC_IstModus  : 43|3@1+ (1.000000,0.000000) [0.000000|7.000000] "" Vector__XXX
 SG_ AWC_IstStrom  : 46|9@1+ (0.100000,0.000000) [0.000000|50.900000] "Unit_Amper" Vector__XXX
 SG_ AWC_MaxLadLeistung  : 55|9@1+ (25.000000,0.000000) [0.000000|12725.000000] "Unit_Watt" Vector__XXX

BO_ 219 AWV_03: 48 ICAS1_Gateway
 SG_ AWV_03_CRC  : 0|8@1+ (1.000000,0.000000) [0.000000|255.000000] "" Airbag
 SG_ AWV_03_BZ  : 8|4@1+ (1.000000,0.000000) [0.000000|15.000000] "" Airbag
 SG_ PCF_Freigabe  : 12|1@1+ (1.000000,0.000000) [0.000000|1.000000] "" Airbag
 SG_ SDF_PSF_Objektstatus  : 13|3@1+ (1.000000,0.000000) [0.000000|7.000000] "" Airbag
 SG_ SDF_PSF_CU_Status  : 16|1@1+ (1.000000,0.000000) [0.000000|1.000000] "" Airbag
 SG_ SDF_PSF_CW  : 17|7@1+ (1.000000,0.000000) [0.000000|100.000000] "" Airbag
 SG_ SDF_PSF_Fahrer_aktiv  : 24|1@1+ (1.000000,0.000000) [0.000000|1.000000] "" Airbag
 SG_ SDF_PSF_Guete  : 25|2@1+ (1.000000,0.000000) [0.000000|3.000000] "" Airbag
 SG_ SDF_PSF_Kollisionsueberdeckung  : 27|5@1+ (0.100000,0.000000) [0.100000|2.800000] "Unit_Meter" Airbag
 SG_ SDF_PSF_Time_To_Collision  : 32|8@1+ (0.010000,0.000000) [0.000000|2.500000] "Unit_Secon" Vector__XXX
 SG_ SDF_PSF_v_rel  : 40|8@1+ (0.400000,0.000000) [0.400000|101.200000] "Unit_MeterPerSecon" Airbag
 SG_ AWV_Eingriff_Sendeart  : 64|1@1+ (1.000000,0.000000) [0.000000|1.000000] "" Airbag
 SG_ AWV_Verz_Freigabe  : 65|1@1+ (1.000000,0.000000) [0.000000|1.000000] "" Airbag
 SG_ AWV_Verz_Anf  : 66|10@1+ (0.024000,-20.016000) [-20.016000|4.512000] "Unit_MeterPerSeconSquar" Airbag
 SG_ AWV_Anf_Prefill  : 76|1@1+ (1.000000,0.000000) [0.000000|1.000000] "" Airbag
 SG_ AWV_Ruckprofil  : 77|3@1+ (1.000000,0.000000) [0.000000|7.000000] "" Vector__XXX
 SG_ AWV_Time_to_collision  : 80|8@1+ (0.010000,0.000000) [0.000000|2.500000] "Unit_Secon" Airbag
 SG_ AWV_HBA_Param  : 88|2@1+ (1.000000,0.000000) [0.000000|3.000000] "" Vector__XXX
 SG_ AWV_Verz_Anf_ASIL  : 90|3@1+ (1.000000,0.000000) [0.000000|7.000000] "" Vector__XXX
 SG_ AWV_Time_to_brake  : 93|7@1+ (10.000000,0.000000) [0.000000|1240.000000] "Unit_MilliSecon" Vector__XXX
 SG_ AWV_Zielobjekttyp  : 100|4@1+ (1.000000,0.000000) [0.000000|15.000000] "" Airbag
 SG_ AWV_QFK_KruemmSoll  : 104|15@1+ (0.000007,0.000000) [0.000000|0.219539] "Unit_MeterInver" Vector__XXX
 SG_ AWV_QFK_KruemmSoll_VZ  : 119|1@1+ (1.000000,0.000000) [0.000000|1.000000] "" Vector__XXX
 SG_ AWV_QFK_Spuerb  : 120|8@1+ (0.400000,0.000000) [0.000000|100.000000] "Unit_PerCent" Vector__XXX
 SG_ AWV_QFK_AnfStat  : 128|4@1+ (1.000000,0.000000) [0.000000|15.000000] "" Airbag
 SG_ AWV_QFK_Signal1  : 132|10@1+ (1.000000,0.000000) [0.000000|1023.000000] "" Vector__XXX
 SG_ AWV_QFK_Art1  : 142|3@1+ (1.000000,0.000000) [0.000000|7.000000] "" Vector__XXX
 SG_ AWV_QFK_Art2  : 145|3@1+ (1.000000,0.000000) [0.000000|7.000000] "" Vector__XXX
 SG_ AWV_QFK_Signal2  : 148|10@1+ (1.000000,0.000000) [0.000000|1023.000000] "" Vector__XXX

BO_ 2536767264 BAP_Debug_Cmd: 8 BAP_Tester
 SG_ BAP_Debug_Cmd  : 0|16@1+ (1.000000,0.000000) [0.000000|65535.000000] "" Motor_BEV

BO_ 2536767280 BAP_Debug_Data: 8 Motor_BEV
 SG_ BAP_Debug_Data  : 0|64@1+ (1.000000,0.000000) [0.000000|18446744073709551616.000000] "" BAP_Tester

BO_ 2536717313 BAP_EfficiencyAssist_ASG_02: 8 ICAS1_Gateway
 SG_ BAP_EfficAssist_ASG_02_Header  : 0|64@1+ (1.000000,0.000000) [0.000000|18446744073709551616.000000] "" Motor_BEV

BO_ 2536717314 BAP_EfficiencyAssist_ASG_03: 8 ICAS1_Gateway
 SG_ BAP_EfficAssist_ASG_03_Header  : 0|8@1+ (1.000000,0.000000) [0.000000|255.000000] "" Motor_BEV

BO_ 2536717328 BAP_EfficiencyAssist_FSG_01: 8 Motor_BEV
 SG_ BAP_EfficAssist_FSG_01_Header  : 0|8@1+ (1.000000,0.000000) [0.000000|255.000000] "" ICAS1_Gateway

BO_ 2536709120 BAP_Hybrid_ASG_01: 8 ICAS1_Gateway
 SG_ BAP_Hybrid_ASG_01_Header  : 0|8@1+ (1.000000,0.000000) [0.000000|255.000000] "" Motor_BEV

BO_ 2536709136 BAP_Hybrid_FSG_01: 8 Motor_BEV
 SG_ BAP_Hybrid_FSG_01_Header  : 0|8@1+ (1.000000,0.000000) [0.000000|255.000000] "" ICAS1_Gateway

BO_ 869 BEM_05: 8 ICAS1_Gateway
 SG_ BEM_UBDM  : 0|8@1+ (0.050000,5.000000) [5.050000|17.700000] "Unit_Volt" Vector__XXX
 SG_ NVEM_Ladefreigabe  : 8|2@1+ (1.000000,0.000000) [0.000000|3.000000] "" Vector__XXX
 SG_ NVEM_FMAus_Info  : 10|2@1+ (1.000000,0.000000) [0.000000|3.000000] "" Vector__XXX
 SG_ NVEM_PTC_Sollstufe  : 12|2@1+ (1.000000,0.000000) [0.000000|3.000000] "" Vector__XXX
 SG_ NVEM_P_Generator_Status  : 15|1@1+ (1.000000,0.000000) [0.000000|1.000000] "" Vector__XXX
 SG_ BEM_P_Generator  : 16|8@1+ (50.000000,0.000000) [0.000000|12700.000000] "Unit_Watt" Vector__XXX
 SG_ BEM_n_LLA  : 24|2@1+ (1.000000,0.000000) [0.000000|3.000000] "" Vector__XXX
 SG_ BEM_01_Abschaltstufen  : 26|3@1+ (1.000000,0.000000) [0.000000|7.000000] "" Vector__XXX
 SG_ BEM_Anf_KL  : 29|1@1+ (1.000000,0.000000) [0.000000|1.000000] "" Vector__XXX
 SG_ BEM_StartStopp_Info  : 30|2@1+ (1.000000,0.000000) [0.000000|3.000000] "" Vector__XXX
 SG_ BEM_DFM  : 32|5@1+ (3.225000,0.025000) [0.025000|100.000000] "" Vector__XXX
 SG_ BEM_EMLIN_ungueltig  : 37|1@1+ (1.000000,0.000000) [0.000000|1.000000] "" Vector__XXX
 SG_ BEM_Batt_Ab  : 38|1@1+ (1.000000,0.000000) [0.000000|1.000000] "" Motor_BEV
 SG_ NVEM_FMAus_I_Verbrauch  : 39|5@1+ (5.000000,0.000000) [0.000000|145.000000] "Unit_Amper" Vector__XXX
 SG_ NVEM_Freilauf_Info  : 44|2@1+ (1.000000,0.000000) [0.000000|3.000000] "" Vector__XXX
 SG_ BEM_NV_NachladAnf  : 46|2@1+ (1.000000,0.000000) [0.000000|3.000000] "" Vector__XXX
 SG_ BEM_Segel_Info  : 48|2@1+ (1.000000,0.000000) [0.000000|3.000000] "" Vector__XXX
 SG_ BEM_HYB_DC_uSollLV  : 50|6@1+ (0.100000,10.600000) [10.600000|16.000000] "Unit_Volt" Vector__XXX
 SG_ BEM_HYB_DC_uMinLV  : 56|8@1+ (0.100000,0.000000) [0.000000|25.300000] "Unit_Volt" Vector__XXX

BO_ 1442 BMS_04: 8 ICAS1_Gateway
 SG_ BMS_04_CRC  : 0|8@1+ (1.000000,0.000000) [0.000000|255.000000] "" Vector__XXX
 SG_ BMS_04_BZ  : 8|4@1+ (1.000000,0.000000) [0.000000|15.000000] "" Vector__XXX
 SG_ BMS_Fehler_Pilot  : 12|1@1+ (1.000000,0.000000) [0.000000|1.000000] "" Vector__XXX
 SG_ BMS_Status_ServiceDisconnect  : 13|1@1+ (1.000000,0.000000) [0.000000|1.000000] "" Vector__XXX
 SG_ BMS_Status_Spgfreiheit  : 14|2@1+ (1.000000,0.000000) [0.000000|3.000000] "" Motor_BEV
 SG_ BMS_OBD_Lampe_Anf  : 16|1@1+ (1.000000,0.000000) [0.000000|1.000000] "" Motor_BEV
 SG_ BMS_Fehlerstatus  : 20|3@1+ (1.000000,0.000000) [0.000000|7.000000] "" Vector__XXX
 SG_ BMS_Kapazitaet_02  : 23|11@1+ (0.200000,0.000000) [0.000000|409.200000] "Unit_AmperHour" Vector__XXX
 SG_ BMS_Fehlerlampe_Anf  : 34|1@1+ (1.000000,0.000000) [0.000000|1.000000] "" Motor_BEV
 SG_ BMS_Warnlampe_Anf  : 35|1@1+ (1.000000,0.000000) [0.000000|1.000000] "" Motor_BEV
 SG_ BMS_Kl30c_Status  : 36|2@1+ (1.000000,0.000000) [0.000000|3.000000] "" Motor_BEV

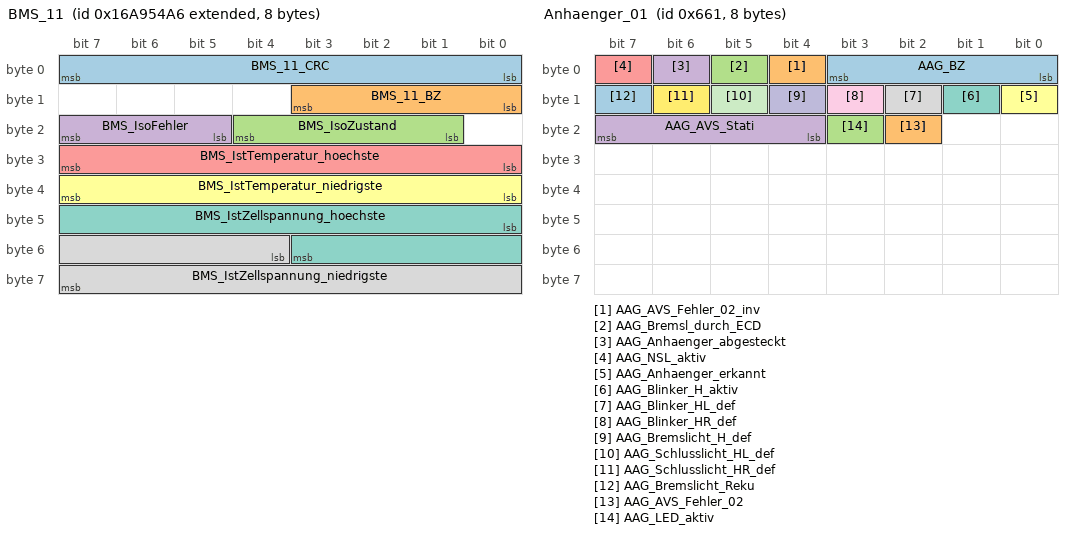
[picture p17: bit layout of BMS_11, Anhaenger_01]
BO_ 2527679654 BMS_11: 8 ICAS1_Gateway
 SG_ BMS_11_CRC  : 0|8@1+ (1.000000,0.000000) [0.000000|255.000000] "" Motor_BEV
 SG_ BMS_11_BZ  : 8|4@1+ (1.000000,0.000000) [0.000000|15.000000] "" Motor_BEV
 SG_ BMS_IsoZustand  : 17|4@1+ (1.000000,0.000000) [0.000000|15.000000] "" Motor_BEV
 SG_ BMS_IsoFehler  : 21|3@1+ (1.000000,0.000000) [0.000000|7.000000] "" Motor_BEV
 SG_ BMS_IstTemperatur_hoechste  : 24|8@1+ (0.500000,-40.000000) [-40.000000|86.000000] "Unit_DegreCelsi" Vector__XXX
 SG_ BMS_IstTemperatur_niedrigste  : 32|8@1+ (0.500000,-40.000000) [-40.000000|86.000000] "Unit_DegreCelsi" Vector__XXX
 SG_ BMS_IstZellspannung_hoechste  : 40|12@1+ (1.000000,1000.000000) [1000.000000|5091.000000] "Unit_MilliVolt" Vector__XXX
 SG_ BMS_IstZellspannung_niedrigste  : 52|12@1+ (1.000000,1000.000000) [1000.000000|5091.000000] "Unit_MilliVolt" Vector__XXX

BU_:  Airbag BAP_Tester ICAS1_Gateway ICAS1_KommunikationsServer LE1 LE2 Motor_BEV Schaltbetaetigung

BO_ 333 ACC_18: 32 ICAS1_Gateway
 SG_ ACC_18_CRC  : 0|8@1+ (1.000000,0.000000) [0.000000|255.000000] "" Motor_BEV
 SG_ ACC_18_BZ  : 8|4@1+ (1.000000,0.000000) [0.000000|15.000000] "" Motor_BEV
 SG_ ACC_limitierte_Anfahrdyn  : 12|1@0- (1.000000,0.000000) [0.000000|1.000000] "" Motor_BEV
 SG_ ACC_nachtr_Stopp_Anf  : 13|1@1+ (1.000000,0.000000) [0.000000|1.000000] "" Vector__XXX
 SG_ ACC_DynErhoehung  : 14|1@1+ (1.000000,0.000000) [0.000000|1.000000] "" Motor_BEV
 SG_ ACC_Freilaufstrategie_TSK  : 15|1@1+ (1.000000,0.000000) [0.000000|1.000000] "" Motor_BEV
 SG_ ACC_zul_Regelabw_unten  : 16|6@1+ (0.024000,0.000000) [0.000000|1.512000] "Unit_MeterPerSeconSquar" Motor_BEV
 SG_ ACC_StartStopp_Info  : 22|2@1+ (1.000000,0.000000) [0.000000|3.000000] "" Vector__XXX
 SG_ ACC_Sollbeschleunigung_02  : 24|11@1+ (0.005000,-7.220000) [-7.220000|3.005000] "Unit_MeterPerSeconSquar" Motor_BEV
 SG_ ACC_zul_Regelabw_oben  : 35|5@1+ (0.062500,0.000000) [0.000000|1.937500] "Unit_MeterPerSeconSquar" Motor_BEV
 SG_ ACC_neg_Sollbeschl_Grad_02  : 40|8@1+ (0.050000,0.000000) [0.000000|12.750000] "Unit_MeterPerCubicSecon" Motor_BEV
 SG_ ACC_pos_Sollbeschl_Grad_02  : 48|8@1+ (0.050000,0.000000) [0.000000|12.750000] "Unit_MeterPerCubicSecon" Motor_BEV
 SG_ ACC_Anfahren  : 56|1@1+ (1.000000,0.000000) [0.000000|1.000000] "" Motor_BEV
 SG_ ACC_Anhalten  : 57|1@1+ (1.000000,0.000000) [0.000000|1.000000] "" Motor_BEV
 SG_ ACC_Typ  : 58|2@1+ (1.000000,0.000000) [0.000000|3.000000] "" Motor_BEV
 SG_ ACC_Status_ACC  : 60|3@1+ (1.000000,0.000000) [0.000000|7.000000] "" Motor_BEV
 SG_ ACC_Minimale_Bremsung  : 63|1@1+ (1.000000,0.000000) [0.000000|1.000000] "" Motor_BEV
 SG_ ACC_Anhalteweg  : 64|11@1+ (0.010000,0.000000) [0.000000|20.450000] "Unit_Meter" Vector__XXX
 SG_ ACC_Boost  : 75|1@1+ (1.000000,0.000000) [0.000000|1.000000] "" Vector__XXX
 SG_ ACC_Freilauf_Anf  : 76|1@1+ (1.000000,0.000000) [0.000000|1.000000] "" Vector__XXX
 SG_ ACC_Anforderung_HMS  : 77|3@1+ (1.000000,0.000000) [0.000000|7.000000] "" Vector__XXX
 SG_ ACC_Folgebeschl  : 80|8@1+ (0.030000,-4.600000) [-4.600000|2.990000] "Unit_MeterPerSeconSquar" Motor_BEV
 SG_ ACC_Freilauf_Info  : 88|2@1+ (1.000000,0.000000) [0.000000|3.000000] "" Motor_BEV
 SG_ ACC_Tempolimitassistent_Ein  : 90|1@1+ (1.000000,0.000000) [0.000000|1.000000] "" Vector__XXX
 SG_ ACC_FoD_Status  : 91|2@1+ (1.000000,0.000000) [0.000000|3.000000] "" Motor_BEV
 SG_ vESC_Verz_Anf  : 232|4@1+ (0.500000,0.000000) [0.000000|3.500000] "Unit_MeterPerSeconSquar" Vector__XXX
 SG_ RDR_v_ueber_Grund  : 236|12@1+ (0.100000,0.000000) [0.000000|409.000000] "Unit_KiloMeterPerHour" Vector__XXX
 SG_ RDR_v_ueber_Grund_Genauigkeit  : 248|6@1+ (0.100000,0.000000) [0.000000|6.000000] "Unit_KiloMeterPerHour" Vector__XXX
 SG_ RDR_v_ueber_Grund_Fahrtrichtung  : 254|2@1+ (1.000000,0.000000) [0.000000|3.000000] "" Vector__XXX

BO_ 2527679682 ACC_ASM_01: 8 ICAS1_Gateway
 SG_ ACC_ASM_Ereignis  : 0|8@1+ (1.000000,0.000000) [1.000000|254.000000] "" Airbag
 SG_ ACC_ASM_Zeitstempel  : 8|8@1+ (0.080000,0.000000) [0.000000|20.320000] "Unit_Secon" Airbag
 SG_ ACC_ASM_Data_1  : 16|8@1+ (1.000000,0.000000) [0.000000|255.000000] "" Airbag
 SG_ ACC_ASM_Data_2  : 24|8@1+ (1.000000,0.000000) [0.000000|255.000000] "" Airbag
 SG_ ACC_ASM_Data_3  : 32|8@1+ (1.000000,0.000000) [0.000000|255.000000] "" Airbag
 SG_ ACC_ASM_Data_4  : 40|8@1+ (1.000000,0.000000) [0.000000|255.000000] "" Airbag
 SG_ ACC_ASM_Data_5  : 48|8@1+ (1.000000,0.000000) [0.000000|255.000000] "" Airbag
 SG_ ACC_ASM_Data_6  : 56|8@1+ (1.000000,0.000000) [0.000000|255.000000] "" Airbag

BO_ 64 Airbag_01: 8 Airbag
 SG_ Airbag_01_CRC  : 0|8@1+ (1.000000,0.000000) [0.000000|255.000000] "" ICAS1_Gateway LE1 LE2 Motor_BEV
 SG_ Airbag_01_BZ  : 8|4@1+ (1.000000,0.000000) [0.000000|15.000000] "" ICAS1_Gateway LE1 LE2 Motor_BEV
 SG_ AB_RGS_Anst  : 12|4@1+ (1.000000,0.000000) [0.000000|15.000000] "" ICAS1_Gateway ICAS1_KommunikationsServer
 SG_ AB_Front_Crash  : 16|1@1+ (1.000000,0.000000) [0.000000|1.000000] "" ICAS1_Gateway
 SG_ AB_Heck_Crash  : 17|1@1+ (1.000000,0.000000) [0.000000|1.000000] "" ICAS1_Gateway
 SG_ AB_SF_Crash  : 18|1@1+ (1.000000,0.000000) [0.000000|1.000000] "" ICAS1_Gateway
 SG_ AB_SB_Crash  : 19|1@1+ (1.000000,0.000000) [0.000000|1.000000] "" ICAS1_Gateway
 SG_ AB_Rollover_Crash  : 20|1@1+ (1.000000,0.000000) [0.000000|1.000000] "" ICAS1_Gateway
 SG_ AB_Crash_Int  : 21|3@1+ (1.000000,0.000000) [0.000000|7.000000] "" ICAS1_Gateway ICAS1_KommunikationsServer Motor_BEV
 SG_ AB_Lampe  : 24|1@1+ (1.000000,0.000000) [0.000000|1.000000] "" ICAS1_Gateway ICAS1_KommunikationsServer
 SG_ AB_Deaktiviert  : 25|1@1+ (1.000000,0.000000) [0.000000|1.000000] "" ICAS1_Gateway
 SG_ AB_VB_deaktiviert  : 26|1@1+ (1.000000,0.000000) [0.000000|1.000000] "" ICAS1_Gateway
 SG_ AB_Systemfehler  : 27|1@1+ (1.000000,0.000000) [0.000000|1.000000] "" ICAS1_Gateway ICAS1_KommunikationsServer
 SG_ AB_Diagnose  : 28|1@1+ (1.000000,0.000000) [0.000000|1.000000] "" ICAS1_Gateway
 SG_ AB_Stellgliedtest  : 29|1@1+ (1.000000,0.000000) [0.000000|1.000000] "" ICAS1_Gateway
 SG_ AB_Erh_Auf_VB  : 30|2@1+ (1.000000,0.000000) [0.000000|3.000000] "" ICAS1_Gateway
 SG_ AB_Gurtwarn_VF  : 32|1@1+ (1.000000,0.000000) [0.000000|1.000000] "" ICAS1_Gateway ICAS1_KommunikationsServer
 SG_ AB_Gurtwarn_VB  : 33|1@1+ (1.000000,0.000000) [0.000000|1.000000] "" ICAS1_Gateway ICAS1_KommunikationsServer
 SG_ AB_Anzeige_Fussg  : 34|2@1+ (1.000000,0.000000) [0.000000|3.000000] "" ICAS1_Gateway
 SG_ AB_Texte_AKS  : 36|2@1+ (1.000000,0.000000) [0.000000|3.000000] "" ICAS1_Gateway
 SG_ AB_PAO_Leuchte_Anf  : 38|1@1+ (1.000000,0.000000) [0.000000|1.000000] "" ICAS1_Gateway
 SG_ AB_MKB_gueltig  : 39|1@1+ (1.000000,0.000000) [0.000000|1.000000] "" ICAS1_Gateway
 SG_ AB_MKB_Anforderung  : 40|1@1+ (1.000000,0.000000) [0.000000|1.000000] "" ICAS1_Gateway
 SG_ AB_Versorgungsspannung  : 41|1@1+ (1.000000,0.000000) [0.000000|1.000000] "" ICAS1_Gateway
 SG_ AB_Deaktivierung_HV  : 42|3@1+ (1.000000,0.000000) [0.000000|7.000000] "" ICAS1_Gateway ICAS1_KommunikationsServer LE1 LE2 Motor_BEV
 SG_ AB_EDR_Trigger  : 45|2@1+ (1.000000,0.000000) [0.000000|3.000000] "" ICAS1_Gateway
 SG_ AB_Belegung_VF  : 47|2@1+ (1.000000,0.000000) [0.000000|3.000000] "" ICAS1_Gateway
 SG_ AB_Gurtschloss_FA_ext  : 49|3@1+ (1.000000,0.000000) [0.000000|7.000000] "" ICAS1_Gateway
 SG_ AB_Belegung_VF_ext  : 52|3@1+ (1.000000,0.000000) [0.000000|7.000000] "" ICAS1_Gateway
 SG_ ASM_Masterzeit  : 56|8@1+ (0.080000,0.000000) [0.000000|20.320000] "Unit_Secon" ICAS1_Gateway

BO_ 1312 Airbag_02: 8 Airbag
 SG_ Airbag_02_CRC  : 0|8@1+ (1.000000,0.000000) [0.000000|255.000000] "" ICAS1_Gateway Motor_BEV
 SG_ Airbag_02_BZ  : 8|4@1+ (1.000000,0.000000) [0.000000|15.000000] "" ICAS1_Gateway Motor_BEV
 SG_ LoGeWa_Event_Kombiwarnung  : 12|4@1+ (1.000000,0.000000) [0.000000|15.000000] "" ICAS1_Gateway
 SG_ AB_Anforderung_eCall  : 16|1@1+ (1.000000,0.000000) [0.000000|1.000000] "" ICAS1_Gateway
 SG_ AB_Anprall_Seite_Beifahrer  : 17|1@1+ (1.000000,0.000000) [0.000000|1.000000] "" ICAS1_Gateway ICAS1_KommunikationsServer
 SG_ AB_Anprall_Rollover  : 18|1@1+ (1.000000,0.000000) [0.000000|1.000000] "" ICAS1_Gateway ICAS1_KommunikationsServer
 SG_ AB_Anprall_FGS  : 19|1@1+ (1.000000,0.000000) [0.000000|1.000000] "" ICAS1_Gateway ICAS1_KommunikationsServer
 SG_ AB_Anprall_Front_Beifahrer  : 20|1@1+ (1.000000,0.000000) [0.000000|1.000000] "" ICAS1_Gateway ICAS1_KommunikationsServer
 SG_ AB_Anprall_Front_Fahrer  : 21|1@1+ (1.000000,0.000000) [0.000000|1.000000] "" ICAS1_Gateway ICAS1_KommunikationsServer
 SG_ AB_Anprall_Heck_Beifahrer  : 22|1@1+ (1.000000,0.000000) [0.000000|1.000000] "" ICAS1_Gateway ICAS1_KommunikationsServer
 SG_ AB_Anprall_Heck_Fahrer  : 23|1@1+ (1.000000,0.000000) [0.000000|1.000000] "" ICAS1_Gateway ICAS1_KommunikationsServer
 SG_ AB_Wickelklappung_Reihe2_MI  : 24|2@1+ (1.000000,0.000000) [0.000000|3.000000] "" ICAS1_Gateway
 SG_ AB_Belegung_VB  : 26|2@1+ (1.000000,0.000000) [0.000000|3.000000] "" ICAS1_Gateway
 SG_ AB_Abschaltanf_SIH_BF  : 28|1@1+ (1.000000,0.000000) [0.000000|1.000000] "" ICAS1_Gateway
 SG_ AB_Anprall_Seite_Fahrer  : 29|1@1+ (1.000000,0.000000) [0.000000|1.000000] "" ICAS1_Gateway ICAS1_KommunikationsServer
 SG_ SC_PAO_Schriftzug_Anf  : 30|2@1+ (1.000000,0.000000) [0.000000|3.000000] "" ICAS1_Gateway
 SG_ SC_PAO_ON_Anf  : 32|2@1+ (1.000000,0.000000) [0.000000|3.000000] "" ICAS1_Gateway
 SG_ SC_PAO_OFF_Anf  : 34|2@1+ (1.000000,0.000000) [0.000000|3.000000] "" ICAS1_Gateway
 SG_ AB_Crashschwere  : 36|3@1+ (1.000000,0.000000) [0.000000|7.000000] "" ICAS1_Gateway ICAS1_KommunikationsServer
 SG_ AB_Anforderung_USM  : 39|1@1+ (1.000000,0.000000) [0.000000|1.000000] "" ICAS1_Gateway
 SG_ AB_Gurtschloss_FA  : 40|2@1+ (1.000000,0.000000) [0.000000|3.000000] "" ICAS1_Gateway ICAS1_KommunikationsServer Motor_BEV
 SG_ AB_Gurtschloss_BF  : 42|2@1+ (1.000000,0.000000) [0.000000|3.000000] "" ICAS1_Gateway ICAS1_KommunikationsServer
 SG_ AB_Gurtschloss_Reihe2_FA  : 44|2@1+ (1.000000,0.000000) [0.000000|3.000000] "" ICAS1_Gateway ICAS1_KommunikationsServer
 SG_ AB_Gurtschloss_Reihe2_MI  : 46|2@1+ (1.000000,0.000000) [0.000000|3.000000] "" ICAS1_Gateway ICAS1_KommunikationsServer
 SG_ AB_Gurtschloss_Reihe2_BF  : 48|2@1+ (1.000000,0.000000) [0.000000|3.000000] "" ICAS1_Gateway ICAS1_KommunikationsServer
 SG_ AB_Gurtschloss_Reihe3_FA  : 50|2@1+ (1.000000,0.000000) [0.000000|3.000000] "" ICAS1_Gateway ICAS1_KommunikationsServer
 SG_ AB_Gurtschloss_Reihe3_MI  : 52|2@1+ (1.000000,0.000000) [0.000000|3.000000] "" ICAS1_Gateway ICAS1_KommunikationsServer
 SG_ AB_Gurtschloss_Reihe3_BF  : 54|2@1+ (1.000000,0.000000) [0.000000|3.000000] "" ICAS1_Gateway ICAS1_KommunikationsServer
 SG_ AB_Sitzpos_Sens_FA  : 56|2@1+ (1.000000,0.000000) [0.000000|3.000000] "" ICAS1_Gateway
 SG_ AB_Sitzpos_Sens_BF  : 58|2@1+ (1.000000,0.000000) [0.000000|3.000000] "" ICAS1_Gateway
 SG_ AB_Wickelklappung_Reihe2_BF  : 60|2@1+ (1.000000,0.000000) [0.000000|3.000000] "" ICAS1_Gateway
 SG_ AB_Wickelklappung_Reihe2_FA  : 62|2@1+ (1.000000,0.000000) [0.000000|3.000000] "" ICAS1_Gateway

BO_ 65 Airbag_03: 8 Airbag
 SG_ Airbag_03_CRC  : 0|8@1+ (1.000000,0.000000) [0.000000|255.000000] "" ICAS1_Gateway
 SG_ Airbag_03_BZ  : 8|4@1+ (1.000000,0.000000) [0.000000|15.000000] "" ICAS1_Gateway
 SG_ AB_MKB_Safing  : 63|1@1+ (1.000000,0.000000) [0.000000|1.000000] "" ICAS1_Gateway

BO_ 1349 Airbag_04: 8 Airbag
 SG_ AB_Gurtwarn_Reihe4_FA  : 14|2@1+ (1.000000,0.000000) [0.000000|3.000000] "" ICAS1_Gateway ICAS1_KommunikationsServer
 SG_ AB_Gurtwarn_Reihe4_BF  : 16|2@1+ (1.000000,0.000000) [0.000000|3.000000] "" ICAS1_Gateway ICAS1_KommunikationsServer
 SG_ AB_Gurtwarn_Reihe4_MI  : 18|2@1+ (1.000000,0.000000) [0.000000|3.000000] "" ICAS1_Gateway ICAS1_KommunikationsServer
 SG_ AB_Gurtwarn_Reihe2_FA  : 20|2@1+ (1.000000,0.000000) [0.000000|3.000000] "" ICAS1_Gateway ICAS1_KommunikationsServer
 SG_ AB_Gurtwarn_Reihe2_BF  : 22|2@1+ (1.000000,0.000000) [0.000000|3.000000] "" ICAS1_Gateway ICAS1_KommunikationsServer
 SG_ AbstWarn_MV_FAS_Fkt_Status  : 24|2@1+ (1.000000,0.000000) [0.000000|3.000000] "" ICAS1_Gateway
 SG_ WarnBrems_Charisma_Status  : 26|2@1+ (1.000000,0.000000) [0.000000|3.000000] "" ICAS1_Gateway
 SG_ WarnBrems_Charisma_FahrPr  : 28|4@1+ (1.000000,0.000000) [0.000000|15.000000] "" ICAS1_Gateway
 SG_ AB_Gurtwarn_Reihe2_MI  : 32|2@1+ (1.000000,0.000000) [0.000000|3.000000] "" ICAS1_Gateway ICAS1_KommunikationsServer
 SG_ AB_Gurtwarn_Reihe3_FA  : 34|2@1+ (1.000000,0.000000) [0.000000|3.000000] "" ICAS1_Gateway ICAS1_KommunikationsServer
 SG_ AB_Gurtwarn_Reihe3_MI  : 36|2@1+ (1.000000,0.000000) [0.000000|3.000000] "" ICAS1_Gateway ICAS1_KommunikationsServer
 SG_ AB_Gurtwarn_Reihe3_BF  : 38|2@1+ (1.000000,0.000000) [0.000000|3.000000] "" ICAS1_Gateway ICAS1_KommunikationsServer
 SG_ LGI_FAS_Fkt_Status  : 40|2@1+ (1.000000,0.000000) [0.000000|3.000000] "" ICAS1_Gateway
 SG_ PreCrash_FAS_Fkt_Status  : 42|3@1+ (1.000000,0.000000) [0.000000|7.000000] "" ICAS1_Gateway
 SG_ AB_SBR_hinten_verbau  : 48|2@1+ (1.000000,0.000000) [0.000000|3.000000] "" ICAS1_Gateway ICAS1_KommunikationsServer
 SG_ AWV_Einstellung_System_ASG  : 51|1@1+ (1.000000,0.000000) [0.000000|1.000000] "" ICAS1_Gateway
 SG_ AWV_Einstellung_Warnung_ASG  : 52|3@1+ (1.000000,0.000000) [0.000000|7.000000] "" ICAS1_Gateway
 SG_ SC_PreSense_Modus_Warnung_NV  : 55|3@1+ (1.000000,0.000000) [0.000000|7.000000] "" ICAS1_Gateway
 SG_ SC_PreSense_Modus_Warnung_MV  : 58|3@1+ (1.000000,0.000000) [0.000000|7.000000] "" ICAS1_Gateway
 SG_ SC_PreSense_Modus_System_MV  : 61|1@1+ (1.000000,0.000000) [0.000000|1.000000] "" ICAS1_Gateway
 SG_ SC_PreSense_Modus_System_NV  : 62|1@1+ (1.000000,0.000000) [0.000000|1.000000] "" ICAS1_Gateway
 SG_ SC_PreSense_Modus_System_KAS  : 63|1@1+ (1.000000,0.000000) [0.000000|1.000000] "" ICAS1_Gateway

BO_ 2527679722 Airbag_06: 8 Airbag
 SG_ AB_Gurtschloss_Reihe4_FA  : 12|2@1+ (1.000000,0.000000) [0.000000|3.000000] "" ICAS1_Gateway ICAS1_KommunikationsServer
 SG_ AB_Gurtschloss_Reihe4_BF  : 14|2@1+ (1.000000,0.000000) [0.000000|3.000000] "" ICAS1_Gateway ICAS1_KommunikationsServer
 SG_ AB_Gurtschloss_Reihe4_MI  : 16|2@1+ (1.000000,0.000000) [0.000000|3.000000] "" ICAS1_Gateway ICAS1_KommunikationsServer

BO_ 1633 Anhaenger_01: 8 ICAS1_Gateway
 SG_ AAG_BZ  : 0|4@1+ (1.000000,0.000000) [0.000000|15.000000] "" Vector__XXX
 SG_ AAG_AVS_Fehler_02_inv  : 4|1@1+ (1.000000,0.000000) [0.000000|1.000000] "" Vector__XXX
 SG_ AAG_Bremsl_durch_ECD  : 5|1@1+ (1.000000,0.000000) [0.000000|1.000000] "" Motor_BEV
 SG_ AAG_Anhaenger_abgesteckt  : 6|1@1+ (1.000000,0.000000) [0.000000|1.000000] "" Motor_BEV
 SG_ AAG_NSL_aktiv  : 7|1@1+ (1.000000,0.000000) [0.000000|1.000000] "" Vector__XXX
 SG_ AAG_Anhaenger_erkannt  : 8|1@1+ (1.000000,0.000000) [0.000000|1.000000] "" Motor_BEV
 SG_ AAG_Blinker_H_aktiv  : 9|1@1+ (1.000000,0.000000) [0.000000|1.000000] "" Vector__XXX
 SG_ AAG_Blinker_HL_def  : 10|1@1+ (1.000000,0.000000) [0.000000|1.000000] "" Vector__XXX
 SG_ AAG_Blinker_HR_def  : 11|1@1+ (1.000000,0.000000) [0.000000|1.000000] "" Vector__XXX
 SG_ AAG_Bremslicht_H_def  : 12|1@1+ (1.000000,0.000000) [0.000000|1.000000] "" Motor_BEV
 SG_ AAG_Schlusslicht_HL_def  : 13|1@1+ (1.000000,0.000000) [0.000000|1.000000] "" Vector__XXX
 SG_ AAG_Schlusslicht_HR_def  : 14|1@1+ (1.000000,0.000000) [0.000000|1.000000] "" Vector__XXX
 SG_ AAG_Bremslicht_Reku  : 15|1@1+ (1.000000,0.000000) [0.000000|1.000000] "" Vector__XXX
 SG_ AAG_AVS_Fehler_02  : 18|1@1+ (1.000000,0.000000) [0.000000|1.000000] "" Vector__XXX
 SG_ AAG_LED_aktiv  : 19|1@1+ (1.000000,0.000000) [0.000000|1.000000] "" Vector__XXX
 SG_ AAG_AVS_Stati  : 20|4@1+ (1.000000,0.000000) [0.000000|15.000000] "" Vector__XXX

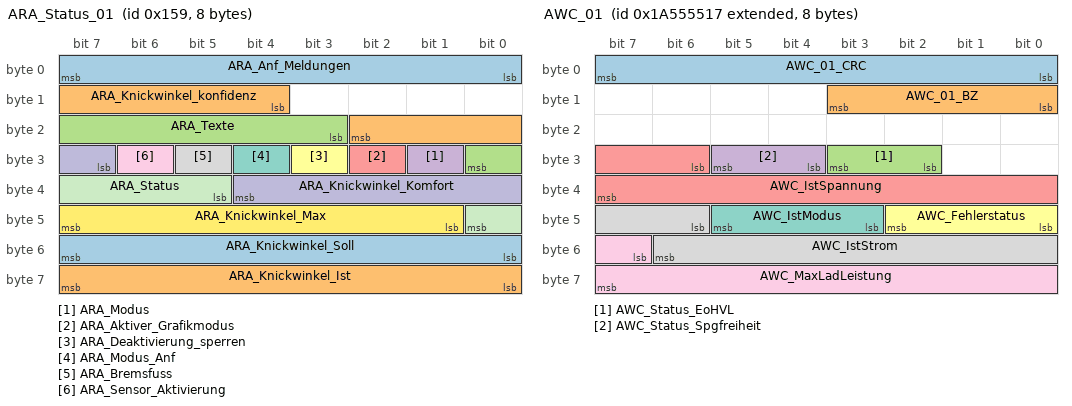
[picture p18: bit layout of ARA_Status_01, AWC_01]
BO_ 345 ARA_Status_01: 8 ICAS1_Gateway
 SG_ ARA_Anf_Meldungen  : 0|8@1+ (1.000000,0.000000) [0.000000|255.000000] "" Vector__XXX
 SG_ ARA_Knickwinkel_konfidenz  : 12|7@1+ (1.000000,0.000000) [0.000000|120.000000] "Unit_DegreOfArc" Vector__XXX
 SG_ ARA_Texte  : 19|6@1+ (1.000000,0.000000) [0.000000|63.000000] "" Vector__XXX
 SG_ ARA_Modus  : 25|1@1+ (1.000000,0.000000) [0.000000|1.000000] "" Vector__XXX
 SG_ ARA_Aktiver_Grafikmodus  : 26|1@1+ (1.000000,0.000000) [0.000000|1.000000] "" Vector__XXX
 SG_ ARA_Deaktivierung_sperren  : 27|1@1+ (1.000000,0.000000) [0.000000|1.000000] "" Vector__XXX
 SG_ ARA_Modus_Anf  : 28|1@1+ (1.000000,0.000000) [0.000000|1.000000] "" Vector__XXX
 SG_ ARA_Bremsfuss  : 29|1@1+ (1.000000,0.000000) [0.000000|1.000000] "" Vector__XXX
 SG_ ARA_Sensor_Aktivierung  : 30|1@1+ (1.000000,0.000000) [0.000000|1.000000] "" Vector__XXX
 SG_ ARA_Knickwinkel_Komfort  : 31|6@1+ (1.000000,0.000000) [0.000000|60.000000] "Unit_DegreOfArc" Vector__XXX
 SG_ ARA_Status  : 37|4@1+ (1.000000,0.000000) [0.000000|15.000000] "" Motor_BEV
 SG_ ARA_Knickwinkel_Max  : 41|7@1+ (1.000000,0.000000) [0.000000|120.000000] "Unit_DegreOfArc" Vector__XXX
 SG_ ARA_Knickwinkel_Soll  : 48|8@1+ (1.000000,-125.000000) [-125.000000|126.000000] "Unit_DegreOfArc" Vector__XXX
 SG_ ARA_Knickwinkel_Ist  : 56|8@1+ (1.000000,-125.000000) [-125.000000|126.000000] "Unit_DegreOfArc" Vector__XXX

BO_ 2589283607 AWC_01: 8 ICAS1_Gateway
 SG_ AWC_01_CRC  : 0|8@1+ (1.000000,0.000000) [0.000000|255.000000] "" Vector__XXX
 SG_ AWC_01_BZ  : 8|4@1+ (1.000000,0.000000) [0.000000|15.000000] "" Vector__XXX
 SG_ AWC_Status_EoHVL  : 26|2@1+ (1.000000,0.000000) [0.000000|3.000000] "" Motor_BEV
 SG_ AWC_Status_Spgfreiheit  : 28|2@1+ (1.000000,0.000000) [0.000000|3.000000] "" Vector__XXX
 SG_ AWC_IstSpannung  : 30|10@1+ (1.000000,0.000000) [0.000000|1021.000000] "Unit_Volt" Vector__XXX
 SG_ AWC_Fehlerstatus  : 40|3@1+ (1.000000,0.000000) [0.000000|7.000000] "" Vector__XXX
 SG_ AWC_IstModus  : 43|3@1+ (1.000000,0.000000) [0.000000|7.000000] "" Vector__XXX
 SG_ AWC_IstStrom  : 46|9@1+ (0.100000,0.000000) [0.000000|50.900000] "Unit_Amper" Vector__XXX
 SG_ AWC_MaxLadLeistung  : 55|9@1+ (25.000000,0.000000) [0.000000|12725.000000] "Unit_Watt" Vector__XXX

BO_ 219 AWV_03: 48 ICAS1_Gateway
 SG_ AWV_03_CRC  : 0|8@1+ (1.000000,0.000000) [0.000000|255.000000] "" Airbag
 SG_ AWV_03_BZ  : 8|4@1+ (1.000000,0.000000) [0.000000|15.000000] "" Airbag
 SG_ PCF_Freigabe  : 12|1@1+ (1.000000,0.000000) [0.000000|1.000000] "" Airbag
 SG_ SDF_PSF_Objektstatus  : 13|3@1+ (1.000000,0.000000) [0.000000|7.000000] "" Airbag
 SG_ SDF_PSF_CU_Status  : 16|1@1+ (1.000000,0.000000) [0.000000|1.000000] "" Airbag
 SG_ SDF_PSF_CW  : 17|7@1+ (1.000000,0.000000) [0.000000|100.000000] "" Airbag
 SG_ SDF_PSF_Fahrer_aktiv  : 24|1@1+ (1.000000,0.000000) [0.000000|1.000000] "" Airbag
 SG_ SDF_PSF_Guete  : 25|2@1+ (1.000000,0.000000) [0.000000|3.000000] "" Airbag
 SG_ SDF_PSF_Kollisionsueberdeckung  : 27|5@1+ (0.100000,0.000000) [0.100000|2.800000] "Unit_Meter" Airbag
 SG_ SDF_PSF_Time_To_Collision  : 32|8@1+ (0.010000,0.000000) [0.000000|2.500000] "Unit_Secon" Vector__XXX
 SG_ SDF_PSF_v_rel  : 40|8@1+ (0.400000,0.000000) [0.400000|101.200000] "Unit_MeterPerSecon" Airbag
 SG_ AWV_Eingriff_Sendeart  : 64|1@1+ (1.000000,0.000000) [0.000000|1.000000] "" Airbag
 SG_ AWV_Verz_Freigabe  : 65|1@1+ (1.000000,0.000000) [0.000000|1.000000] "" Airbag
 SG_ AWV_Verz_Anf  : 66|10@1+ (0.024000,-20.016000) [-20.016000|4.512000] "Unit_MeterPerSeconSquar" Airbag
 SG_ AWV_Anf_Prefill  : 76|1@1+ (1.000000,0.000000) [0.000000|1.000000] "" Airbag
 SG_ AWV_Ruckprofil  : 77|3@1+ (1.000000,0.000000) [0.000000|7.000000] "" Vector__XXX
 SG_ AWV_Time_to_collision  : 80|8@1+ (0.010000,0.000000) [0.000000|2.500000] "Unit_Secon" Airbag
 SG_ AWV_HBA_Param  : 88|2@1+ (1.000000,0.000000) [0.000000|3.000000] "" Vector__XXX
 SG_ AWV_Verz_Anf_ASIL  : 90|3@1+ (1.000000,0.000000) [0.000000|7.000000] "" Vector__XXX
 SG_ AWV_Time_to_brake  : 93|7@1+ (10.000000,0.000000) [0.000000|1240.000000] "Unit_MilliSecon" Vector__XXX
 SG_ AWV_Zielobjekttyp  : 100|4@1+ (1.000000,0.000000) [0.000000|15.000000] "" Airbag
 SG_ AWV_QFK_KruemmSoll  : 104|15@1+ (0.000007,0.000000) [0.000000|0.219539] "Unit_MeterInver" Vector__XXX
 SG_ AWV_QFK_KruemmSoll_VZ  : 119|1@1+ (1.000000,0.000000) [0.000000|1.000000] "" Vector__XXX
 SG_ AWV_QFK_Spuerb  : 120|8@1+ (0.400000,0.000000) [0.000000|100.000000] "Unit_PerCent" Vector__XXX
 SG_ AWV_QFK_AnfStat  : 128|4@1+ (1.000000,0.000000) [0.000000|15.000000] "" Airbag
 SG_ AWV_QFK_Signal1  : 132|10@1+ (1.000000,0.000000) [0.000000|1023.000000] "" Vector__XXX
 SG_ AWV_QFK_Art1  : 142|3@1+ (1.000000,0.000000) [0.000000|7.000000] "" Vector__XXX
 SG_ AWV_QFK_Art2  : 145|3@1+ (1.000000,0.000000) [0.000000|7.000000] "" Vector__XXX
 SG_ AWV_QFK_Signal2  : 148|10@1+ (1.000000,0.000000) [0.000000|1023.000000] "" Vector__XXX

BO_ 2536767264 BAP_Debug_Cmd: 8 BAP_Tester
 SG_ BAP_Debug_Cmd  : 0|16@1+ (1.000000,0.000000) [0.000000|65535.000000] "" Motor_BEV

BO_ 2536767280 BAP_Debug_Data: 8 Motor_BEV
 SG_ BAP_Debug_Data  : 0|64@1+ (1.000000,0.000000) [0.000000|18446744073709551616.000000] "" BAP_Tester

BO_ 2536717313 BAP_EfficiencyAssist_ASG_02: 8 ICAS1_Gateway
 SG_ BAP_EfficAssist_ASG_02_Header  : 0|64@1+ (1.000000,0.000000) [0.000000|18446744073709551616.000000] "" Motor_BEV

BO_ 2536717314 BAP_EfficiencyAssist_ASG_03: 8 ICAS1_Gateway
 SG_ BAP_EfficAssist_ASG_03_Header  : 0|8@1+ (1.000000,0.000000) [0.000000|255.000000] "" Motor_BEV

BO_ 2536717328 BAP_EfficiencyAssist_FSG_01: 8 Motor_BEV
 SG_ BAP_EfficAssist_FSG_01_Header  : 0|8@1+ (1.000000,0.000000) [0.000000|255.000000] "" ICAS1_Gateway

BO_ 2536709120 BAP_Hybrid_ASG_01: 8 ICAS1_Gateway
 SG_ BAP_Hybrid_ASG_01_Header  : 0|8@1+ (1.000000,0.000000) [0.000000|255.000000] "" Motor_BEV

BO_ 2536709136 BAP_Hybrid_FSG_01: 8 Motor_BEV
 SG_ BAP_Hybrid_FSG_01_Header  : 0|8@1+ (1.000000,0.000000) [0.000000|255.000000] "" ICAS1_Gateway

BO_ 869 BEM_05: 8 ICAS1_Gateway
 SG_ BEM_UBDM  : 0|8@1+ (0.050000,5.000000) [5.050000|17.700000] "Unit_Volt" Vector__XXX
 SG_ NVEM_Ladefreigabe  : 8|2@1+ (1.000000,0.000000) [0.000000|3.000000] "" Vector__XXX
 SG_ NVEM_FMAus_Info  : 10|2@1+ (1.000000,0.000000) [0.000000|3.000000] "" Vector__XXX
 SG_ NVEM_PTC_Sollstufe  : 12|2@1+ (1.000000,0.000000) [0.000000|3.000000] "" Vector__XXX
 SG_ NVEM_P_Generator_Status  : 15|1@1+ (1.000000,0.000000) [0.000000|1.000000] "" Vector__XXX
 SG_ BEM_P_Generator  : 16|8@1+ (50.000000,0.000000) [0.000000|12700.000000] "Unit_Watt" Vector__XXX
 SG_ BEM_n_LLA  : 24|2@1+ (1.000000,0.000000) [0.000000|3.000000] "" Vector__XXX
 SG_ BEM_01_Abschaltstufen  : 26|3@1+ (1.000000,0.000000) [0.000000|7.000000] "" Vector__XXX
 SG_ BEM_Anf_KL  : 29|1@1+ (1.000000,0.000000) [0.000000|1.000000] "" Vector__XXX
 SG_ BEM_StartStopp_Info  : 30|2@1+ (1.000000,0.000000) [0.000000|3.000000] "" Vector__XXX
 SG_ BEM_DFM  : 32|5@1+ (3.225000,0.025000) [0.025000|100.000000] "" Vector__XXX
 SG_ BEM_EMLIN_ungueltig  : 37|1@1+ (1.000000,0.000000) [0.000000|1.000000] "" Vector__XXX
 SG_ BEM_Batt_Ab  : 38|1@1+ (1.000000,0.000000) [0.000000|1.000000] "" Motor_BEV
 SG_ NVEM_FMAus_I_Verbrauch  : 39|5@1+ (5.000000,0.000000) [0.000000|145.000000] "Unit_Amper" Vector__XXX
 SG_ NVEM_Freilauf_Info  : 44|2@1+ (1.000000,0.000000) [0.000000|3.000000] "" Vector__XXX
 SG_ BEM_NV_NachladAnf  : 46|2@1+ (1.000000,0.000000) [0.000000|3.000000] "" Vector__XXX
 SG_ BEM_Segel_Info  : 48|2@1+ (1.000000,0.000000) [0.000000|3.000000] "" Vector__XXX
 SG_ BEM_HYB_DC_uSollLV  : 50|6@1+ (0.100000,10.600000) [10.600000|16.000000] "Unit_Volt" Vector__XXX
 SG_ BEM_HYB_DC_uMinLV  : 56|8@1+ (0.100000,0.000000) [0.000000|25.300000] "Unit_Volt" Vector__XXX

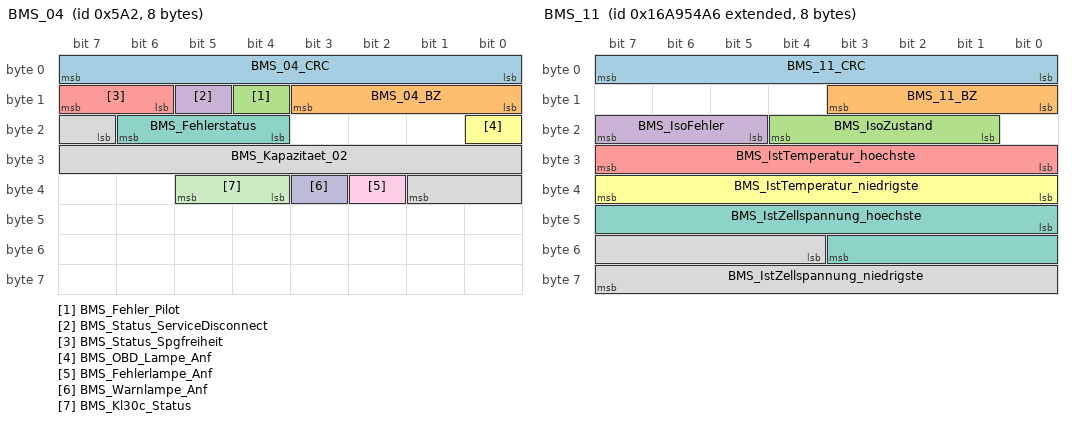
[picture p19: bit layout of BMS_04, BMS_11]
BO_ 1442 BMS_04: 8 ICAS1_Gateway
 SG_ BMS_04_CRC  : 0|8@1+ (1.000000,0.000000) [0.000000|255.000000] "" Vector__XXX
 SG_ BMS_04_BZ  : 8|4@1+ (1.000000,0.000000) [0.000000|15.000000] "" Vector__XXX
 SG_ BMS_Fehler_Pilot  : 12|1@1+ (1.000000,0.000000) [0.000000|1.000000] "" Vector__XXX
 SG_ BMS_Status_ServiceDisconnect  : 13|1@1+ (1.000000,0.000000) [0.000000|1.000000] "" Vector__XXX
 SG_ BMS_Status_Spgfreiheit  : 14|2@1+ (1.000000,0.000000) [0.000000|3.000000] "" Motor_BEV
 SG_ BMS_OBD_Lampe_Anf  : 16|1@1+ (1.000000,0.000000) [0.000000|1.000000] "" Motor_BEV
 SG_ BMS_Fehlerstatus  : 20|3@1+ (1.000000,0.000000) [0.000000|7.000000] "" Vector__XXX
 SG_ BMS_Kapazitaet_02  : 23|11@1+ (0.200000,0.000000) [0.000000|409.200000] "Unit_AmperHour" Vector__XXX
 SG_ BMS_Fehlerlampe_Anf  : 34|1@1+ (1.000000,0.000000) [0.000000|1.000000] "" Motor_BEV
 SG_ BMS_Warnlampe_Anf  : 35|1@1+ (1.000000,0.000000) [0.000000|1.000000] "" Motor_BEV
 SG_ BMS_Kl30c_Status  : 36|2@1+ (1.000000,0.000000) [0.000000|3.000000] "" Motor_BEV

BO_ 2527679654 BMS_11: 8 ICAS1_Gateway
 SG_ BMS_11_CRC  : 0|8@1+ (1.000000,0.000000) [0.000000|255.000000] "" Motor_BEV
 SG_ BMS_11_BZ  : 8|4@1+ (1.000000,0.000000) [0.000000|15.000000] "" Motor_BEV
 SG_ BMS_IsoZustand  : 17|4@1+ (1.000000,0.000000) [0.000000|15.000000] "" Motor_BEV
 SG_ BMS_IsoFehler  : 21|3@1+ (1.000000,0.000000) [0.000000|7.000000] "" Motor_BEV
 SG_ BMS_IstTemperatur_hoechste  : 24|8@1+ (0.500000,-40.000000) [-40.000000|86.000000] "Unit_DegreCelsi" Vector__XXX
 SG_ BMS_IstTemperatur_niedrigste  : 32|8@1+ (0.500000,-40.000000) [-40.000000|86.000000] "Unit_DegreCelsi" Vector__XXX
 SG_ BMS_IstZellspannung_hoechste  : 40|12@1+ (1.000000,1000.000000) [1000.000000|5091.000000] "Unit_MilliVolt" Vector__XXX
 SG_ BMS_IstZellspannung_niedrigste  : 52|12@1+ (1.000000,1000.000000) [1000.000000|5091.000000] "Unit_MilliVolt" Vector__XXX
